VERSION ""

NS_ :

BS_:

BU_: L_3HKBD L_DIG L_FHPTC L_ATCU L_2HKBD L_PCM L_ATCU_vMON L_EVNT L_HKBD L_RHPTC

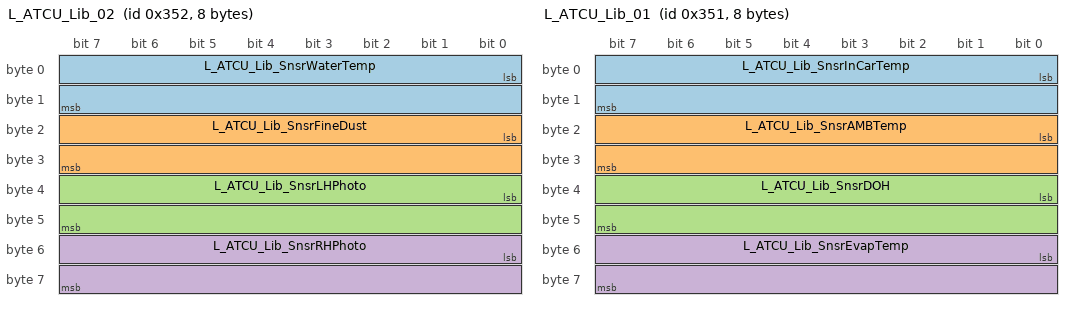
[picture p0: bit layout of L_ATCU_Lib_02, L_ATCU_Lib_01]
BO_ 850 L_ATCU_Lib_02: 8 L_ATCU
 SG_ L_ATCU_Lib_SnsrWaterTemp : 0|16@1+ (0.01,-48) [-48|200] "¡É"  L_ATCU_vMON
 SG_ L_ATCU_Lib_SnsrFineDust : 16|16@1+ (1,0) [0|255] ""  L_ATCU_vMON
 SG_ L_ATCU_Lib_SnsrLHPhoto : 32|16@1+ (0.001,0) [0|5] "V"  L_ATCU_vMON
 SG_ L_ATCU_Lib_SnsrRHPhoto : 48|16@1+ (0.001,0) [0|5] "V"  L_ATCU_vMON

BO_ 100 L_2HKBD_04: 8 L_2HKBD
 SG_ L_2HKBD_RrDrModeDnSw : 0|1@1+ (1,0) [0|0] ""  L_ATCU
 SG_ L_2HKBD_RrDrModeUpSw : 1|1@1+ (1,0) [0|0] ""  L_ATCU
 SG_ L_2HKBD_RrDrAutoSw : 10|1@1+ (1,0) [0|0] ""  L_ATCU
 SG_ L_2HKBD_Rr_OffSw : 11|1@1+ (1,0) [0|0] ""  L_ATCU
 SG_ L_2HKBD_RrSyncSw : 12|1@1+ (1,0) [0|0] ""  L_ATCU
 SG_ L_2HKBD_RrAcSw : 13|1@1+ (1,0) [0|0] ""  L_ATCU
 SG_ L_2HKBD_RLStHtrSwReq : 14|1@1+ (1,0) [0|0] ""  L_ATCU
 SG_ L_2HKBD_RLStVentSwReq : 15|1@1+ (1,0) [0|0] ""  L_ATCU
 SG_ L_2HKBD_RRStHtrSwReq : 16|1@1+ (1,0) [0|0] ""  L_ATCU
 SG_ L_2HKBD_RRStVentSwReq : 17|1@1+ (1,0) [0|0] ""  L_ATCU
 SG_ L_2HKBD_RrDrMultiAutoSw : 18|3@1+ (1,0) [0|0] ""  L_ATCU
 SG_ L_2HKBD_RrDrModeSw : 2|1@1+ (1,0) [0|0] ""  L_ATCU
 SG_ L_2HKBD_RrPsModeSw : 21|1@1+ (1,0) [0|0] ""  L_ATCU
 SG_ L_2HKBD_RrPsModeDnSw : 22|1@1+ (1,0) [0|0] ""  L_ATCU
 SG_ L_2HKBD_RrPsModeUpSw : 23|1@1+ (1,0) [0|0] ""  L_ATCU
 SG_ L_2HKBD_RrPsModeVentSw : 24|1@1+ (1,0) [0|0] ""  L_ATCU
 SG_ L_2HKBD_RrPsModeFloorSw : 25|1@1+ (1,0) [0|0] ""  L_ATCU
 SG_ L_2HKBD_RrPsModeBiLvlSw : 26|1@1+ (1,0) [0|0] ""  L_ATCU
 SG_ L_2HKBD_RrPsTempDnSw : 27|1@1+ (1,0) [0|0] ""  L_ATCU
 SG_ L_2HKBD_RrPsTempUpSw : 28|1@1+ (1,0) [0|0] ""  L_ATCU
 SG_ L_2HKBD_RrPsBlwUpSw : 29|1@1+ (1,0) [0|0] ""  L_ATCU
 SG_ L_2HKBD_RrDRModeVentSw : 3|1@1+ (1,0) [0|0] ""  L_ATCU
 SG_ L_2HKBD_RrPsBlwDnSw : 30|1@1+ (1,0) [0|0] ""  L_ATCU
 SG_ L_2HKBD_RrPsAutoSw : 31|1@1+ (1,0) [0|0] ""  L_ATCU
 SG_ L_2HKBD_RrPsMultiAutoSw : 32|3@1+ (1,0) [0|0] ""  L_ATCU
 SG_ L_2HKBD_RrDrBlwDnOffSw : 35|1@1+ (1,0) [0|0] ""  L_ATCU
 SG_ L_2HKBD_RrPsBlwDnOffSw : 36|1@1+ (1,0) [0|0] ""  L_ATCU
 SG_ L_2HKBD_RrOnOffSet : 37|2@1+ (1,0) [0|0] ""  L_ATCU
 SG_ L_2HKBD_RrDrblwUpMaxSw : 39|1@1+ (1,0) [0|0] ""  L_ATCU
 SG_ L_2HKBD_RrDrModeFloorSw : 4|1@1+ (1,0) [0|0] ""  L_ATCU
 SG_ L_2HKBD_RrPsblwUpMaxSw : 40|1@1+ (1,0) [0|0] ""  L_ATCU
 SG_ L_2HKBD_RrDrModeBiLvlSw : 5|1@1+ (1,0) [0|0] ""  L_ATCU
 SG_ L_2HKBD_RrDrTempDnSw : 6|1@1+ (1,0) [0|0] ""  L_ATCU
 SG_ L_2HKBD_RrDrTempUpSw : 7|1@1+ (1,0) [0|0] ""  L_ATCU
 SG_ L_2HKBD_RrDrBlwDnSw : 8|1@1+ (1,0) [0|0] ""  L_ATCU
 SG_ L_2HKBD_RrDrBlwUpSw : 9|1@1+ (1,0) [0|0] ""  L_ATCU

BO_ 849 L_ATCU_Lib_01: 8 L_ATCU
 SG_ L_ATCU_Lib_SnsrInCarTemp : 0|16@1+ (0.1,-40) [-40|60] "¡É"  L_ATCU_vMON
 SG_ L_ATCU_Lib_SnsrAMBTemp : 16|16@1+ (0.1,-40) [-40|60] "¡É"  L_ATCU_vMON
 SG_ L_ATCU_Lib_SnsrDOH : 32|16@1+ (1,0) [0|100] "%"  L_ATCU_vMON
 SG_ L_ATCU_Lib_SnsrEvapTemp : 48|16@1+ (0.1,-20) [-20|40] "¡É"  L_ATCU_vMON

BO_ 101 L_2HKBD_05: 8 L_2HKBD
 SG_ L_2HKBD_RrFlrDuctSnsr : 0|8@1+ (0.02,0) [0|0] "V"  L_ATCU
 SG_ L_2HKBD_RrVntDuctSnsr : 9|8@1+ (0.02,0) [0|0] "V"  L_ATCU

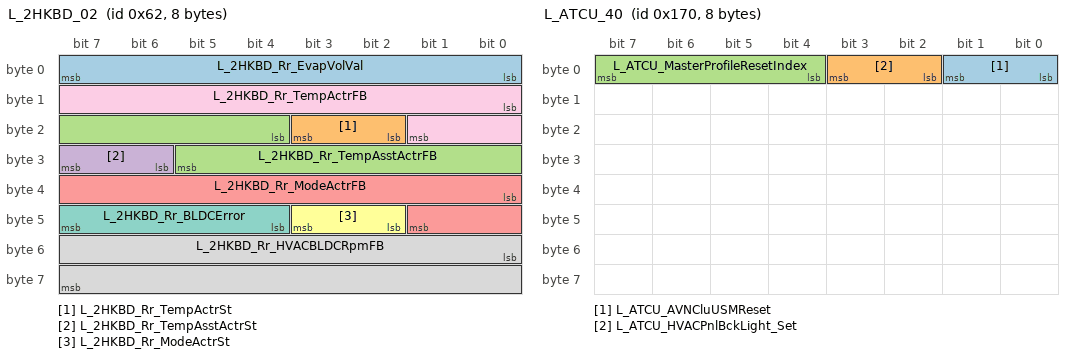
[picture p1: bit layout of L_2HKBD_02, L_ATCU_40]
BO_ 98 L_2HKBD_02: 8 L_2HKBD
 SG_ L_2HKBD_Rr_EvapVolVal : 0|8@1+ (0.02,0) [0|0] ""  L_ATCU
 SG_ L_2HKBD_Rr_TempActrSt : 18|2@1+ (1,0) [0|0] ""  L_ATCU
 SG_ L_2HKBD_Rr_TempAsstActrFB : 20|10@1+ (1,0) [0|0] ""  L_ATCU
 SG_ L_2HKBD_Rr_TempAsstActrSt : 30|2@1+ (1,0) [0|0] ""  L_ATCU
 SG_ L_2HKBD_Rr_ModeActrFB : 32|10@1+ (1,0) [0|0] ""  L_ATCU
 SG_ L_2HKBD_Rr_ModeActrSt : 42|2@1+ (1,0) [0|0] ""  L_ATCU
 SG_ L_2HKBD_Rr_BLDCError : 44|4@1+ (1,0) [0|0] ""  L_ATCU
 SG_ L_2HKBD_Rr_HVACBLDCRpmFB : 48|16@1+ (5,0) [0|0] "RPM"  L_ATCU
 SG_ L_2HKBD_Rr_TempActrFB : 8|10@1+ (1,0) [0|0] ""  L_ATCU

BO_ 855 L_ATCU_Lib_07: 8 L_ATCU
 SG_ L_ATCU_Lib_2ndAutoSw : 0|1@1+ (1,0) [0|1] ""  L_ATCU_vMON
 SG_ L_ATCU_Lib_2ndAutoUpSw : 1|1@1+ (1,0) [0|1] ""  L_ATCU_vMON
 SG_ L_ATCU_Lib_2LHTempUpSw : 10|1@1+ (1,0) [0|1] ""  L_ATCU_vMON
 SG_ L_ATCU_Lib_2LHTempDnSw : 11|1@1+ (1,0) [0|1] ""  L_ATCU_vMON
 SG_ L_ATCU_Lib_2RHTempUpSw : 12|1@1+ (1,0) [0|1] ""  L_ATCU_vMON
 SG_ L_ATCU_Lib_2RHTempDnSw : 13|1@1+ (1,0) [0|1] ""  L_ATCU_vMON
 SG_ L_ATCU_Lib_2ndSyncSw : 14|1@1+ (1,0) [0|1] ""  L_ATCU_vMON
 SG_ L_ATCU_Lib_2ndLockSw : 15|1@1+ (1,0) [0|1] ""  L_ATCU_vMON
 SG_ L_ATCU_Lib_2LHSeatHeatSw : 16|1@1+ (1,0) [0|1] ""  L_ATCU_vMON
 SG_ L_ATCU_Lib_2LHSeatVentSw : 17|1@1+ (1,0) [0|1] ""  L_ATCU_vMON
 SG_ L_ATCU_Lib_2RHSeatHeatSw : 18|1@1+ (1,0) [0|1] ""  L_ATCU_vMON
 SG_ L_ATCU_Lib_2RHSeatVentSw : 19|1@1+ (1,0) [0|1] ""  L_ATCU_vMON
 SG_ L_ATCU_Lib_2ndAutoDnSw : 2|1@1+ (1,0) [0|1] ""  L_ATCU_vMON
 SG_ L_ATCU_Lib_2LHSeatTumblerSw : 20|2@1+ (1,0) [0|3] ""  L_ATCU_vMON
 SG_ L_ATCU_Lib_2RHSeatTumblerSw : 22|2@1+ (1,0) [0|3] ""  L_ATCU_vMON
 SG_ L_ATCU_Lib_2ndOffSetSw : 24|2@1+ (1,0) [0|3] ""  L_ATCU_vMON
 SG_ L_ATCU_Lib_2ndAutoSetSw : 26|2@1+ (1,0) [0|3] ""  L_ATCU_vMON
 SG_ L_ATCU_Lib_2ndMultiAutoSetSw : 28|2@1+ (1,0) [0|3] ""  L_ATCU_vMON
 SG_ L_ATCU_Lib_2LHModSw : 3|1@1+ (1,0) [0|1] ""  L_ATCU_vMON
 SG_ L_ATCU_Lib_2ndACSetSw : 30|2@1+ (1,0) [0|3] ""  L_ATCU_vMON
 SG_ L_ATCU_Lib_2LHModSetSw : 32|4@1+ (1,0) [0|15] ""  L_ATCU_vMON
 SG_ L_ATCU_Lib_2LHBlrSetSw : 36|4@1+ (1,0) [0|15] ""  L_ATCU_vMON
 SG_ L_ATCU_Lib_2LHModUpSw : 4|1@1+ (1,0) [0|1] ""  L_ATCU_vMON
 SG_ L_ATCU_Lib_2LHTempSetSw : 40|8@1+ (1,0) [0|0] ""  L_ATCU_vMON
 SG_ L_ATCU_Lib_2RHTempSetSw : 48|8@1+ (1,0) [0|0] ""  L_ATCU_vMON
 SG_ L_ATCU_Lib_2LHModDnSw : 5|1@1+ (1,0) [0|1] ""  L_ATCU_vMON
 SG_ L_ATCU_Lib_DrvBlrClickCnt : 56|8@1+ (1,0) [0|255] ""  L_ATCU_vMON
 SG_ L_ATCU_Lib_2LHBlrUpSw : 6|1@1+ (1,0) [0|1] ""  L_ATCU_vMON
 SG_ L_ATCU_Lib_2LHBlrDnSw : 7|1@1+ (1,0) [0|1] ""  L_ATCU_vMON
 SG_ L_ATCU_Lib_2LHBlrDnOffReq : 8|1@1+ (1,0) [0|1] ""  L_ATCU_vMON
 SG_ L_ATCU_Lib_2ndACSw : 9|1@1+ (1,0) [0|1] ""  L_ATCU_vMON

BO_ 99 L_2HKBD_03: 8 L_2HKBD
 SG_ L_2HKBD_SwBtnTyp : 0|40@1+ (1,0) [0|0] ""  L_ATCU
 SG_ L_2HKBD_ResetOpSta : 62|2@1+ (1,0) [0|0] ""  L_ATCU

BO_ 368 L_ATCU_40: 8 L_ATCU
 SG_ L_ATCU_AVNCluUSMReset : 0|2@1+ (1,0) [0|0] ""  L_2HKBD,L_3HKBD,L_EVNT,L_HKBD
 SG_ L_ATCU_HVACPnlBckLight_Set : 2|2@1+ (1,0) [0|0] ""  L_2HKBD,L_3HKBD,L_EVNT,L_HKBD
 SG_ L_ATCU_MasterProfileResetIndex : 4|4@1+ (1,0) [0|0] ""  L_2HKBD,L_3HKBD,L_EVNT,L_HKBD

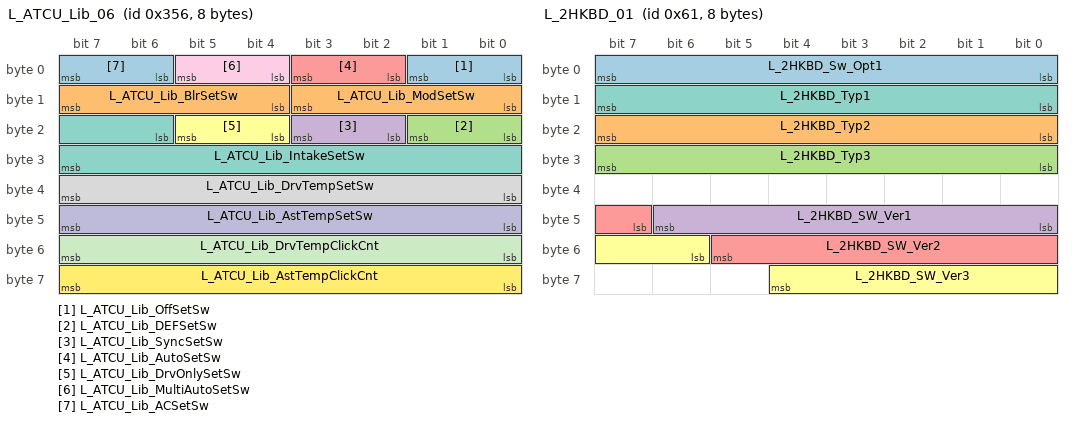
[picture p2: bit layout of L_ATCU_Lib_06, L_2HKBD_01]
BO_ 854 L_ATCU_Lib_06: 8 L_ATCU
 SG_ L_ATCU_Lib_OffSetSw : 0|2@1+ (1,0) [0|3] ""  L_ATCU_vMON
 SG_ L_ATCU_Lib_BlrSetSw : 12|4@1+ (1,0) [0|15] ""  L_ATCU_vMON
 SG_ L_ATCU_Lib_DEFSetSw : 16|2@1+ (1,0) [0|0] ""  L_ATCU_vMON
 SG_ L_ATCU_Lib_SyncSetSw : 18|2@1+ (1,0) [0|0] ""  L_ATCU_vMON
 SG_ L_ATCU_Lib_AutoSetSw : 2|2@1+ (1,0) [0|3] ""  L_ATCU_vMON
 SG_ L_ATCU_Lib_DrvOnlySetSw : 20|2@1+ (1,0) [0|0] ""  L_ATCU_vMON
 SG_ L_ATCU_Lib_IntakeSetSw : 22|10@1+ (1,0) [0|0] ""  L_ATCU_vMON
 SG_ L_ATCU_Lib_DrvTempSetSw : 32|8@1+ (1,0) [0|0] ""  L_ATCU_vMON
 SG_ L_ATCU_Lib_MultiAutoSetSw : 4|2@1+ (1,0) [0|3] ""  L_ATCU_vMON
 SG_ L_ATCU_Lib_AstTempSetSw : 40|8@1+ (1,0) [0|0] ""  L_ATCU_vMON
 SG_ L_ATCU_Lib_DrvTempClickCnt : 48|8@1+ (1,0) [0|255] ""  L_ATCU_vMON
 SG_ L_ATCU_Lib_AstTempClickCnt : 56|8@1+ (1,0) [0|255] ""  L_ATCU_vMON
 SG_ L_ATCU_Lib_ACSetSw : 6|2@1+ (1,0) [0|3] ""  L_ATCU_vMON
 SG_ L_ATCU_Lib_ModSetSw : 8|4@1+ (1,0) [0|15] ""  L_ATCU_vMON

BO_ 853 L_ATCU_Lib_05: 8 L_ATCU
 SG_ L_ATCU_Lib_OffSw : 0|1@1+ (1,0) [0|1] ""  L_ATCU_vMON
 SG_ L_ATCU_Lib_AutoSw : 1|1@1+ (1,0) [0|1] ""  L_ATCU_vMON
 SG_ L_ATCU_Lib_BlrDnOffReq : 10|1@1+ (1,0) [0|1] ""  L_ATCU_vMON
 SG_ L_ATCU_Lib_IntakeRECSw : 11|1@1+ (1,0) [0|1] ""  L_ATCU_vMON
 SG_ L_ATCU_Lib_IntakeFRESw : 12|1@1+ (1,0) [0|1] ""  L_ATCU_vMON
 SG_ L_ATCU_Lib_ACSw : 13|1@1+ (1,0) [0|1] ""  L_ATCU_vMON
 SG_ L_ATCU_Lib_DEFSw : 14|1@1+ (1,0) [0|1] ""  L_ATCU_vMON
 SG_ L_ATCU_Lib_DrvTempUpSw : 15|1@1+ (1,0) [0|1] ""  L_ATCU_vMON
 SG_ L_ATCU_Lib_DrvTempDnSw : 16|1@1+ (1,0) [0|1] ""  L_ATCU_vMON
 SG_ L_ATCU_Lib_AstTempUpSw : 17|1@1+ (1,0) [0|1] ""  L_ATCU_vMON
 SG_ L_ATCU_Lib_AstTempDnSw : 18|1@1+ (1,0) [0|1] ""  L_ATCU_vMON
 SG_ L_ATCU_Lib_SyncSw : 19|1@1+ (1,0) [0|1] ""  L_ATCU_vMON
 SG_ L_ATCU_Lib_ModSw : 2|1@1+ (1,0) [0|1] ""  L_ATCU_vMON
 SG_ L_ATCU_Lib_DrvOnlySw : 20|1@1+ (1,0) [0|1] ""  L_ATCU_vMON
 SG_ L_ATCU_Lib_ClimateSw : 21|1@1+ (1,0) [0|1] ""  L_ATCU_vMON
 SG_ L_ATCU_Lib_RearDEFSw : 22|1@1+ (1,0) [0|1] ""  L_ATCU_vMON
 SG_ L_ATCU_Lib_StrWhlSw : 23|1@1+ (1,0) [0|1] ""  L_ATCU_vMON
 SG_ L_ATCU_Lib_DrvSeatHeatSw : 24|1@1+ (1,0) [0|1] ""  L_ATCU_vMON
 SG_ L_ATCU_Lib_DrvSeatVentSw : 25|1@1+ (1,0) [0|1] ""  L_ATCU_vMON
 SG_ L_ATCU_Lib_AstSeatHeatSw : 26|1@1+ (1,0) [0|1] ""  L_ATCU_vMON
 SG_ L_ATCU_Lib_AstSeatVentSw : 27|1@1+ (1,0) [0|1] ""  L_ATCU_vMON
 SG_ L_ATCU_Lib_DrvSeatTumblerSw : 28|2@1+ (1,0) [0|3] ""  L_ATCU_vMON
 SG_ L_ATCU_Lib_ModUpSw : 3|1@1+ (1,0) [0|1] ""  L_ATCU_vMON
 SG_ L_ATCU_Lib_AstSeatTumblerSw : 30|2@1+ (1,0) [0|3] ""  L_ATCU_vMON
 SG_ L_ATCU_Lib_2ndSyncSetSw : 32|2@1+ (1,0) [0|0] ""  L_ATCU_vMON
 SG_ L_ATCU_Lib_2ndOffSw : 34|1@1+ (1,0) [0|0] ""  L_ATCU_vMON
 SG_ L_ATCU_Lib_2ndLockSetSw : 36|2@1+ (1,0) [0|0] ""  L_ATCU_vMON
 SG_ L_ATCU_Lib_ModDnSw : 4|1@1+ (1,0) [0|1] ""  L_ATCU_vMON
 SG_ L_ATCU_Lib_BlrUpSw : 8|1@1+ (1,0) [0|1] ""  L_ATCU_vMON
 SG_ L_ATCU_Lib_BlrDnSw : 9|1@1+ (1,0) [0|1] ""  L_ATCU_vMON

BO_ 97 L_2HKBD_01: 8 L_2HKBD
 SG_ L_2HKBD_Sw_Opt1 : 0|8@1+ (1,0) [0|0] ""  L_ATCU
 SG_ L_2HKBD_Typ2 : 16|8@1+ (1,0) [0|0] ""  L_ATCU
 SG_ L_2HKBD_Typ3 : 24|8@1+ (1,0) [0|0] ""  L_ATCU
 SG_ L_2HKBD_SW_Ver1 : 40|7@1+ (1,0) [0|0] ""  L_ATCU_vMON
 SG_ L_2HKBD_SW_Ver2 : 47|7@1+ (1,0) [0|0] ""  L_ATCU_vMON
 SG_ L_2HKBD_SW_Ver3 : 54|7@1+ (1,0) [0|0] ""  L_ATCU_vMON
 SG_ L_2HKBD_Typ1 : 8|8@1+ (1,0) [0|0] ""  L_ATCU

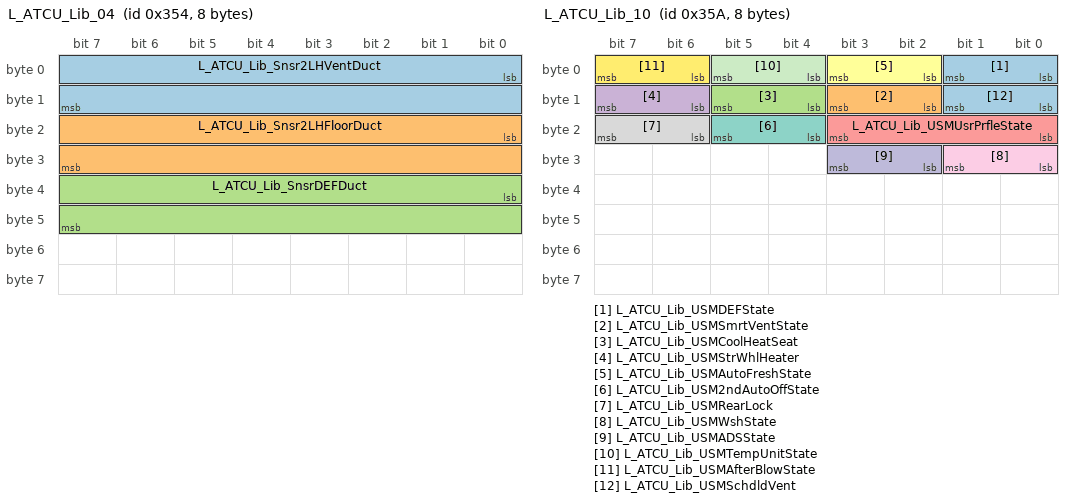
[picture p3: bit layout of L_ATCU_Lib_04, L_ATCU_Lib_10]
BO_ 852 L_ATCU_Lib_04: 8 L_ATCU
 SG_ L_ATCU_Lib_Snsr2LHVentDuct : 0|16@1+ (0.1,-40) [-40|120] "¡É"  L_ATCU_vMON
 SG_ L_ATCU_Lib_Snsr2LHFloorDuct : 16|16@1+ (0.1,-40) [-40|120] "¡É"  L_ATCU_vMON
 SG_ L_ATCU_Lib_SnsrDEFDuct : 32|16@1+ (0.1,-40) [-40|120] "¡É"  L_ATCU_vMON

BO_ 859 L_ATCU_Lib_11: 8 L_ATCU
 SG_ L_ATCU_Lib_Opt2LHModSwTyp : 0|2@1+ (1,0) [0|3] ""  L_ATCU_vMON
 SG_ L_ATCU_Lib_Opt2ndModBtn : 10|2@1+ (1,0) [0|3] ""  L_ATCU_vMON
 SG_ L_ATCU_Lib_Opt2ndOffSwTyp : 12|2@1+ (1,0) [0|3] ""  L_ATCU_vMON
 SG_ L_ATCU_Lib_Opt2ndTmpBtn : 14|2@1+ (1,0) [0|3] ""  L_ATCU_vMON
 SG_ L_ATCU_Lib_OptADS : 16|1@1+ (1,0) [0|1] ""  L_ATCU_vMON
 SG_ L_ATCU_Lib_OptAfterBlow : 17|1@1+ (1,0) [0|1] ""  L_ATCU_vMON
 SG_ L_ATCU_Lib_OptAutoStep : 18|2@1+ (1,0) [0|3] ""  L_ATCU_vMON
 SG_ L_ATCU_Lib_Opt2ndAutoBtn : 2|2@1+ (1,0) [0|3] ""  L_ATCU_vMON
 SG_ L_ATCU_Lib_OptAutoSwTyp : 20|1@1+ (1,0) [0|1] ""  L_ATCU_vMON
 SG_ L_ATCU_Lib_OptBATCoolingTyp : 21|2@1+ (1,0) [0|3] ""  L_ATCU_vMON
 SG_ L_ATCU_Lib_OptBlrSwKnob : 23|1@1+ (1,0) [0|1] ""  L_ATCU_vMON
 SG_ L_ATCU_Lib_OptComp : 24|3@1+ (1,0) [0|7] ""  L_ATCU_vMON
 SG_ L_ATCU_Lib_OptDrvHndSide : 27|1@1+ (1,0) [0|1] ""  L_ATCU_vMON
 SG_ L_ATCU_Lib_OptDrvOnly : 28|1@1+ (1,0) [0|1] ""  L_ATCU_vMON
 SG_ L_ATCU_Lib_OptFineDust : 29|1@1+ (1,0) [0|1] ""  L_ATCU_vMON
 SG_ L_ATCU_Lib_OptCoolHeatSeat : 30|2@1+ (1,0) [0|3] ""  L_ATCU_vMON
 SG_ L_ATCU_Lib_OptPTCTyp : 32|2@1+ (1,0) [0|3] ""  L_ATCU_vMON
 SG_ L_ATCU_Lib_OptLCDDisp : 34|2@1+ (1,0) [0|3] ""  L_ATCU_vMON
 SG_ L_ATCU_Lib_OptModSwTyp : 36|2@1+ (1,0) [0|3] ""  L_ATCU_vMON
 SG_ L_ATCU_Lib_OptOffSwTyp : 38|2@1+ (1,0) [0|3] ""  L_ATCU_vMON
 SG_ L_ATCU_Lib_Opt2ndAutoStep : 4|2@1+ (1,0) [0|3] ""  L_ATCU_vMON
 SG_ L_ATCU_Lib_OptNetworkTyp : 40|3@1+ (1,0) [0|7] ""  L_ATCU_vMON
 SG_ L_ATCU_Lib_OptPTCStep : 43|2@1+ (1,0) [0|3] ""  L_ATCU_vMON
 SG_ L_ATCU_Lib_OptPTG : 45|1@1+ (1,0) [0|1] ""  L_ATCU_vMON
 SG_ L_ATCU_Lib_OptROATyp : 46|1@1+ (1,0) [0|1] ""  L_ATCU_vMON
 SG_ L_ATCU_Lib_OptVRLED : 47|1@1+ (1,0) [0|1] ""  L_ATCU_vMON
 SG_ L_ATCU_Lib_OptRgn : 48|4@1+ (1,0) [0|15] ""  L_ATCU_vMON
 SG_ L_ATCU_Lib_OptSchdldVent : 52|1@1+ (1,0) [0|1] ""  L_ATCU_vMON
 SG_ L_ATCU_Lib_OptIntakeSwTyp : 53|1@1+ (1,0) [0|1] ""  L_ATCU_vMON
 SG_ L_ATCU_Lib_OptStrHeat : 54|2@1+ (1,0) [0|3] ""  L_ATCU_vMON
 SG_ L_ATCU_Lib_OptSync : 56|1@1+ (1,0) [0|1] ""  L_ATCU_vMON
 SG_ L_ATCU_Lib_OptTempSwKnob : 57|1@1+ (1,0) [0|1] ""  L_ATCU_vMON
 SG_ L_ATCU_Lib_OptThermostat : 58|1@1+ (1,0) [0|1] ""  L_ATCU_vMON
 SG_ L_ATCU_Lib_OptVehTyp : 59|3@1+ (1,0) [0|7] ""  L_ATCU_vMON
 SG_ L_ATCU_Lib_Opt2ndAutoSwTyp : 6|1@1+ (1,0) [0|1] ""  L_ATCU_vMON
 SG_ L_ATCU_Lib_OptWheelDrivePos : 62|2@1+ (1,0) [0|3] ""  L_ATCU_vMON
 SG_ L_ATCU_Lib_Opt2ndTempSwKnob : 7|1@1+ (1,0) [0|1] ""  L_ATCU_vMON
 SG_ L_ATCU_Lib_Opt2ndBlrBtn : 8|2@1+ (1,0) [0|3] ""  L_ATCU_vMON

BO_ 858 L_ATCU_Lib_10: 8 L_ATCU
 SG_ L_ATCU_Lib_USMDEFState : 0|2@1+ (1,0) [0|1] ""  L_ATCU_vMON
 SG_ L_ATCU_Lib_USMSmrtVentState : 10|2@1+ (1,0) [0|3] ""  L_ATCU_vMON
 SG_ L_ATCU_Lib_USMCoolHeatSeat : 12|2@1+ (1,0) [0|3] ""  L_ATCU_vMON
 SG_ L_ATCU_Lib_USMStrWhlHeater : 14|2@1+ (1,0) [0|3] ""  L_ATCU_vMON
 SG_ L_ATCU_Lib_USMUsrPrfleState : 16|4@1+ (1,0) [0|15] ""  L_ATCU_vMON
 SG_ L_ATCU_Lib_USMAutoFreshState : 2|2@1+ (1,0) [0|1] ""  L_ATCU_vMON
 SG_ L_ATCU_Lib_USM2ndAutoOffState : 20|2@1+ (1,0) [0|3] ""  L_ATCU_vMON
 SG_ L_ATCU_Lib_USMRearLock : 22|2@1+ (1,0) [0|3] ""  L_ATCU_vMON
 SG_ L_ATCU_Lib_USMWshState : 24|2@1+ (1,0) [0|1] ""  L_ATCU_vMON
 SG_ L_ATCU_Lib_USMADSState : 26|2@1+ (1,0) [0|1] ""  L_ATCU_vMON
 SG_ L_ATCU_Lib_USMTempUnitState : 4|2@1+ (1,0) [0|3] ""  L_ATCU_vMON
 SG_ L_ATCU_Lib_USMAfterBlowState : 6|2@1+ (1,0) [0|3] ""  L_ATCU_vMON
 SG_ L_ATCU_Lib_USMSchdldVent : 8|2@1+ (1,0) [0|3] ""  L_ATCU_vMON

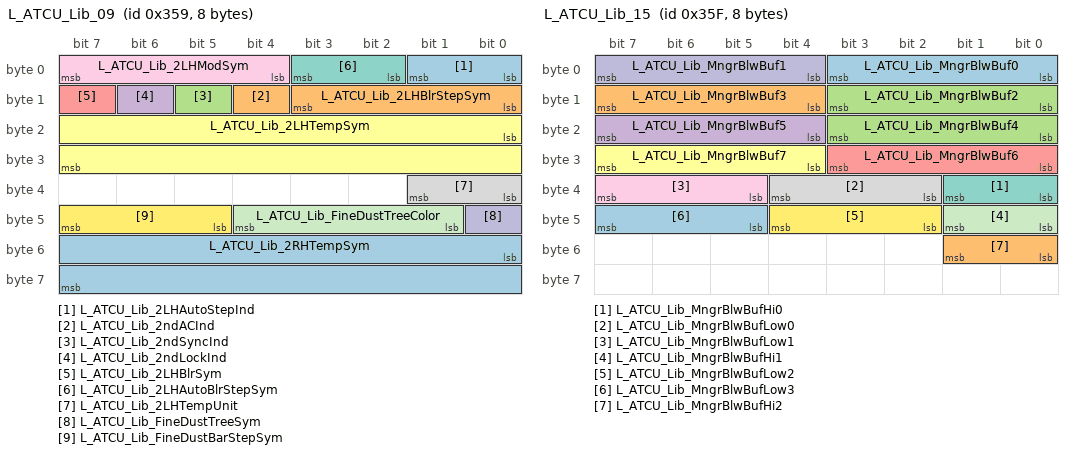
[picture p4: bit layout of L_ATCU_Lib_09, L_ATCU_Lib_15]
BO_ 857 L_ATCU_Lib_09: 8 L_ATCU
 SG_ L_ATCU_Lib_2LHAutoStepInd : 0|2@1+ (1,0) [0|3] ""  L_ATCU_vMON
 SG_ L_ATCU_Lib_2ndACInd : 12|1@1+ (1,0) [0|1] ""  L_ATCU_vMON
 SG_ L_ATCU_Lib_2ndSyncInd : 13|1@1+ (1,0) [0|1] ""  L_ATCU_vMON
 SG_ L_ATCU_Lib_2ndLockInd : 14|1@1+ (1,0) [0|1] ""  L_ATCU_vMON
 SG_ L_ATCU_Lib_2LHBlrSym : 15|1@1+ (1,0) [0|1] ""  L_ATCU_vMON
 SG_ L_ATCU_Lib_2LHTempSym : 16|16@1+ (1,0) [0|65535] ""  L_ATCU_vMON
 SG_ L_ATCU_Lib_2LHAutoBlrStepSym : 2|2@1+ (1,0) [0|3] ""  L_ATCU_vMON
 SG_ L_ATCU_Lib_2LHTempUnit : 32|2@1+ (1,0) [0|3] ""  L_ATCU_vMON
 SG_ L_ATCU_Lib_2LHModSym : 4|4@1+ (1,0) [0|15] ""  L_ATCU_vMON
 SG_ L_ATCU_Lib_FineDustTreeSym : 40|1@1+ (1,0) [0|1] ""  L_ATCU_vMON
 SG_ L_ATCU_Lib_FineDustTreeColor : 41|4@1+ (1,0) [0|15] ""  L_ATCU_vMON
 SG_ L_ATCU_Lib_FineDustBarStepSym : 45|3@1+ (1,0) [0|7] ""  L_ATCU_vMON
 SG_ L_ATCU_Lib_2RHTempSym : 48|16@1+ (1,0) [0|0] ""  L_ATCU_vMON
 SG_ L_ATCU_Lib_2LHBlrStepSym : 8|4@1+ (1,0) [0|15] ""  L_ATCU_vMON

BO_ 856 L_ATCU_Lib_08: 8 L_ATCU
 SG_ L_ATCU_Lib_AutoStepInd : 0|2@1+ (1,0) [0|3] ""  L_ATCU_vMON
 SG_ L_ATCU_Lib_BlrSym : 10|1@1+ (1,0) [0|1] ""  L_ATCU_vMON
 SG_ L_ATCU_Lib_BlrStepSym : 11|4@1+ (1,0) [0|15] ""  L_ATCU_vMON
 SG_ L_ATCU_Lib_IntakeRECInd : 15|1@1+ (1,0) [0|1] ""  L_ATCU_vMON
 SG_ L_ATCU_Lib_IntakeFREInd : 16|1@1+ (1,0) [0|1] ""  L_ATCU_vMON
 SG_ L_ATCU_Lib_ACInd : 17|1@1+ (1,0) [0|1] ""  L_ATCU_vMON
 SG_ L_ATCU_Lib_DEFInd : 18|1@1+ (1,0) [0|1] ""  L_ATCU_vMON
 SG_ L_ATCU_Lib_SyncInd : 19|1@1+ (1,0) [0|1] ""  L_ATCU_vMON
 SG_ L_ATCU_Lib_AutoBlrStepSym : 2|2@1+ (1,0) [0|3] ""  L_ATCU_vMON
 SG_ L_ATCU_Lib_DrvOnly : 20|1@1+ (1,0) [0|1] ""  L_ATCU_vMON
 SG_ L_ATCU_Lib_ADSSym : 21|1@1+ (1,0) [0|1] ""  L_ATCU_vMON
 SG_ L_ATCU_Lib_ModVentInd : 22|1@1+ (1,0) [0|1] ""  L_ATCU_vMON
 SG_ L_ATCU_Lib_DrvTempSym : 24|16@1+ (1,0) [0|65535] ""  L_ATCU_vMON
 SG_ L_ATCU_Lib_ModSym : 4|4@1+ (1,0) [0|15] ""  L_ATCU_vMON
 SG_ L_ATCU_Lib_AstTempSym : 40|16@1+ (1,0) [0|65535] ""  L_ATCU_vMON
 SG_ L_ATCU_Lib_DrvTempUnitSym : 56|2@1+ (1,0) [0|3] ""  L_ATCU_vMON
 SG_ L_ATCU_Lib_ModFloorInd : 8|1@1+ (1,0) [0|1] ""  L_ATCU_vMON
 SG_ L_ATCU_Lib_ModDEFInd : 9|1@1+ (1,0) [0|1] ""  L_ATCU_vMON

BO_ 863 L_ATCU_Lib_15: 8 L_ATCU
 SG_ L_ATCU_Lib_MngrBlwBuf0 : 0|4@1+ (1,0) [0|15] ""  L_ATCU_vMON
 SG_ L_ATCU_Lib_MngrBlwBuf3 : 12|4@1+ (1,0) [0|15] ""  L_ATCU_vMON
 SG_ L_ATCU_Lib_MngrBlwBuf4 : 16|4@1+ (1,0) [0|15] ""  L_ATCU_vMON
 SG_ L_ATCU_Lib_MngrBlwBuf5 : 20|4@1+ (1,0) [0|15] ""  L_ATCU_vMON
 SG_ L_ATCU_Lib_MngrBlwBuf6 : 24|4@1+ (1,0) [0|15] ""  L_ATCU_vMON
 SG_ L_ATCU_Lib_MngrBlwBuf7 : 28|4@1+ (1,0) [0|15] ""  L_ATCU_vMON
 SG_ L_ATCU_Lib_MngrBlwBufHi0 : 32|2@1+ (1,0) [0|3] ""  L_ATCU_vMON
 SG_ L_ATCU_Lib_MngrBlwBufLow0 : 34|3@1+ (1,0) [0|7] ""  L_ATCU_vMON
 SG_ L_ATCU_Lib_MngrBlwBufLow1 : 37|3@1+ (1,0) [0|7] ""  L_ATCU_vMON
 SG_ L_ATCU_Lib_MngrBlwBuf1 : 4|4@1+ (1,0) [0|15] ""  L_ATCU_vMON
 SG_ L_ATCU_Lib_MngrBlwBufHi1 : 40|2@1+ (1,0) [0|3] ""  L_ATCU_vMON
 SG_ L_ATCU_Lib_MngrBlwBufLow2 : 42|3@1+ (1,0) [0|7] ""  L_ATCU_vMON
 SG_ L_ATCU_Lib_MngrBlwBufLow3 : 45|3@1+ (1,0) [0|7] ""  L_ATCU_vMON
 SG_ L_ATCU_Lib_MngrBlwBufHi2 : 48|2@1+ (1,0) [0|3] ""  L_ATCU_vMON
 SG_ L_ATCU_Lib_MngrBlwBuf2 : 8|4@1+ (1,0) [0|15] ""  L_ATCU_vMON

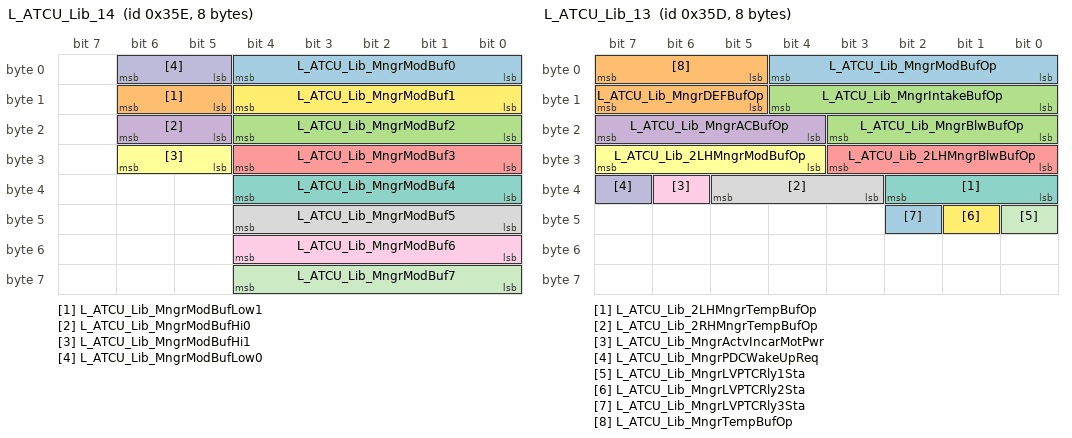
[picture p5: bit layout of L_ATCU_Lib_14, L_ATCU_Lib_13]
BO_ 862 L_ATCU_Lib_14: 8 L_ATCU
 SG_ L_ATCU_Lib_MngrModBuf0 : 0|5@1+ (1,0) [0|31] ""  L_ATCU_vMON
 SG_ L_ATCU_Lib_MngrModBufLow1 : 13|2@1+ (1,0) [0|3] ""  L_ATCU_vMON
 SG_ L_ATCU_Lib_MngrModBuf2 : 16|5@1+ (1,0) [0|31] ""  L_ATCU_vMON
 SG_ L_ATCU_Lib_MngrModBufHi0 : 21|2@1+ (1,0) [0|3] ""  L_ATCU_vMON
 SG_ L_ATCU_Lib_MngrModBuf3 : 24|5@1+ (1,0) [0|31] ""  L_ATCU_vMON
 SG_ L_ATCU_Lib_MngrModBufHi1 : 29|2@1+ (1,0) [0|3] ""  L_ATCU_vMON
 SG_ L_ATCU_Lib_MngrModBuf4 : 32|5@1+ (1,0) [0|31] ""  L_ATCU_vMON
 SG_ L_ATCU_Lib_MngrModBuf5 : 40|5@1+ (1,0) [0|31] ""  L_ATCU_vMON
 SG_ L_ATCU_Lib_MngrModBuf6 : 48|5@1+ (1,0) [0|31] ""  L_ATCU_vMON
 SG_ L_ATCU_Lib_MngrModBufLow0 : 5|2@1+ (1,0) [0|3] ""  L_ATCU_vMON
 SG_ L_ATCU_Lib_MngrModBuf7 : 56|5@1+ (1,0) [0|31] ""  L_ATCU_vMON
 SG_ L_ATCU_Lib_MngrModBuf1 : 8|5@1+ (1,0) [0|31] ""  L_ATCU_vMON

BO_ 861 L_ATCU_Lib_13: 8 L_ATCU
 SG_ L_ATCU_Lib_MngrModBufOp : 0|5@1+ (1,0) [0|31] ""  L_ATCU_vMON
 SG_ L_ATCU_Lib_MngrDEFBufOp : 13|3@1+ (1,0) [0|7] ""  L_ATCU_vMON
 SG_ L_ATCU_Lib_MngrBlwBufOp : 16|4@1+ (1,0) [0|15] ""  L_ATCU_vMON
 SG_ L_ATCU_Lib_MngrACBufOp : 20|4@1+ (1,0) [0|15] ""  L_ATCU_vMON
 SG_ L_ATCU_Lib_2LHMngrBlwBufOp : 24|4@1+ (1,0) [0|15] ""  L_ATCU_vMON
 SG_ L_ATCU_Lib_2LHMngrModBufOp : 28|4@1+ (1,0) [0|15] ""  L_ATCU_vMON
 SG_ L_ATCU_Lib_2LHMngrTempBufOp : 32|3@1+ (1,0) [0|7] ""  L_ATCU_vMON
 SG_ L_ATCU_Lib_2RHMngrTempBufOp : 35|3@1+ (1,0) [0|7] ""  L_ATCU_vMON
 SG_ L_ATCU_Lib_MngrActvIncarMotPwr : 38|1@1+ (1,0) [0|1] ""  L_ATCU_vMON
 SG_ L_ATCU_Lib_MngrPDCWakeUpReq : 39|1@1+ (1,0) [0|1] ""  L_ATCU_vMON
 SG_ L_ATCU_Lib_MngrLVPTCRly1Sta : 40|1@1+ (1,0) [0|1] ""  L_ATCU_vMON
 SG_ L_ATCU_Lib_MngrLVPTCRly2Sta : 41|1@1+ (1,0) [0|1] ""  L_ATCU_vMON
 SG_ L_ATCU_Lib_MngrLVPTCRly3Sta : 42|1@1+ (1,0) [0|1] ""  L_ATCU_vMON
 SG_ L_ATCU_Lib_MngrTempBufOp : 5|3@1+ (1,0) [0|7] ""  L_ATCU_vMON
 SG_ L_ATCU_Lib_MngrIntakeBufOp : 8|5@1+ (1,0) [0|31] ""  L_ATCU_vMON

CM_ BO_ 97 "[PE] Periodic and On Event";
CM_ SG_ 97 L_2HKBD_Sw_Opt1 "2HKBD_Switch_Option1";
CM_ SG_ 97 L_2HKBD_Typ2 "2HKBD_Type2";
CM_ SG_ 97 L_2HKBD_Typ3 "2HKBD_Type3";
CM_ SG_ 97 L_2HKBD_SW_Ver1 "2HKBD_SoftWare_Version1";
CM_ SG_ 97 L_2HKBD_SW_Ver2 "2HKBD_SoftWare_Version2";
CM_ SG_ 97 L_2HKBD_SW_Ver3 "2HKBD_SoftWare_Version3";
CM_ SG_ 97 L_2HKBD_Typ1 "2HKBD_Type1";
CM_ BO_ 98 "[P] Periodic";
CM_ SG_ 98 L_2HKBD_Rr_EvapVolVal "2HKBD_Rear_EvaporatorVoltageValue";
CM_ SG_ 98 L_2HKBD_Rr_TempActrSt "2HKBD_Rear_TemperatureActuatorStatus";
CM_ SG_ 98 L_2HKBD_Rr_TempAsstActrFB "2HKBD_Rear_TemperatureAssistActuatorFeedback";
CM_ SG_ 98 L_2HKBD_Rr_TempAsstActrSt "2HKBD_Rear_TemperatureAssistActuatorStatus";
CM_ SG_ 98 L_2HKBD_Rr_ModeActrFB "2HKBD_Rear_ModeActuatorFeedback";
CM_ SG_ 98 L_2HKBD_Rr_ModeActrSt "2HKBD_Rear_ModeActuatorStatus";
CM_ SG_ 98 L_2HKBD_Rr_BLDCError "2HKBD_Rear_BLDCError";
CM_ SG_ 98 L_2HKBD_Rr_HVACBLDCRpmFB "2HKBD_Rear_HVACBLDCRpmFeedBack";
CM_ SG_ 98 L_2HKBD_Rr_TempActrFB "2HKBD_Rear_TemperatureActuatorFeedback";
CM_ BO_ 99 "[PE] Periodic and On Event";
CM_ SG_ 99 L_2HKBD_SwBtnTyp "2HKBD-SwitchButtonType";
CM_ SG_ 99 L_2HKBD_ResetOpSta "This signal indicates whether the reset operation has been completed or not";
CM_ BO_ 100 "[PE] Periodic and On Event";
CM_ SG_ 100 L_2HKBD_RrDrModeDnSw "2HKBD_RearDriverModeDownSwitch";
CM_ SG_ 100 L_2HKBD_RrDrModeUpSw "2HKBD_RearDriverModeUpSwitch";
CM_ SG_ 100 L_2HKBD_RrDrAutoSw "2HKBD_RearDriverAutoSwitch";
CM_ SG_ 100 L_2HKBD_Rr_OffSw "2HKBD_Rear_OffSwitch";
CM_ SG_ 100 L_2HKBD_RrSyncSw "2HKBD_Rear_SyncSwitch";
CM_ SG_ 100 L_2HKBD_RrAcSw "2HKBD_Rear_ACSwitch";
CM_ SG_ 100 L_2HKBD_RLStHtrSwReq "2HKBD_RearLeftSeatHeaterSwitchRequest";
CM_ SG_ 100 L_2HKBD_RLStVentSwReq "2HKBD_RearLeftSeatVentSwitchRequest";
CM_ SG_ 100 L_2HKBD_RRStHtrSwReq "2HKBD_RearRightSeatHeaterSwitchRequest";
CM_ SG_ 100 L_2HKBD_RRStVentSwReq "2HKBD_RearRightSeatVentSwitchRequest";
CM_ SG_ 100 L_2HKBD_RrDrMultiAutoSw "2HKBD_RearDriverMultiAutoSwitch";
CM_ SG_ 100 L_2HKBD_RrDrModeSw "2HKBD_RearDriverModeSwitch";
CM_ SG_ 100 L_2HKBD_RrPsModeSw "2HKBD_RearPassengerModeSwitch";
CM_ SG_ 100 L_2HKBD_RrPsModeDnSw "2HKBD_RearPassengerModeDownSwitch";
CM_ SG_ 100 L_2HKBD_RrPsModeUpSw "2HKBD_RearPassengerModeUpSwitch";
CM_ SG_ 100 L_2HKBD_RrPsModeVentSw "2HKBD_RearPassengerModeVentSwitch";
CM_ SG_ 100 L_2HKBD_RrPsModeFloorSw "2HKBD_RearPassengerModeFloorSwitch";
CM_ SG_ 100 L_2HKBD_RrPsModeBiLvlSw "2HKBD_RearPassengerModeBiLevelSwitch";
CM_ SG_ 100 L_2HKBD_RrPsTempDnSw "2HKBD_RearPassengerTemperatureDownSwitch";
CM_ SG_ 100 L_2HKBD_RrPsTempUpSw "2HKBD_RearPassengerTemperatureUpSwitch";
CM_ SG_ 100 L_2HKBD_RrPsBlwUpSw "2HKBD_RearPassengerBlowerUpSwitch";
CM_ SG_ 100 L_2HKBD_RrDRModeVentSw "2HKBD_RearDriverModeVentSwitch";
CM_ SG_ 100 L_2HKBD_RrPsBlwDnSw "2HKBD_RearPassengerBlowerDownSwitch";
CM_ SG_ 100 L_2HKBD_RrPsAutoSw "2HKBD_RearPassengerAutoSwitch";
CM_ SG_ 100 L_2HKBD_RrPsMultiAutoSw "2HKBD_RearPassengerMultiAutoSwitch";
CM_ SG_ 100 L_2HKBD_RrDrBlwDnOffSw "2HKBD_RearDriverBlowerDownOffSwitch";
CM_ SG_ 100 L_2HKBD_RrPsBlwDnOffSw "2HKBD_ReaerPassengerBlowerDownOffSwitch";
CM_ SG_ 100 L_2HKBD_RrOnOffSet "2HKBD_RearOnOffSet";
CM_ SG_ 100 L_2HKBD_RrDrblwUpMaxSw "L_2HKBD_RrDrblwUpMaxSw";
CM_ SG_ 100 L_2HKBD_RrDrModeFloorSw "2HKBD_RearDriverModeFloorSwitch";
CM_ SG_ 100 L_2HKBD_RrPsblwUpMaxSw "L_2HKBD_RrPsblwUpMaxSw";
CM_ SG_ 100 L_2HKBD_RrDrModeBiLvlSw "2HKBD_RearDriverModeBiLevelSwitch";
CM_ SG_ 100 L_2HKBD_RrDrTempDnSw "2HKBD_RearDriverTempDownSwitch";
CM_ SG_ 100 L_2HKBD_RrDrTempUpSw "2HKBD_RearDriverTempUpSwitch";
CM_ SG_ 100 L_2HKBD_RrDrBlwDnSw "2HKBD_RearDriverBlowerDownSwitch";
CM_ SG_ 100 L_2HKBD_RrDrBlwUpSw "2HKBD_RearDriverBlowerUpSwitch";
CM_ BO_ 101 "[P] Periodic";
CM_ SG_ 101 L_2HKBD_RrFlrDuctSnsr "2HKBD_RearFloorDuctSensor";
CM_ SG_ 101 L_2HKBD_RrVntDuctSnsr "2HKBD_RearVentDuctSensor";
CM_ BO_ 368 "[EC] On Event and On Change";
CM_ SG_ 368 L_ATCU_AVNCluUSMReset "Request to reset all USM service";
CM_ SG_ 368 L_ATCU_HVACPnlBckLight_Set "Vehicle API HVAC Control Panel BackLight Set";
CM_ SG_ 368 L_ATCU_MasterProfileResetIndex "L_ATCU_HUMasterProfile_ResetIndex";
CM_ BO_ 849 "[PE] Periodic and On Event";
CM_ SG_ 849 L_ATCU_Lib_SnsrInCarTemp "ATCU Library InCarTemp Filtering Value";
CM_ SG_ 849 L_ATCU_Lib_SnsrAMBTemp "ATCU Library AmbTemp Filtering Value";
CM_ SG_ 849 L_ATCU_Lib_SnsrDOH "ATCU Library DOH Filtering Value";
CM_ SG_ 849 L_ATCU_Lib_SnsrEvapTemp "ATCU Library EvapTemp Filtering Value";
CM_ BO_ 850 "[PE] Periodic and On Event";
CM_ SG_ 850 L_ATCU_Lib_SnsrWaterTemp "ATCU Library WaterTemp Filtering Value";
CM_ SG_ 850 L_ATCU_Lib_SnsrFineDust "ATCU Library FineDust Filtering Value";
CM_ SG_ 850 L_ATCU_Lib_SnsrLHPhoto "ATCU Library Photo Sensor(Drv) Filtering Value";
CM_ SG_ 850 L_ATCU_Lib_SnsrRHPhoto "ATCU Library Photo Sensor(Ast) Filtering Value";
CM_ BO_ 852 "[PE] Periodic and On Event";
CM_ SG_ 852 L_ATCU_Lib_Snsr2LHVentDuct "ATCU Library 2nd LH Vent Duct Temp Filtering Value";
CM_ SG_ 852 L_ATCU_Lib_Snsr2LHFloorDuct "ATCU Library 2nd LH Floor Duct Temp Filtering Value";
CM_ SG_ 852 L_ATCU_Lib_SnsrDEFDuct "ATCU Library DEF Duct Temp Filtering Value";
CM_ BO_ 853 "[PE] Periodic and On Event";
CM_ SG_ 853 L_ATCU_Lib_OffSw "ATCU Library Off Switch";
CM_ SG_ 853 L_ATCU_Lib_AutoSw "ATCU Library Auto Switch";
CM_ SG_ 853 L_ATCU_Lib_BlrDnOffReq "ATCU Library Blower DownOff Switch (DownOff Type)";
CM_ SG_ 853 L_ATCU_Lib_IntakeRECSw "ATCU Library Intake REC Switch (1button/2button type)";
CM_ SG_ 853 L_ATCU_Lib_IntakeFRESw "ATCU Library Intake FRE Switch (2button type)";
CM_ SG_ 853 L_ATCU_Lib_ACSw "ATCU Library AC Switch";
CM_ SG_ 853 L_ATCU_Lib_DEFSw "ATCU Library DEF Switch";
CM_ SG_ 853 L_ATCU_Lib_DrvTempUpSw "ATCU Library Driverside Temp Up Switch";
CM_ SG_ 853 L_ATCU_Lib_DrvTempDnSw "ATCU Library Driverside Temp Down Switch";
CM_ SG_ 853 L_ATCU_Lib_AstTempUpSw "ATCU Library Assistside Temp Up Switch";
CM_ SG_ 853 L_ATCU_Lib_AstTempDnSw "ATCU Library Assistside Temp Down Switch";
CM_ SG_ 853 L_ATCU_Lib_SyncSw "ATCU Library Sync Switch";
CM_ SG_ 853 L_ATCU_Lib_ModSw "ATCU Library Mode Switch (1button type)";
CM_ SG_ 853 L_ATCU_Lib_DrvOnlySw "ATCU Library DriverOnly Switch";
CM_ SG_ 853 L_ATCU_Lib_ClimateSw "ATCU Library Climate Switch";
CM_ SG_ 853 L_ATCU_Lib_RearDEFSw "ATCU Library RearDEF Switch";
CM_ SG_ 853 L_ATCU_Lib_StrWhlSw "ATCU Library SteeringWheel Heater Switch";
CM_ SG_ 853 L_ATCU_Lib_DrvSeatHeatSw "ATCU Library Driverside Seat Heater Switch";
CM_ SG_ 853 L_ATCU_Lib_DrvSeatVentSw "ATCU Library Driverside Seat Vent Switch";
CM_ SG_ 853 L_ATCU_Lib_AstSeatHeatSw "ATCU Library Assistside Seat Heater Switch";
CM_ SG_ 853 L_ATCU_Lib_AstSeatVentSw "ATCU Library Assistside Seat Vent Switch";
CM_ SG_ 853 L_ATCU_Lib_DrvSeatTumblerSw "ATCU Library Driverside Seat Tumbler Switch";
CM_ SG_ 853 L_ATCU_Lib_ModUpSw "ATCU Library Mode Up Switch (2button type)";
CM_ SG_ 853 L_ATCU_Lib_AstSeatTumblerSw "ATCU Library Assistside Seat Tumbler Switch";
CM_ SG_ 853 L_ATCU_Lib_2ndSyncSetSw "ATCU Library 2nd Sync Set Switch";
CM_ SG_ 853 L_ATCU_Lib_2ndOffSw "ATCU Library 2nd Off Switch";
CM_ SG_ 853 L_ATCU_Lib_2ndLockSetSw "ATCU Library 2nd Lock Set Switch";
CM_ SG_ 853 L_ATCU_Lib_ModDnSw "ATCU Library Mode Down Switch (2button type)";
CM_ SG_ 853 L_ATCU_Lib_BlrUpSw "ATCU Library Blower Up Switch";
CM_ SG_ 853 L_ATCU_Lib_BlrDnSw "ATCU Library Blower Down Switch";
CM_ BO_ 854 "[PE] Periodic and On Event";
CM_ SG_ 854 L_ATCU_Lib_OffSetSw "ATCU Library Off Set Switch";
CM_ SG_ 854 L_ATCU_Lib_BlrSetSw "ATCU Library Blower Set Switch";
CM_ SG_ 854 L_ATCU_Lib_DEFSetSw "ATCU Library DEF Set Switch";
CM_ SG_ 854 L_ATCU_Lib_SyncSetSw "ATCU Library Sync Set Switch";
CM_ SG_ 854 L_ATCU_Lib_AutoSetSw "ATCU Library Auto Set Switch";
CM_ SG_ 854 L_ATCU_Lib_DrvOnlySetSw "ATCU Library DriverOnly Set Switch";
CM_ SG_ 854 L_ATCU_Lib_IntakeSetSw "ATCU Library Intake Set Switch";
CM_ SG_ 854 L_ATCU_Lib_DrvTempSetSw "ATCU Library Driverside Temp Set Switch";
CM_ SG_ 854 L_ATCU_Lib_MultiAutoSetSw "ATCU Library MultiAuto Set Switch";
CM_ SG_ 854 L_ATCU_Lib_AstTempSetSw "ATCU Library Assistside Temp Set Switch";
CM_ SG_ 854 L_ATCU_Lib_DrvTempClickCnt "ATCU Library Driverside Temp Switch";
CM_ SG_ 854 L_ATCU_Lib_AstTempClickCnt "ATCU Library Driverside Temp Switch";
CM_ SG_ 854 L_ATCU_Lib_ACSetSw "ATCU Library AC Set Switch";
CM_ SG_ 854 L_ATCU_Lib_ModSetSw "ATCU Library Mode Set Switch";
CM_ BO_ 855 "[PE] Periodic and On Event";
CM_ SG_ 855 L_ATCU_Lib_2ndAutoSw "ATCU Library 2nd Auto Switch";
CM_ SG_ 855 L_ATCU_Lib_2ndAutoUpSw "ATCU Library 2nd Auto Up Switch";
CM_ SG_ 855 L_ATCU_Lib_2LHTempUpSw "ATCU Library 2nd Leftside Temp Up Switch";
CM_ SG_ 855 L_ATCU_Lib_2LHTempDnSw "ATCU Library 2nd Leftside Temp Down Switch";
CM_ SG_ 855 L_ATCU_Lib_2RHTempUpSw "ATCU Library 2nd Rightside Temp Up Switch";
CM_ SG_ 855 L_ATCU_Lib_2RHTempDnSw "ATCU Library 2nd Rightside Temp Down Switch";
CM_ SG_ 855 L_ATCU_Lib_2ndSyncSw "ATCU Library 2nd Sync Switch";
CM_ SG_ 855 L_ATCU_Lib_2ndLockSw "ATCU Library 2nd Lock Switch";
CM_ SG_ 855 L_ATCU_Lib_2LHSeatHeatSw "ATCU Library 2nd Leftside Seat Heater Switch";
CM_ SG_ 855 L_ATCU_Lib_2LHSeatVentSw "ATCU Library 2nd Leftside Seat Vent Switch";
CM_ SG_ 855 L_ATCU_Lib_2RHSeatHeatSw "ATCU Library 2nd Rightside Seat Heater Switch";
CM_ SG_ 855 L_ATCU_Lib_2RHSeatVentSw "ATCU Library 2nd Rightside Seat Vent Switch";
CM_ SG_ 855 L_ATCU_Lib_2ndAutoDnSw "ATCU Library 2nd Auto Down Switch";
CM_ SG_ 855 L_ATCU_Lib_2LHSeatTumblerSw "ATCU Library 2nd Leftside Seat Tumbler Switch";
CM_ SG_ 855 L_ATCU_Lib_2RHSeatTumblerSw "ATCU Library 2nd Rightside Seat Tumbler Switch";
CM_ SG_ 855 L_ATCU_Lib_2ndOffSetSw "ATCU Library 2nd Off Set Switch";
CM_ SG_ 855 L_ATCU_Lib_2ndAutoSetSw "ATCU Library 2nd Auto Set Switch";
CM_ SG_ 855 L_ATCU_Lib_2ndMultiAutoSetSw "ATCU Library 2nd MultiAuto Set Switch";
CM_ SG_ 855 L_ATCU_Lib_2LHModSw "ATCU Library 2nd Mode Switch";
CM_ SG_ 855 L_ATCU_Lib_2ndACSetSw "ATCU Library 2nd AC Set Switch";
CM_ SG_ 855 L_ATCU_Lib_2LHModSetSw "ATCU Library 2nd Mode Set Switch";
CM_ SG_ 855 L_ATCU_Lib_2LHBlrSetSw "ATCU Library 2nd Blower Set Switch";
CM_ SG_ 855 L_ATCU_Lib_2LHModUpSw "ATCU Library 2nd Mode Up Switch";
CM_ SG_ 855 L_ATCU_Lib_2LHTempSetSw "ATCU Library 2nd Leftside Temp Set Switch";
CM_ SG_ 855 L_ATCU_Lib_2RHTempSetSw "ATCU Library 2nd Rightside Temp Set Switch";
CM_ SG_ 855 L_ATCU_Lib_2LHModDnSw "ATCU Library 2nd Mode Down Switch";
CM_ SG_ 855 L_ATCU_Lib_DrvBlrClickCnt "ATCU Library Driverside Blower Knob Click Count";
CM_ SG_ 855 L_ATCU_Lib_2LHBlrUpSw "ATCU Library 2nd Blower Up Switch";
CM_ SG_ 855 L_ATCU_Lib_2LHBlrDnSw "ATCU Library 2nd Blower Down Switch";
CM_ SG_ 855 L_ATCU_Lib_2LHBlrDnOffReq "ATCU Library 2nd Blower DownOff Switch";
CM_ SG_ 855 L_ATCU_Lib_2ndACSw "ATCU Library 2nd AC Switch";
CM_ BO_ 856 "[PE] Periodic and On Event";
CM_ SG_ 856 L_ATCU_Lib_AutoStepInd "ATCU Library Auto Step Indicator";
CM_ SG_ 856 L_ATCU_Lib_BlrSym "ATCU Library Blower Symbol";
CM_ SG_ 856 L_ATCU_Lib_BlrStepSym "ATCU Library Blower Step Symbol";
CM_ SG_ 856 L_ATCU_Lib_IntakeRECInd "ATCU Library Intake REC Indicator";
CM_ SG_ 856 L_ATCU_Lib_IntakeFREInd "ATCU Library Intake FRE Indicator";
CM_ SG_ 856 L_ATCU_Lib_ACInd "ATCU Library AC Indicator";
CM_ SG_ 856 L_ATCU_Lib_DEFInd "ATCU Library DEF Indicator";
CM_ SG_ 856 L_ATCU_Lib_SyncInd "ATCU Library Sync Indicator";
CM_ SG_ 856 L_ATCU_Lib_AutoBlrStepSym "ATCU Library Auto Blower Step Text Symbol";
CM_ SG_ 856 L_ATCU_Lib_DrvOnly "ATCU Library DriverOnly Indicator";
CM_ SG_ 856 L_ATCU_Lib_ADSSym "ATCU Library ADS Symbol";
CM_ SG_ 856 L_ATCU_Lib_ModVentInd "ATCU Library Mode Vent Indicator";
CM_ SG_ 856 L_ATCU_Lib_DrvTempSym "ATCU Library Driverside Temp Symbol";
CM_ SG_ 856 L_ATCU_Lib_ModSym "ATCU Library Mode Symbol";
CM_ SG_ 856 L_ATCU_Lib_AstTempSym "ATCU Library Assistside Temp Symbol";
CM_ SG_ 856 L_ATCU_Lib_DrvTempUnitSym "ATCU Library TempUnit Symbol";
CM_ SG_ 856 L_ATCU_Lib_ModFloorInd "ATCU Library Mode Floor Indicator";
CM_ SG_ 856 L_ATCU_Lib_ModDEFInd "ATCU Library Mode DEF Indicator";
CM_ BO_ 857 "[PE] Periodic and On Event";
CM_ SG_ 857 L_ATCU_Lib_2LHAutoStepInd "ATCU Library 2nd Auto Step Indicator";
CM_ SG_ 857 L_ATCU_Lib_2ndACInd "ATCU Library 2nd AC Indicator";
CM_ SG_ 857 L_ATCU_Lib_2ndSyncInd "ATCU Library 2nd Sync Indicator";
CM_ SG_ 857 L_ATCU_Lib_2ndLockInd "ATCU Library 2nd Lock Indicator";
CM_ SG_ 857 L_ATCU_Lib_2LHBlrSym "ATCU Library 2nd Blower Symbol";
CM_ SG_ 857 L_ATCU_Lib_2LHTempSym "ATCU Library 2nd Leftside Temp Symbol";
CM_ SG_ 857 L_ATCU_Lib_2LHAutoBlrStepSym "ATCU Library 2nd Auto Blower Step Text Symbol";
CM_ SG_ 857 L_ATCU_Lib_2LHTempUnit "ATCU Library 2nd TempUnit Symbol";
CM_ SG_ 857 L_ATCU_Lib_2LHModSym "ATCU Library 2nd Mode Symbol";
CM_ SG_ 857 L_ATCU_Lib_FineDustTreeSym "ATCU Library FineDust Tree Symbol";
CM_ SG_ 857 L_ATCU_Lib_FineDustTreeColor "ATCU Library FineDust Tree Color";
CM_ SG_ 857 L_ATCU_Lib_FineDustBarStepSym "ATCU Library FineDust Bar Step";
CM_ SG_ 857 L_ATCU_Lib_2RHTempSym "ATCU 2nd Rightside Temp Symbol";
CM_ SG_ 857 L_ATCU_Lib_2LHBlrStepSym "ATCU Library 2nd Blower Step Symbol";
CM_ BO_ 858 "[PE] Periodic and On Event";
CM_ SG_ 858 L_ATCU_Lib_USMDEFState "ATCU Library DEF USM";
CM_ SG_ 858 L_ATCU_Lib_USMSmrtVentState "ATCU Library SmartVent USM";
CM_ SG_ 858 L_ATCU_Lib_USMCoolHeatSeat "ATCU Library CoolHeatSeat USM";
CM_ SG_ 858 L_ATCU_Lib_USMStrWhlHeater "ATCU Library SteeringWheel Heater USM";
CM_ SG_ 858 L_ATCU_Lib_USMUsrPrfleState "ATCU Library UserProfile USM";
CM_ SG_ 858 L_ATCU_Lib_USMAutoFreshState "ATCU Library AutoFresh USM";
CM_ SG_ 858 L_ATCU_Lib_USM2ndAutoOffState "ATCU Library 2nd AutoOff USM";
CM_ SG_ 858 L_ATCU_Lib_USMRearLock "ATCU Library RearLock USM";
CM_ SG_ 858 L_ATCU_Lib_USMWshState "ATCU Library Washer USM";
CM_ SG_ 858 L_ATCU_Lib_USMADSState "ATCU Library ADS USM";
CM_ SG_ 858 L_ATCU_Lib_USMTempUnitState "ATCU Library TempUnit USM";
CM_ SG_ 858 L_ATCU_Lib_USMAfterBlowState "ATCU Library AfterBlow USM";
CM_ SG_ 858 L_ATCU_Lib_USMSchdldVent "ATCU Library SchdldVent USM";
CM_ BO_ 859 "[PE] Periodic and On Event";
CM_ SG_ 859 L_ATCU_Lib_Opt2LHModSwTyp "ATCU Library 2nd Leftside Mode Switch Type(1/2/3 button)";
CM_ SG_ 859 L_ATCU_Lib_Opt2ndModBtn "ATCU Library 2nd Mode Type (Single/Dual)";
CM_ SG_ 859 L_ATCU_Lib_Opt2ndOffSwTyp "ATCU Library 2nd Off Switch Type(Off/DownOff)";
CM_ SG_ 859 L_ATCU_Lib_Opt2ndTmpBtn "ATCU Library 2nd Temp Type (Single/Dual)";
CM_ SG_ 859 L_ATCU_Lib_OptADS "ATCU Library ADS Option";
CM_ SG_ 859 L_ATCU_Lib_OptAfterBlow "ATCU Library AfterBlow Option";
CM_ SG_ 859 L_ATCU_Lib_OptAutoStep "ATCU Library Auto Step Option";
CM_ SG_ 859 L_ATCU_Lib_Opt2ndAutoBtn "ATCU Library 2nd Auto Type (Single/Dual)";
CM_ SG_ 859 L_ATCU_Lib_OptAutoSwTyp "ATCU Library Auto Switch Type(1/2 button)";
CM_ SG_ 859 L_ATCU_Lib_OptBATCoolingTyp "ATCU Library Battery Cooling Type";
CM_ SG_ 859 L_ATCU_Lib_OptBlrSwKnob "ATCU Library Blower Knob Option";
CM_ SG_ 859 L_ATCU_Lib_OptComp "ATCU Library Compressor Type";
CM_ SG_ 859 L_ATCU_Lib_OptDrvHndSide "ATCU Library Driver Handel Side Type";
CM_ SG_ 859 L_ATCU_Lib_OptDrvOnly "ATCU Library DriverOnly Option";
CM_ SG_ 859 L_ATCU_Lib_OptFineDust "ATCU Library FineDust Option";
CM_ SG_ 859 L_ATCU_Lib_OptCoolHeatSeat "ATCU Library CoolHeatSeat Option";
CM_ SG_ 859 L_ATCU_Lib_OptPTCTyp "ATCU Library PTC Type";
CM_ SG_ 859 L_ATCU_Lib_OptLCDDisp "ATCU Library LCD Display Type";
CM_ SG_ 859 L_ATCU_Lib_OptModSwTyp "ATCU Library Mode Switch Type(1/2/3 button) Option";
CM_ SG_ 859 L_ATCU_Lib_OptOffSwTyp "ATCU Library Off Switch Type(Off/DownOff) Option";
CM_ SG_ 859 L_ATCU_Lib_Opt2ndAutoStep "ATCU Library 2nd Auto Step Option";
CM_ SG_ 859 L_ATCU_Lib_OptNetworkTyp "ATCU Library Network Type";
CM_ SG_ 859 L_ATCU_Lib_OptPTCStep "ATCU Library PTC Step Option";
CM_ SG_ 859 L_ATCU_Lib_OptPTG "ATCU Library PTG Option";
CM_ SG_ 859 L_ATCU_Lib_OptROATyp "ATCU Library ROA Option";
CM_ SG_ 859 L_ATCU_Lib_OptVRLED "ATCU Library VRLED Option";
CM_ SG_ 859 L_ATCU_Lib_OptRgn "ATCU Library Region Type";
CM_ SG_ 859 L_ATCU_Lib_OptSchdldVent "ATCU Library Schduled Ventilation Option";
CM_ SG_ 859 L_ATCU_Lib_OptIntakeSwTyp "ATCU Library Intake Switch Type(1/2 button) Option";
CM_ SG_ 859 L_ATCU_Lib_OptStrHeat "ATCU Library SteeringWheel Heater Option";
CM_ SG_ 859 L_ATCU_Lib_OptSync "ATCU Library Sync Option";
CM_ SG_ 859 L_ATCU_Lib_OptTempSwKnob "ATCU Library Temp Knob Option";
CM_ SG_ 859 L_ATCU_Lib_OptThermostat "ATCU Library Thermostat Option";
CM_ SG_ 859 L_ATCU_Lib_OptVehTyp "ATCU Library Vehicle Type (ICE/HEV/EV)";
CM_ SG_ 859 L_ATCU_Lib_Opt2ndAutoSwTyp "ATCU Library 2nd Auto Switch Type(1/2 button)";
CM_ SG_ 859 L_ATCU_Lib_OptWheelDrivePos "ATCU Library Drive Wheel Position Type";
CM_ SG_ 859 L_ATCU_Lib_Opt2ndTempSwKnob "ATCU Library 2nd Temp Knob Option";
CM_ SG_ 859 L_ATCU_Lib_Opt2ndBlrBtn "ATCU Library 2nd Blower Type (Single/Dual)";
CM_ BO_ 861 "[PE] Periodic and On Event";
CM_ SG_ 861 L_ATCU_Lib_MngrModBufOp "ATCU Library Mode Manager Buffer Operating Function";
CM_ SG_ 861 L_ATCU_Lib_MngrDEFBufOp "ATCU Library DEF Manager Buffer Operating Function";
CM_ SG_ 861 L_ATCU_Lib_MngrBlwBufOp "ATCU Library Blower Manager Buffer Operating Function";
CM_ SG_ 861 L_ATCU_Lib_MngrACBufOp "ATCU Library AC Manager Buffer Operating Function";
CM_ SG_ 861 L_ATCU_Lib_2LHMngrBlwBufOp "ATCU Library 2nd Leftside Blower Manager Buffer Operating Function";
CM_ SG_ 861 L_ATCU_Lib_2LHMngrModBufOp "ATCU Library 2nd Leftside Mode Manager Buffer Operating Function";
CM_ SG_ 861 L_ATCU_Lib_2LHMngrTempBufOp "ATCU Library 2nd Leftside Temp Manager Buffer Operating Function";
CM_ SG_ 861 L_ATCU_Lib_2RHMngrTempBufOp "ATCU Library 2nd Rightside Temp Manager Buffer Operating Function";
CM_ SG_ 861 L_ATCU_Lib_MngrActvIncarMotPwr "ATCU Library Other Manager Active Type Incar Sensor Motor On Req";
CM_ SG_ 861 L_ATCU_Lib_MngrPDCWakeUpReq "ATCU Library Other Manager PDC Wake Up (Active Low) Req";
CM_ SG_ 861 L_ATCU_Lib_MngrLVPTCRly1Sta "ATCU Library Other Manager Low Voltage PTC Rly1 On Req";
CM_ SG_ 861 L_ATCU_Lib_MngrLVPTCRly2Sta "ATCU Library Other Manager Low Voltage PTC Rly2 On Req";
CM_ SG_ 861 L_ATCU_Lib_MngrLVPTCRly3Sta "ATCU Library Other Manager Low Voltage PTC Rly3 On Req";
CM_ SG_ 861 L_ATCU_Lib_MngrTempBufOp "ATCU Library Temp Manager Buffer Operating Function";
CM_ SG_ 861 L_ATCU_Lib_MngrIntakeBufOp "ATCU Library Intake Manager Buffer Operating Function";
CM_ BO_ 862 "[PE] Periodic and On Event";
CM_ SG_ 862 L_ATCU_Lib_MngrModBuf0 "ATCU Library Mode Manager Buffer 0";
CM_ SG_ 862 L_ATCU_Lib_MngrModBufLow1 "ATCU Library Mode Manager Lower Limit Buffer 1";
CM_ SG_ 862 L_ATCU_Lib_MngrModBuf2 "ATCU Library Mode Manager Buffer 2";
CM_ SG_ 862 L_ATCU_Lib_MngrModBufHi0 "ATCU Library Mode Manager Upper Limit Buffer 0";
CM_ SG_ 862 L_ATCU_Lib_MngrModBuf3 "ATCU Library Mode Manager Buffer 3";
CM_ SG_ 862 L_ATCU_Lib_MngrModBufHi1 "ATCU Library Mode Manager Upper Limit Buffer 1";
CM_ SG_ 862 L_ATCU_Lib_MngrModBuf4 "ATCU Library Mode Manager Buffer 4";
CM_ SG_ 862 L_ATCU_Lib_MngrModBuf5 "ATCU Library Mode Manager Buffer 5";
CM_ SG_ 862 L_ATCU_Lib_MngrModBuf6 "ATCU Library Mode Manager Buffer 6";
CM_ SG_ 862 L_ATCU_Lib_MngrModBufLow0 "ATCU Library Mode Manager Lower Limit Buffer 0";
CM_ SG_ 862 L_ATCU_Lib_MngrModBuf7 "ATCU Library Mode Manager Buffer 7";
CM_ SG_ 862 L_ATCU_Lib_MngrModBuf1 "ATCU Library Mode Manager Buffer 1";
CM_ BO_ 863 "[PE] Periodic and On Event";
CM_ SG_ 863 L_ATCU_Lib_MngrBlwBuf0 "ATCU Library Blower Manager Buffer 0";
CM_ SG_ 863 L_ATCU_Lib_MngrBlwBuf3 "ATCU Library Blower Manager Buffer 3";
CM_ SG_ 863 L_ATCU_Lib_MngrBlwBuf4 "ATCU Library Blower Manager Buffer 4";
CM_ SG_ 863 L_ATCU_Lib_MngrBlwBuf5 "ATCU Library Blower Manager Buffer 5";
CM_ SG_ 863 L_ATCU_Lib_MngrBlwBuf6 "ATCU Library Blower Manager Buffer 6";
CM_ SG_ 863 L_ATCU_Lib_MngrBlwBuf7 "ATCU Library Blower Manager Buffer 7";
CM_ SG_ 863 L_ATCU_Lib_MngrBlwBufHi0 "ATCU Library Blower Manager Upper Limit Buffer 0";
CM_ SG_ 863 L_ATCU_Lib_MngrBlwBufLow0 "ATCU Library Blower Manager Lower Limit Buffer 0";
CM_ SG_ 863 L_ATCU_Lib_MngrBlwBufLow1 "ATCU Library Blower Manager Lower Limit Buffer 1";
CM_ SG_ 863 L_ATCU_Lib_MngrBlwBuf1 "ATCU Library Blower Manager Buffer 1";
CM_ SG_ 863 L_ATCU_Lib_MngrBlwBufHi1 "ATCU Library Blower Manager Upper Limit Buffer 1";
CM_ SG_ 863 L_ATCU_Lib_MngrBlwBufLow2 "ATCU Library Blower Manager Lower Limit Buffer 2";
CM_ SG_ 863 L_ATCU_Lib_MngrBlwBufLow3 "ATCU Library Blower Manager Lower Limit Buffer 3";
CM_ SG_ 863 L_ATCU_Lib_MngrBlwBufHi2 "ATCU Library Blower Manager Upper Limit Buffer 2";
CM_ SG_ 863 L_ATCU_Lib_MngrBlwBuf2 "ATCU Library Blower Manager Buffer 2";
BA_DEF_ BO_ "UsrMsgIDSforwardDeviation" INT 0 100 ;
BA_DEF_ BO_ "UsrMsgIDSbackwardDeviation" INT 50 1000 ;
BA_DEF_ BO_ "GenMsgCycleTime" INT 0 2000 ;
BA_DEF_ BO_ "GenMsgStartDelayTime" INT 0 2000 ;
BA_DEF_ BO_ "GenMsgSendType" ENUM "Cyclic","NoMsgSendType" ;
BA_DEF_ BO_ "GenMsgCycleTimeFast" INT 0 500 ;
BA_DEF_ BO_ "GenMsgDelayTime" INT 0 20 ;
BA_DEF_ BO_ "GenMsgILSupport" ENUM "No","Yes" ;
BA_DEF_ BO_ "GenMsgNrOfRepetition" INT 0 3 ;
BA_DEF_ BO_ "VFrameFormat" ENUM "StandardCAN","ExtendedCAN","reserved","reserved","reserved","reserved","reserved","reserved","reserved","reserved","reserved","reserved","reserved","reserved","StandardCAN_FD","ExtendedCAN_FD" ;
BA_DEF_ SG_ "UserSigValidity" ENUM "B+","ACC","IG","IG1","IG2","IG3","IG1 or IG2","IG1 or IG3","Undef" ;
BA_DEF_ SG_ "UsrSigPurpose" ENUM "Undef","FN","DIAG","DIAG(Req)","DIAG(Res)","DIAG(Phy)","DEV","CCP(Req)","CCP(Res)","NM","TP" ;
BA_DEF_ SG_ "GenSigStartValue" INT 0 1215752192 ;
BA_DEF_ SG_ "NetworkRequestHoldingTime" INT 0 65535 ;
BA_DEF_ SG_ "Description" STRING ;
BA_DEF_ SG_ "Version" STRING ;
BA_DEF_ SG_ "GenSigEnvVarType" ENUM "Int","Float","Undef" ;
BA_DEF_ SG_ "GenSigSendType" ENUM "Cyclic","OnWrite","OnWriteWithRepetition","OnChange","OnChangeWithRepetition","IfActive","IfActiveWithRepetition","NoSigSendType","OnChangeAndIfActive","OnChangeAndIfActiveWithRepetition" ;
BA_DEF_ SG_ "GwSigLatencyTime" INT 0 65536 ;
BA_DEF_ SG_ "GwSigMissingSourceType" ENUM "Undef","OldValue","DefaultValue","InitialValue" ;
BA_DEF_ SG_ "NWM-WakeupAllowed" ENUM "<n.a.>" ;
BA_DEF_ SG_ "RoutingFactor" INT 1 1215752192 ;
BA_DEF_REL_ BU_SG_REL_ "GenSigTimeoutTime" INT 0 7000 ;
BA_DEF_DEF_ "UsrMsgIDSforwardDeviation" 10 ;
BA_DEF_DEF_ "UsrMsgIDSbackwardDeviation" 100 ;
BA_DEF_DEF_ "GenMsgCycleTime" 200 ;
BA_DEF_DEF_ "GenMsgStartDelayTime" 0 ;
BA_DEF_DEF_ "GenMsgSendType" "NoMsgSendType" ;
BA_DEF_DEF_ "GenMsgCycleTimeFast" 40 ;
BA_DEF_DEF_ "GenMsgDelayTime" 20 ;
BA_DEF_DEF_ "GenMsgILSupport" "Yes" ;
BA_DEF_DEF_ "GenMsgNrOfRepetition" 3 ;
BA_DEF_DEF_ "VFrameFormat" "StandardCAN" ;
BA_DEF_DEF_ "UserSigValidity" "IG" ;
BA_DEF_DEF_ "UsrSigPurpose" "FN" ;
BA_DEF_DEF_ "GenSigStartValue" 0 ;
BA_DEF_DEF_ "NetworkRequestHoldingTime" 0 ;
BA_DEF_DEF_ "Description" "" ;
BA_DEF_DEF_ "Version" "" ;
BA_DEF_DEF_ "GenSigEnvVarType" "Undef" ;
BA_DEF_DEF_ "GenSigSendType" "NoSigSendType" ;
BA_DEF_DEF_ "GwSigLatencyTime" 40 ;
BA_DEF_DEF_ "GwSigMissingSourceType" "Undef" ;
BA_DEF_DEF_ "NWM-WakeupAllowed" "<n.a.>" ;
BA_DEF_DEF_ "RoutingFactor" 1 ;
BA_DEF_DEF_REL_ "GenSigTimeoutTime" 500 ;
BA_ "GenMsgSendType" BO_ 97 0;
BA_ "GenMsgCycleTime" BO_ 97 500;
BA_ "Description" SG_ 97 L_2HKBD_Sw_Opt1 "Bit0~2:RESERVED

Bit3~4:(Type):0 - None/1 - ATC/2 - MTC 

Bit5~7:RESERVED";
BA_ "GenSigSendType" SG_ 97 L_2HKBD_Sw_Opt1 4;
BA_ "UserSigValidity" SG_ 97 L_2HKBD_Sw_Opt1 7;
BA_REL_ "GenSigTimeoutTime" BU_SG_REL_ L_ATCU SG_ 97 L_2HKBD_Sw_Opt1 5000;
BA_ "Version" SG_ 97 L_2HKBD_Sw_Opt1 "23.11.09";
BA_ "Description" SG_ 97 L_2HKBD_Typ2 "Bit 0 : 2nd ROOF DR DUCT Snsr : 0 ? Not Apply / 1 ? Apply

Bit 1 : 2nd ROOF Ast DUCT Snsr : 0 ? Not Apply / 1 ? Apply

Bit 2 : 2nd FLOOR DR DUCT Snsr : 0 ? Not Apply / 1 ? Apply

Bit 3 : 2nd FLOOR Ast DUCT Snsr : 0 ? Not Apply / 1 - Apply

Bit 4 : RESERVED

Bit 5~6 (2nd Multi Auto Text):0 - Multi Auto State Text Not Applied/1 - Multi Auto State Text Display Only Applied/2 - Multi Auto State Text Display & Control Applied/3 ? RESERVED

Bit7:(2nd REAR LOCK):0 ? NON REAR LOCK/1 ? REAR LOCK";
BA_ "GenSigSendType" SG_ 97 L_2HKBD_Typ2 4;
BA_ "UserSigValidity" SG_ 97 L_2HKBD_Typ2 7;
BA_REL_ "GenSigTimeoutTime" BU_SG_REL_ L_ATCU SG_ 97 L_2HKBD_Typ2 5000;
BA_ "Version" SG_ 97 L_2HKBD_Typ2 "24.11.00";
BA_ "Description" SG_ 97 L_2HKBD_Typ3 "Bit 0~1 (2nd Rear Ps Auto Step):0 ? None/1 ? Single(On/Off)/2 ? 2 Step Type (High/Low/Off)/3 ? 3 Step Type(High/Medium/Low/Off)

Bit 2~3 RESERVED

Bit 4~5 (2nd Rear Ps Multi Auto Text):0 - Multi Auto State Text Not Applied/1 - Multi Auto State Text Display Only Applied/2 - Multi Auto State Text Display & Control Applied/3 ? RESERVED";
BA_ "GenSigSendType" SG_ 97 L_2HKBD_Typ3 4;
BA_ "UserSigValidity" SG_ 97 L_2HKBD_Typ3 7;
BA_REL_ "GenSigTimeoutTime" BU_SG_REL_ L_ATCU SG_ 97 L_2HKBD_Typ3 5000;
BA_ "Version" SG_ 97 L_2HKBD_Typ3 "24.02.01";
BA_ "GenSigSendType" SG_ 97 L_2HKBD_SW_Ver1 4;
BA_ "UserSigValidity" SG_ 97 L_2HKBD_SW_Ver1 7;
BA_REL_ "GenSigTimeoutTime" BU_SG_REL_ L_ATCU_vMON SG_ 97 L_2HKBD_SW_Ver1 5000;
BA_ "Version" SG_ 97 L_2HKBD_SW_Ver1 "25.05.04";
BA_ "GenSigSendType" SG_ 97 L_2HKBD_SW_Ver2 4;
BA_ "UserSigValidity" SG_ 97 L_2HKBD_SW_Ver2 7;
BA_REL_ "GenSigTimeoutTime" BU_SG_REL_ L_ATCU_vMON SG_ 97 L_2HKBD_SW_Ver2 5000;
BA_ "Version" SG_ 97 L_2HKBD_SW_Ver2 "25.05.04";
BA_ "GenSigSendType" SG_ 97 L_2HKBD_SW_Ver3 4;
BA_ "UserSigValidity" SG_ 97 L_2HKBD_SW_Ver3 7;
BA_REL_ "GenSigTimeoutTime" BU_SG_REL_ L_ATCU_vMON SG_ 97 L_2HKBD_SW_Ver3 5000;
BA_ "Version" SG_ 97 L_2HKBD_SW_Ver3 "25.05.04";
BA_ "Description" SG_ 97 L_2HKBD_Typ1 "Bit 0~7 : RESERVED";
BA_ "GenSigSendType" SG_ 97 L_2HKBD_Typ1 4;
BA_ "UserSigValidity" SG_ 97 L_2HKBD_Typ1 7;
BA_REL_ "GenSigTimeoutTime" BU_SG_REL_ L_ATCU SG_ 97 L_2HKBD_Typ1 5000;
BA_ "Version" SG_ 97 L_2HKBD_Typ1 "24.02.01";
BA_ "GenMsgSendType" BO_ 98 0;
BA_ "GenMsgCycleTime" BO_ 98 20;
BA_ "GenMsgCycleTimeFast" BO_ 98 0;
BA_ "GenMsgNrOfRepetition" BO_ 98 0;
BA_ "GenMsgDelayTime" BO_ 98 0;
BA_ "UserSigValidity" SG_ 98 L_2HKBD_Rr_EvapVolVal 7;
BA_ "Version" SG_ 98 L_2HKBD_Rr_EvapVolVal "23.09.05";
BA_ "UserSigValidity" SG_ 98 L_2HKBD_Rr_TempActrSt 7;
BA_ "Version" SG_ 98 L_2HKBD_Rr_TempActrSt "23.09.01";
BA_ "UserSigValidity" SG_ 98 L_2HKBD_Rr_TempAsstActrFB 7;
BA_ "Version" SG_ 98 L_2HKBD_Rr_TempAsstActrFB "23.09.01";
BA_ "UserSigValidity" SG_ 98 L_2HKBD_Rr_TempAsstActrSt 7;
BA_ "Version" SG_ 98 L_2HKBD_Rr_TempAsstActrSt "23.09.01";
BA_ "UserSigValidity" SG_ 98 L_2HKBD_Rr_ModeActrFB 7;
BA_ "Version" SG_ 98 L_2HKBD_Rr_ModeActrFB "23.09.01";
BA_ "UserSigValidity" SG_ 98 L_2HKBD_Rr_ModeActrSt 7;
BA_ "Version" SG_ 98 L_2HKBD_Rr_ModeActrSt "23.09.01";
BA_ "UserSigValidity" SG_ 98 L_2HKBD_Rr_BLDCError 7;
BA_ "Version" SG_ 98 L_2HKBD_Rr_BLDCError "23.09.01";
BA_ "Description" SG_ 98 L_2HKBD_Rr_HVACBLDCRpmFB "00H~3E8H:RPM = Factor * Hex + Offset/3E9H ~ FFFFH:RESERVED";
BA_ "UserSigValidity" SG_ 98 L_2HKBD_Rr_HVACBLDCRpmFB 7;
BA_ "Version" SG_ 98 L_2HKBD_Rr_HVACBLDCRpmFB "23.09.05";
BA_ "UserSigValidity" SG_ 98 L_2HKBD_Rr_TempActrFB 7;
BA_ "Version" SG_ 98 L_2HKBD_Rr_TempActrFB "23.09.01";
BA_ "GenMsgSendType" BO_ 99 0;
BA_ "GenMsgCycleTime" BO_ 99 500;
BA_ "Description" SG_ 99 L_2HKBD_SwBtnTyp "Each bit for button type is defined as

0-None/1-Hardkey/2-Touch(Used Beep)/3-Touch(Not Used Beep)

Bit 0~1 : 2nd Temp Button / Bit 2~3 : 2nd Blower Button / Bit 4~5 : 2nd Mode Button / Bit 6~7 : 2nd Auto Button / Bit 8~9 : 2nd A/C Button / Bit 10~11 : 2nd Sync Button / Bit 12~13 : 2nd StHeatVnt Button / Bit 14~15 : OFF / 16~19 : Reserved";
BA_ "GenSigSendType" SG_ 99 L_2HKBD_SwBtnTyp 4;
BA_ "UserSigValidity" SG_ 99 L_2HKBD_SwBtnTyp 7;
BA_REL_ "GenSigTimeoutTime" BU_SG_REL_ L_ATCU SG_ 99 L_2HKBD_SwBtnTyp 5000;
BA_ "Version" SG_ 99 L_2HKBD_SwBtnTyp "23.11.09";
BA_ "Description" SG_ 99 L_2HKBD_ResetOpSta "This signal indicates whether the reset operation has been completed or not";
BA_ "GenSigSendType" SG_ 99 L_2HKBD_ResetOpSta 4;
BA_ "UserSigValidity" SG_ 99 L_2HKBD_ResetOpSta 0;
BA_REL_ "GenSigTimeoutTime" BU_SG_REL_ L_ATCU SG_ 99 L_2HKBD_ResetOpSta 1000;
BA_ "Version" SG_ 99 L_2HKBD_ResetOpSta "24.10.05";
BA_ "GenMsgSendType" BO_ 100 0;
BA_ "GenSigSendType" SG_ 100 L_2HKBD_RrDrModeDnSw 4;
BA_ "UserSigValidity" SG_ 100 L_2HKBD_RrDrModeDnSw 7;
BA_REL_ "GenSigTimeoutTime" BU_SG_REL_ L_ATCU SG_ 100 L_2HKBD_RrDrModeDnSw 1500;
BA_ "Version" SG_ 100 L_2HKBD_RrDrModeDnSw "23.09.01";
BA_ "GenSigSendType" SG_ 100 L_2HKBD_RrDrModeUpSw 4;
BA_ "UserSigValidity" SG_ 100 L_2HKBD_RrDrModeUpSw 7;
BA_REL_ "GenSigTimeoutTime" BU_SG_REL_ L_ATCU SG_ 100 L_2HKBD_RrDrModeUpSw 1500;
BA_ "Version" SG_ 100 L_2HKBD_RrDrModeUpSw "23.09.01";
BA_ "GenSigSendType" SG_ 100 L_2HKBD_RrDrAutoSw 4;
BA_ "UserSigValidity" SG_ 100 L_2HKBD_RrDrAutoSw 7;
BA_REL_ "GenSigTimeoutTime" BU_SG_REL_ L_ATCU SG_ 100 L_2HKBD_RrDrAutoSw 1500;
BA_ "Version" SG_ 100 L_2HKBD_RrDrAutoSw "23.09.01";
BA_ "GenSigSendType" SG_ 100 L_2HKBD_Rr_OffSw 4;
BA_ "UserSigValidity" SG_ 100 L_2HKBD_Rr_OffSw 7;
BA_REL_ "GenSigTimeoutTime" BU_SG_REL_ L_ATCU SG_ 100 L_2HKBD_Rr_OffSw 1500;
BA_ "Version" SG_ 100 L_2HKBD_Rr_OffSw "23.09.01";
BA_ "GenSigSendType" SG_ 100 L_2HKBD_RrSyncSw 4;
BA_ "UserSigValidity" SG_ 100 L_2HKBD_RrSyncSw 7;
BA_REL_ "GenSigTimeoutTime" BU_SG_REL_ L_ATCU SG_ 100 L_2HKBD_RrSyncSw 1500;
BA_ "Version" SG_ 100 L_2HKBD_RrSyncSw "23.09.01";
BA_ "GenSigSendType" SG_ 100 L_2HKBD_RrAcSw 4;
BA_ "UserSigValidity" SG_ 100 L_2HKBD_RrAcSw 7;
BA_REL_ "GenSigTimeoutTime" BU_SG_REL_ L_ATCU SG_ 100 L_2HKBD_RrAcSw 1500;
BA_ "Version" SG_ 100 L_2HKBD_RrAcSw "23.09.01";
BA_ "GenSigSendType" SG_ 100 L_2HKBD_RLStHtrSwReq 4;
BA_ "UserSigValidity" SG_ 100 L_2HKBD_RLStHtrSwReq 7;
BA_REL_ "GenSigTimeoutTime" BU_SG_REL_ L_ATCU SG_ 100 L_2HKBD_RLStHtrSwReq 1500;
BA_ "Version" SG_ 100 L_2HKBD_RLStHtrSwReq "23.09.01";
BA_ "GenSigSendType" SG_ 100 L_2HKBD_RLStVentSwReq 4;
BA_ "UserSigValidity" SG_ 100 L_2HKBD_RLStVentSwReq 7;
BA_REL_ "GenSigTimeoutTime" BU_SG_REL_ L_ATCU SG_ 100 L_2HKBD_RLStVentSwReq 1500;
BA_ "Version" SG_ 100 L_2HKBD_RLStVentSwReq "23.09.01";
BA_ "GenSigSendType" SG_ 100 L_2HKBD_RRStHtrSwReq 4;
BA_ "UserSigValidity" SG_ 100 L_2HKBD_RRStHtrSwReq 7;
BA_REL_ "GenSigTimeoutTime" BU_SG_REL_ L_ATCU SG_ 100 L_2HKBD_RRStHtrSwReq 1500;
BA_ "Version" SG_ 100 L_2HKBD_RRStHtrSwReq "23.09.01";
BA_ "GenSigSendType" SG_ 100 L_2HKBD_RRStVentSwReq 4;
BA_ "UserSigValidity" SG_ 100 L_2HKBD_RRStVentSwReq 7;
BA_REL_ "GenSigTimeoutTime" BU_SG_REL_ L_ATCU SG_ 100 L_2HKBD_RRStVentSwReq 1500;
BA_ "Version" SG_ 100 L_2HKBD_RRStVentSwReq "23.09.01";
BA_ "GenSigSendType" SG_ 100 L_2HKBD_RrDrMultiAutoSw 4;
BA_ "GenSigStartValue" SG_ 100 L_2HKBD_RrDrMultiAutoSw 7;
BA_ "UserSigValidity" SG_ 100 L_2HKBD_RrDrMultiAutoSw 7;
BA_REL_ "GenSigTimeoutTime" BU_SG_REL_ L_ATCU SG_ 100 L_2HKBD_RrDrMultiAutoSw 1500;
BA_ "Version" SG_ 100 L_2HKBD_RrDrMultiAutoSw "24.01.00";
BA_ "GenSigSendType" SG_ 100 L_2HKBD_RrDrModeSw 4;
BA_ "UserSigValidity" SG_ 100 L_2HKBD_RrDrModeSw 7;
BA_REL_ "GenSigTimeoutTime" BU_SG_REL_ L_ATCU SG_ 100 L_2HKBD_RrDrModeSw 1500;
BA_ "Version" SG_ 100 L_2HKBD_RrDrModeSw "23.09.01";
BA_ "GenSigSendType" SG_ 100 L_2HKBD_RrPsModeSw 4;
BA_ "UserSigValidity" SG_ 100 L_2HKBD_RrPsModeSw 7;
BA_REL_ "GenSigTimeoutTime" BU_SG_REL_ L_ATCU SG_ 100 L_2HKBD_RrPsModeSw 1500;
BA_ "Version" SG_ 100 L_2HKBD_RrPsModeSw "23.09.01";
BA_ "GenSigSendType" SG_ 100 L_2HKBD_RrPsModeDnSw 4;
BA_ "UserSigValidity" SG_ 100 L_2HKBD_RrPsModeDnSw 7;
BA_REL_ "GenSigTimeoutTime" BU_SG_REL_ L_ATCU SG_ 100 L_2HKBD_RrPsModeDnSw 1500;
BA_ "Version" SG_ 100 L_2HKBD_RrPsModeDnSw "23.09.01";
BA_ "GenSigSendType" SG_ 100 L_2HKBD_RrPsModeUpSw 4;
BA_ "UserSigValidity" SG_ 100 L_2HKBD_RrPsModeUpSw 7;
BA_REL_ "GenSigTimeoutTime" BU_SG_REL_ L_ATCU SG_ 100 L_2HKBD_RrPsModeUpSw 1500;
BA_ "Version" SG_ 100 L_2HKBD_RrPsModeUpSw "23.09.01";
BA_ "GenSigSendType" SG_ 100 L_2HKBD_RrPsModeVentSw 4;
BA_ "UserSigValidity" SG_ 100 L_2HKBD_RrPsModeVentSw 7;
BA_REL_ "GenSigTimeoutTime" BU_SG_REL_ L_ATCU SG_ 100 L_2HKBD_RrPsModeVentSw 1500;
BA_ "Version" SG_ 100 L_2HKBD_RrPsModeVentSw "23.09.01";
BA_ "GenSigSendType" SG_ 100 L_2HKBD_RrPsModeFloorSw 4;
BA_ "UserSigValidity" SG_ 100 L_2HKBD_RrPsModeFloorSw 7;
BA_REL_ "GenSigTimeoutTime" BU_SG_REL_ L_ATCU SG_ 100 L_2HKBD_RrPsModeFloorSw 1500;
BA_ "Version" SG_ 100 L_2HKBD_RrPsModeFloorSw "23.09.01";
BA_ "GenSigSendType" SG_ 100 L_2HKBD_RrPsModeBiLvlSw 4;
BA_ "UserSigValidity" SG_ 100 L_2HKBD_RrPsModeBiLvlSw 7;
BA_REL_ "GenSigTimeoutTime" BU_SG_REL_ L_ATCU SG_ 100 L_2HKBD_RrPsModeBiLvlSw 1500;
BA_ "Version" SG_ 100 L_2HKBD_RrPsModeBiLvlSw "23.09.01";
BA_ "GenSigSendType" SG_ 100 L_2HKBD_RrPsTempDnSw 4;
BA_ "UserSigValidity" SG_ 100 L_2HKBD_RrPsTempDnSw 7;
BA_REL_ "GenSigTimeoutTime" BU_SG_REL_ L_ATCU SG_ 100 L_2HKBD_RrPsTempDnSw 1500;
BA_ "Version" SG_ 100 L_2HKBD_RrPsTempDnSw "23.09.01";
BA_ "GenSigSendType" SG_ 100 L_2HKBD_RrPsTempUpSw 4;
BA_ "UserSigValidity" SG_ 100 L_2HKBD_RrPsTempUpSw 7;
BA_REL_ "GenSigTimeoutTime" BU_SG_REL_ L_ATCU SG_ 100 L_2HKBD_RrPsTempUpSw 1500;
BA_ "Version" SG_ 100 L_2HKBD_RrPsTempUpSw "23.09.01";
BA_ "GenSigSendType" SG_ 100 L_2HKBD_RrPsBlwUpSw 4;
BA_ "UserSigValidity" SG_ 100 L_2HKBD_RrPsBlwUpSw 7;
BA_REL_ "GenSigTimeoutTime" BU_SG_REL_ L_ATCU SG_ 100 L_2HKBD_RrPsBlwUpSw 1500;
BA_ "Version" SG_ 100 L_2HKBD_RrPsBlwUpSw "23.09.01";
BA_ "GenSigSendType" SG_ 100 L_2HKBD_RrDRModeVentSw 4;
BA_ "UserSigValidity" SG_ 100 L_2HKBD_RrDRModeVentSw 7;
BA_REL_ "GenSigTimeoutTime" BU_SG_REL_ L_ATCU SG_ 100 L_2HKBD_RrDRModeVentSw 1500;
BA_ "Version" SG_ 100 L_2HKBD_RrDRModeVentSw "23.09.01";
BA_ "GenSigSendType" SG_ 100 L_2HKBD_RrPsBlwDnSw 4;
BA_ "UserSigValidity" SG_ 100 L_2HKBD_RrPsBlwDnSw 7;
BA_REL_ "GenSigTimeoutTime" BU_SG_REL_ L_ATCU SG_ 100 L_2HKBD_RrPsBlwDnSw 1500;
BA_ "Version" SG_ 100 L_2HKBD_RrPsBlwDnSw "23.09.01";
BA_ "GenSigSendType" SG_ 100 L_2HKBD_RrPsAutoSw 4;
BA_ "UserSigValidity" SG_ 100 L_2HKBD_RrPsAutoSw 7;
BA_REL_ "GenSigTimeoutTime" BU_SG_REL_ L_ATCU SG_ 100 L_2HKBD_RrPsAutoSw 1500;
BA_ "Version" SG_ 100 L_2HKBD_RrPsAutoSw "23.09.01";
BA_ "GenSigSendType" SG_ 100 L_2HKBD_RrPsMultiAutoSw 4;
BA_ "GenSigStartValue" SG_ 100 L_2HKBD_RrPsMultiAutoSw 7;
BA_ "UserSigValidity" SG_ 100 L_2HKBD_RrPsMultiAutoSw 7;
BA_REL_ "GenSigTimeoutTime" BU_SG_REL_ L_ATCU SG_ 100 L_2HKBD_RrPsMultiAutoSw 1500;
BA_ "Version" SG_ 100 L_2HKBD_RrPsMultiAutoSw "24.01.00";
BA_ "GenSigSendType" SG_ 100 L_2HKBD_RrDrBlwDnOffSw 4;
BA_ "UserSigValidity" SG_ 100 L_2HKBD_RrDrBlwDnOffSw 7;
BA_REL_ "GenSigTimeoutTime" BU_SG_REL_ L_ATCU SG_ 100 L_2HKBD_RrDrBlwDnOffSw 1500;
BA_ "Version" SG_ 100 L_2HKBD_RrDrBlwDnOffSw "23.09.01";
BA_ "GenSigSendType" SG_ 100 L_2HKBD_RrPsBlwDnOffSw 4;
BA_ "UserSigValidity" SG_ 100 L_2HKBD_RrPsBlwDnOffSw 7;
BA_REL_ "GenSigTimeoutTime" BU_SG_REL_ L_ATCU SG_ 100 L_2HKBD_RrPsBlwDnOffSw 1500;
BA_ "Version" SG_ 100 L_2HKBD_RrPsBlwDnOffSw "23.09.01";
BA_ "GenSigSendType" SG_ 100 L_2HKBD_RrOnOffSet 4;
BA_ "UserSigValidity" SG_ 100 L_2HKBD_RrOnOffSet 7;
BA_REL_ "GenSigTimeoutTime" BU_SG_REL_ L_ATCU SG_ 100 L_2HKBD_RrOnOffSet 1500;
BA_ "Version" SG_ 100 L_2HKBD_RrOnOffSet "23.09.01";
BA_ "GenSigSendType" SG_ 100 L_2HKBD_RrDrblwUpMaxSw 4;
BA_ "UserSigValidity" SG_ 100 L_2HKBD_RrDrblwUpMaxSw 7;
BA_REL_ "GenSigTimeoutTime" BU_SG_REL_ L_ATCU SG_ 100 L_2HKBD_RrDrblwUpMaxSw 1500;
BA_ "Version" SG_ 100 L_2HKBD_RrDrblwUpMaxSw "25.05.04";
BA_ "GenSigSendType" SG_ 100 L_2HKBD_RrDrModeFloorSw 4;
BA_ "UserSigValidity" SG_ 100 L_2HKBD_RrDrModeFloorSw 7;
BA_REL_ "GenSigTimeoutTime" BU_SG_REL_ L_ATCU SG_ 100 L_2HKBD_RrDrModeFloorSw 1500;
BA_ "Version" SG_ 100 L_2HKBD_RrDrModeFloorSw "23.09.01";
BA_ "GenSigSendType" SG_ 100 L_2HKBD_RrPsblwUpMaxSw 4;
BA_ "UserSigValidity" SG_ 100 L_2HKBD_RrPsblwUpMaxSw 7;
BA_REL_ "GenSigTimeoutTime" BU_SG_REL_ L_ATCU SG_ 100 L_2HKBD_RrPsblwUpMaxSw 1500;
BA_ "Version" SG_ 100 L_2HKBD_RrPsblwUpMaxSw "25.05.04";
BA_ "GenSigSendType" SG_ 100 L_2HKBD_RrDrModeBiLvlSw 4;
BA_ "UserSigValidity" SG_ 100 L_2HKBD_RrDrModeBiLvlSw 7;
BA_REL_ "GenSigTimeoutTime" BU_SG_REL_ L_ATCU SG_ 100 L_2HKBD_RrDrModeBiLvlSw 1500;
BA_ "Version" SG_ 100 L_2HKBD_RrDrModeBiLvlSw "23.09.01";
BA_ "GenSigSendType" SG_ 100 L_2HKBD_RrDrTempDnSw 4;
BA_ "UserSigValidity" SG_ 100 L_2HKBD_RrDrTempDnSw 7;
BA_REL_ "GenSigTimeoutTime" BU_SG_REL_ L_ATCU SG_ 100 L_2HKBD_RrDrTempDnSw 1500;
BA_ "Version" SG_ 100 L_2HKBD_RrDrTempDnSw "23.09.01";
BA_ "GenSigSendType" SG_ 100 L_2HKBD_RrDrTempUpSw 4;
BA_ "UserSigValidity" SG_ 100 L_2HKBD_RrDrTempUpSw 7;
BA_REL_ "GenSigTimeoutTime" BU_SG_REL_ L_ATCU SG_ 100 L_2HKBD_RrDrTempUpSw 1500;
BA_ "Version" SG_ 100 L_2HKBD_RrDrTempUpSw "23.09.01";
BA_ "GenSigSendType" SG_ 100 L_2HKBD_RrDrBlwDnSw 4;
BA_ "UserSigValidity" SG_ 100 L_2HKBD_RrDrBlwDnSw 7;
BA_REL_ "GenSigTimeoutTime" BU_SG_REL_ L_ATCU SG_ 100 L_2HKBD_RrDrBlwDnSw 1500;
BA_ "Version" SG_ 100 L_2HKBD_RrDrBlwDnSw "23.09.01";
BA_ "GenSigSendType" SG_ 100 L_2HKBD_RrDrBlwUpSw 4;
BA_ "UserSigValidity" SG_ 100 L_2HKBD_RrDrBlwUpSw 7;
BA_REL_ "GenSigTimeoutTime" BU_SG_REL_ L_ATCU SG_ 100 L_2HKBD_RrDrBlwUpSw 1500;
BA_ "Version" SG_ 100 L_2HKBD_RrDrBlwUpSw "23.09.01";
BA_ "GenMsgSendType" BO_ 101 0;
BA_ "GenMsgCycleTime" BO_ 101 20;
BA_ "GenMsgCycleTimeFast" BO_ 101 0;
BA_ "GenMsgNrOfRepetition" BO_ 101 0;
BA_ "GenMsgDelayTime" BO_ 101 0;
BA_ "UserSigValidity" SG_ 101 L_2HKBD_RrFlrDuctSnsr 7;
BA_ "Version" SG_ 101 L_2HKBD_RrFlrDuctSnsr "23.09.05";
BA_ "UserSigValidity" SG_ 101 L_2HKBD_RrVntDuctSnsr 7;
BA_ "Version" SG_ 101 L_2HKBD_RrVntDuctSnsr "23.09.05";
BA_ "GenMsgCycleTime" BO_ 368 0;
BA_ "GenSigSendType" SG_ 368 L_ATCU_AVNCluUSMReset 4;
BA_ "UserSigValidity" SG_ 368 L_ATCU_AVNCluUSMReset 7;
BA_REL_ "GenSigTimeoutTime" BU_SG_REL_ L_2HKBD SG_ 368 L_ATCU_AVNCluUSMReset 0;
BA_REL_ "GenSigTimeoutTime" BU_SG_REL_ L_3HKBD SG_ 368 L_ATCU_AVNCluUSMReset 0;
BA_REL_ "GenSigTimeoutTime" BU_SG_REL_ L_EVNT SG_ 368 L_ATCU_AVNCluUSMReset 0;
BA_REL_ "GenSigTimeoutTime" BU_SG_REL_ L_HKBD SG_ 368 L_ATCU_AVNCluUSMReset 0;
BA_ "Version" SG_ 368 L_ATCU_AVNCluUSMReset "25.08.06";
BA_ "GenSigSendType" SG_ 368 L_ATCU_HVACPnlBckLight_Set 4;
BA_ "UserSigValidity" SG_ 368 L_ATCU_HVACPnlBckLight_Set 7;
BA_REL_ "GenSigTimeoutTime" BU_SG_REL_ L_2HKBD SG_ 368 L_ATCU_HVACPnlBckLight_Set 0;
BA_REL_ "GenSigTimeoutTime" BU_SG_REL_ L_3HKBD SG_ 368 L_ATCU_HVACPnlBckLight_Set 0;
BA_REL_ "GenSigTimeoutTime" BU_SG_REL_ L_EVNT SG_ 368 L_ATCU_HVACPnlBckLight_Set 0;
BA_REL_ "GenSigTimeoutTime" BU_SG_REL_ L_HKBD SG_ 368 L_ATCU_HVACPnlBckLight_Set 0;
BA_ "Version" SG_ 368 L_ATCU_HVACPnlBckLight_Set "25.08.06";
BA_ "GenSigSendType" SG_ 368 L_ATCU_MasterProfileResetIndex 4;
BA_ "UserSigValidity" SG_ 368 L_ATCU_MasterProfileResetIndex 7;
BA_REL_ "GenSigTimeoutTime" BU_SG_REL_ L_2HKBD SG_ 368 L_ATCU_MasterProfileResetIndex 0;
BA_REL_ "GenSigTimeoutTime" BU_SG_REL_ L_3HKBD SG_ 368 L_ATCU_MasterProfileResetIndex 0;
BA_REL_ "GenSigTimeoutTime" BU_SG_REL_ L_EVNT SG_ 368 L_ATCU_MasterProfileResetIndex 0;
BA_REL_ "GenSigTimeoutTime" BU_SG_REL_ L_HKBD SG_ 368 L_ATCU_MasterProfileResetIndex 0;
BA_ "Version" SG_ 368 L_ATCU_MasterProfileResetIndex "25.11.01";
BA_ "GenMsgSendType" BO_ 849 0;
BA_ "GenMsgCycleTime" BO_ 849 500;
BA_ "Description" SG_ 849 L_ATCU_Lib_SnsrInCarTemp "This value only use for ATCU Library data monitoring (Only use before SOP)";
BA_ "GenSigSendType" SG_ 849 L_ATCU_Lib_SnsrInCarTemp 4;
BA_ "UserSigValidity" SG_ 849 L_ATCU_Lib_SnsrInCarTemp 0;
BA_REL_ "GenSigTimeoutTime" BU_SG_REL_ L_ATCU_vMON SG_ 849 L_ATCU_Lib_SnsrInCarTemp 5000;
BA_ "Version" SG_ 849 L_ATCU_Lib_SnsrInCarTemp "23.11.10";
BA_ "Description" SG_ 849 L_ATCU_Lib_SnsrAMBTemp "This value only use for ATCU Library data monitoring (Only use before SOP)";
BA_ "GenSigSendType" SG_ 849 L_ATCU_Lib_SnsrAMBTemp 4;
BA_ "UserSigValidity" SG_ 849 L_ATCU_Lib_SnsrAMBTemp 0;
BA_REL_ "GenSigTimeoutTime" BU_SG_REL_ L_ATCU_vMON SG_ 849 L_ATCU_Lib_SnsrAMBTemp 5000;
BA_ "Version" SG_ 849 L_ATCU_Lib_SnsrAMBTemp "23.11.10";
BA_ "Description" SG_ 849 L_ATCU_Lib_SnsrDOH "This value only use for ATCU Library data monitoring (Only use before SOP)";
BA_ "GenSigSendType" SG_ 849 L_ATCU_Lib_SnsrDOH 4;
BA_ "UserSigValidity" SG_ 849 L_ATCU_Lib_SnsrDOH 0;
BA_REL_ "GenSigTimeoutTime" BU_SG_REL_ L_ATCU_vMON SG_ 849 L_ATCU_Lib_SnsrDOH 5000;
BA_ "Version" SG_ 849 L_ATCU_Lib_SnsrDOH "23.11.10";
BA_ "Description" SG_ 849 L_ATCU_Lib_SnsrEvapTemp "This value only use for ATCU Library data monitoring (Only use before SOP)";
BA_ "GenSigSendType" SG_ 849 L_ATCU_Lib_SnsrEvapTemp 4;
BA_ "UserSigValidity" SG_ 849 L_ATCU_Lib_SnsrEvapTemp 0;
BA_REL_ "GenSigTimeoutTime" BU_SG_REL_ L_ATCU_vMON SG_ 849 L_ATCU_Lib_SnsrEvapTemp 5000;
BA_ "Version" SG_ 849 L_ATCU_Lib_SnsrEvapTemp "23.11.10";
BA_ "GenMsgSendType" BO_ 850 0;
BA_ "GenMsgCycleTime" BO_ 850 500;
BA_ "Description" SG_ 850 L_ATCU_Lib_SnsrWaterTemp "This value only use for ATCU Library data monitoring (Only use before SOP)";
BA_ "GenSigSendType" SG_ 850 L_ATCU_Lib_SnsrWaterTemp 4;
BA_ "UserSigValidity" SG_ 850 L_ATCU_Lib_SnsrWaterTemp 0;
BA_REL_ "GenSigTimeoutTime" BU_SG_REL_ L_ATCU_vMON SG_ 850 L_ATCU_Lib_SnsrWaterTemp 5000;
BA_ "Version" SG_ 850 L_ATCU_Lib_SnsrWaterTemp "23.11.10";
BA_ "Description" SG_ 850 L_ATCU_Lib_SnsrFineDust "This value only use for ATCU Library data monitoring (Only use before SOP)";
BA_ "GenSigSendType" SG_ 850 L_ATCU_Lib_SnsrFineDust 4;
BA_ "UserSigValidity" SG_ 850 L_ATCU_Lib_SnsrFineDust 0;
BA_REL_ "GenSigTimeoutTime" BU_SG_REL_ L_ATCU_vMON SG_ 850 L_ATCU_Lib_SnsrFineDust 5000;
BA_ "Version" SG_ 850 L_ATCU_Lib_SnsrFineDust "23.11.10";
BA_ "Description" SG_ 850 L_ATCU_Lib_SnsrLHPhoto "This value only use for ATCU Library data monitoring (Only use before SOP)";
BA_ "GenSigSendType" SG_ 850 L_ATCU_Lib_SnsrLHPhoto 4;
BA_ "UserSigValidity" SG_ 850 L_ATCU_Lib_SnsrLHPhoto 0;
BA_REL_ "GenSigTimeoutTime" BU_SG_REL_ L_ATCU_vMON SG_ 850 L_ATCU_Lib_SnsrLHPhoto 5000;
BA_ "Version" SG_ 850 L_ATCU_Lib_SnsrLHPhoto "23.11.10";
BA_ "Description" SG_ 850 L_ATCU_Lib_SnsrRHPhoto "This value only use for ATCU Library data monitoring (Only use before SOP)";
BA_ "GenSigSendType" SG_ 850 L_ATCU_Lib_SnsrRHPhoto 4;
BA_ "UserSigValidity" SG_ 850 L_ATCU_Lib_SnsrRHPhoto 0;
BA_REL_ "GenSigTimeoutTime" BU_SG_REL_ L_ATCU_vMON SG_ 850 L_ATCU_Lib_SnsrRHPhoto 5000;
BA_ "Version" SG_ 850 L_ATCU_Lib_SnsrRHPhoto "23.11.10";
BA_ "GenMsgSendType" BO_ 852 0;
BA_ "GenMsgCycleTime" BO_ 852 500;
BA_ "Description" SG_ 852 L_ATCU_Lib_Snsr2LHVentDuct "This value only use for ATCU Library data monitoring (Only use before SOP)";
BA_ "GenSigSendType" SG_ 852 L_ATCU_Lib_Snsr2LHVentDuct 4;
BA_ "UserSigValidity" SG_ 852 L_ATCU_Lib_Snsr2LHVentDuct 0;
BA_REL_ "GenSigTimeoutTime" BU_SG_REL_ L_ATCU_vMON SG_ 852 L_ATCU_Lib_Snsr2LHVentDuct 5000;
BA_ "Version" SG_ 852 L_ATCU_Lib_Snsr2LHVentDuct "23.11.10";
BA_ "Description" SG_ 852 L_ATCU_Lib_Snsr2LHFloorDuct "This value only use for ATCU Library data monitoring (Only use before SOP)";
BA_ "GenSigSendType" SG_ 852 L_ATCU_Lib_Snsr2LHFloorDuct 4;
BA_ "UserSigValidity" SG_ 852 L_ATCU_Lib_Snsr2LHFloorDuct 0;
BA_REL_ "GenSigTimeoutTime" BU_SG_REL_ L_ATCU_vMON SG_ 852 L_ATCU_Lib_Snsr2LHFloorDuct 5000;
BA_ "Version" SG_ 852 L_ATCU_Lib_Snsr2LHFloorDuct "23.11.10";
BA_ "Description" SG_ 852 L_ATCU_Lib_SnsrDEFDuct "This value only use for ATCU Library data monitoring (Only use before SOP)";
BA_ "GenSigSendType" SG_ 852 L_ATCU_Lib_SnsrDEFDuct 4;
BA_ "UserSigValidity" SG_ 852 L_ATCU_Lib_SnsrDEFDuct 0;
BA_REL_ "GenSigTimeoutTime" BU_SG_REL_ L_ATCU_vMON SG_ 852 L_ATCU_Lib_SnsrDEFDuct 5000;
BA_ "Version" SG_ 852 L_ATCU_Lib_SnsrDEFDuct "23.11.10";
BA_ "GenMsgSendType" BO_ 853 0;
BA_ "GenMsgCycleTime" BO_ 853 500;
BA_ "Description" SG_ 853 L_ATCU_Lib_OffSw "This value only use for ATCU Library data monitoring (Only use before SOP)";
BA_ "GenSigSendType" SG_ 853 L_ATCU_Lib_OffSw 4;
BA_ "UserSigValidity" SG_ 853 L_ATCU_Lib_OffSw 0;
BA_REL_ "GenSigTimeoutTime" BU_SG_REL_ L_ATCU_vMON SG_ 853 L_ATCU_Lib_OffSw 5000;
BA_ "Version" SG_ 853 L_ATCU_Lib_OffSw "23.11.10";
BA_ "Description" SG_ 853 L_ATCU_Lib_AutoSw "This value only use for ATCU Library data monitoring (Only use before SOP)";
BA_ "GenSigSendType" SG_ 853 L_ATCU_Lib_AutoSw 4;
BA_ "UserSigValidity" SG_ 853 L_ATCU_Lib_AutoSw 0;
BA_REL_ "GenSigTimeoutTime" BU_SG_REL_ L_ATCU_vMON SG_ 853 L_ATCU_Lib_AutoSw 5000;
BA_ "Version" SG_ 853 L_ATCU_Lib_AutoSw "23.11.10";
BA_ "Description" SG_ 853 L_ATCU_Lib_BlrDnOffReq "This value only use for ATCU Library data monitoring (Only use before SOP)";
BA_ "GenSigSendType" SG_ 853 L_ATCU_Lib_BlrDnOffReq 4;
BA_ "UserSigValidity" SG_ 853 L_ATCU_Lib_BlrDnOffReq 0;
BA_REL_ "GenSigTimeoutTime" BU_SG_REL_ L_ATCU_vMON SG_ 853 L_ATCU_Lib_BlrDnOffReq 5000;
BA_ "Version" SG_ 853 L_ATCU_Lib_BlrDnOffReq "23.11.10";
BA_ "Description" SG_ 853 L_ATCU_Lib_IntakeRECSw "This value only use for ATCU Library data monitoring (Only use before SOP)";
BA_ "GenSigSendType" SG_ 853 L_ATCU_Lib_IntakeRECSw 4;
BA_ "UserSigValidity" SG_ 853 L_ATCU_Lib_IntakeRECSw 0;
BA_REL_ "GenSigTimeoutTime" BU_SG_REL_ L_ATCU_vMON SG_ 853 L_ATCU_Lib_IntakeRECSw 5000;
BA_ "Version" SG_ 853 L_ATCU_Lib_IntakeRECSw "23.11.10";
BA_ "Description" SG_ 853 L_ATCU_Lib_IntakeFRESw "This value only use for ATCU Library data monitoring (Only use before SOP)";
BA_ "GenSigSendType" SG_ 853 L_ATCU_Lib_IntakeFRESw 4;
BA_ "UserSigValidity" SG_ 853 L_ATCU_Lib_IntakeFRESw 0;
BA_REL_ "GenSigTimeoutTime" BU_SG_REL_ L_ATCU_vMON SG_ 853 L_ATCU_Lib_IntakeFRESw 5000;
BA_ "Version" SG_ 853 L_ATCU_Lib_IntakeFRESw "23.11.10";
BA_ "Description" SG_ 853 L_ATCU_Lib_ACSw "This value only use for ATCU Library data monitoring (Only use before SOP)";
BA_ "GenSigSendType" SG_ 853 L_ATCU_Lib_ACSw 4;
BA_ "UserSigValidity" SG_ 853 L_ATCU_Lib_ACSw 0;
BA_REL_ "GenSigTimeoutTime" BU_SG_REL_ L_ATCU_vMON SG_ 853 L_ATCU_Lib_ACSw 5000;
BA_ "Version" SG_ 853 L_ATCU_Lib_ACSw "23.11.10";
BA_ "Description" SG_ 853 L_ATCU_Lib_DEFSw "This value only use for ATCU Library data monitoring (Only use before SOP)";
BA_ "GenSigSendType" SG_ 853 L_ATCU_Lib_DEFSw 4;
BA_ "UserSigValidity" SG_ 853 L_ATCU_Lib_DEFSw 0;
BA_REL_ "GenSigTimeoutTime" BU_SG_REL_ L_ATCU_vMON SG_ 853 L_ATCU_Lib_DEFSw 5000;
BA_ "Version" SG_ 853 L_ATCU_Lib_DEFSw "23.11.10";
BA_ "Description" SG_ 853 L_ATCU_Lib_DrvTempUpSw "This value only use for ATCU Library data monitoring (Only use before SOP)";
BA_ "GenSigSendType" SG_ 853 L_ATCU_Lib_DrvTempUpSw 4;
BA_ "UserSigValidity" SG_ 853 L_ATCU_Lib_DrvTempUpSw 0;
BA_REL_ "GenSigTimeoutTime" BU_SG_REL_ L_ATCU_vMON SG_ 853 L_ATCU_Lib_DrvTempUpSw 5000;
BA_ "Version" SG_ 853 L_ATCU_Lib_DrvTempUpSw "23.11.10";
BA_ "Description" SG_ 853 L_ATCU_Lib_DrvTempDnSw "This value only use for ATCU Library data monitoring (Only use before SOP)";
BA_ "GenSigSendType" SG_ 853 L_ATCU_Lib_DrvTempDnSw 4;
BA_ "UserSigValidity" SG_ 853 L_ATCU_Lib_DrvTempDnSw 0;
BA_REL_ "GenSigTimeoutTime" BU_SG_REL_ L_ATCU_vMON SG_ 853 L_ATCU_Lib_DrvTempDnSw 5000;
BA_ "Version" SG_ 853 L_ATCU_Lib_DrvTempDnSw "23.11.10";
BA_ "Description" SG_ 853 L_ATCU_Lib_AstTempUpSw "This value only use for ATCU Library data monitoring (Only use before SOP)";
BA_ "GenSigSendType" SG_ 853 L_ATCU_Lib_AstTempUpSw 4;
BA_ "UserSigValidity" SG_ 853 L_ATCU_Lib_AstTempUpSw 0;
BA_REL_ "GenSigTimeoutTime" BU_SG_REL_ L_ATCU_vMON SG_ 853 L_ATCU_Lib_AstTempUpSw 5000;
BA_ "Version" SG_ 853 L_ATCU_Lib_AstTempUpSw "23.11.10";
BA_ "Description" SG_ 853 L_ATCU_Lib_AstTempDnSw "This value only use for ATCU Library data monitoring (Only use before SOP)";
BA_ "GenSigSendType" SG_ 853 L_ATCU_Lib_AstTempDnSw 4;
BA_ "UserSigValidity" SG_ 853 L_ATCU_Lib_AstTempDnSw 0;
BA_REL_ "GenSigTimeoutTime" BU_SG_REL_ L_ATCU_vMON SG_ 853 L_ATCU_Lib_AstTempDnSw 5000;
BA_ "Version" SG_ 853 L_ATCU_Lib_AstTempDnSw "23.11.10";
BA_ "Description" SG_ 853 L_ATCU_Lib_SyncSw "This value only use for ATCU Library data monitoring (Only use before SOP)";
BA_ "GenSigSendType" SG_ 853 L_ATCU_Lib_SyncSw 4;
BA_ "UserSigValidity" SG_ 853 L_ATCU_Lib_SyncSw 0;
BA_REL_ "GenSigTimeoutTime" BU_SG_REL_ L_ATCU_vMON SG_ 853 L_ATCU_Lib_SyncSw 5000;
BA_ "Version" SG_ 853 L_ATCU_Lib_SyncSw "23.11.10";
BA_ "Description" SG_ 853 L_ATCU_Lib_ModSw "This value only use for ATCU Library data monitoring (Only use before SOP)";
BA_ "GenSigSendType" SG_ 853 L_ATCU_Lib_ModSw 4;
BA_ "UserSigValidity" SG_ 853 L_ATCU_Lib_ModSw 0;
BA_REL_ "GenSigTimeoutTime" BU_SG_REL_ L_ATCU_vMON SG_ 853 L_ATCU_Lib_ModSw 5000;
BA_ "Version" SG_ 853 L_ATCU_Lib_ModSw "23.11.10";
BA_ "Description" SG_ 853 L_ATCU_Lib_DrvOnlySw "This value only use for ATCU Library data monitoring (Only use before SOP)";
BA_ "GenSigSendType" SG_ 853 L_ATCU_Lib_DrvOnlySw 4;
BA_ "UserSigValidity" SG_ 853 L_ATCU_Lib_DrvOnlySw 0;
BA_REL_ "GenSigTimeoutTime" BU_SG_REL_ L_ATCU_vMON SG_ 853 L_ATCU_Lib_DrvOnlySw 5000;
BA_ "Version" SG_ 853 L_ATCU_Lib_DrvOnlySw "23.11.10";
BA_ "Description" SG_ 853 L_ATCU_Lib_ClimateSw "This value only use for ATCU Library data monitoring (Only use before SOP)";
BA_ "GenSigSendType" SG_ 853 L_ATCU_Lib_ClimateSw 4;
BA_ "UserSigValidity" SG_ 853 L_ATCU_Lib_ClimateSw 0;
BA_REL_ "GenSigTimeoutTime" BU_SG_REL_ L_ATCU_vMON SG_ 853 L_ATCU_Lib_ClimateSw 5000;
BA_ "Version" SG_ 853 L_ATCU_Lib_ClimateSw "23.11.10";
BA_ "Description" SG_ 853 L_ATCU_Lib_RearDEFSw "This value only use for ATCU Library data monitoring (Only use before SOP)";
BA_ "GenSigSendType" SG_ 853 L_ATCU_Lib_RearDEFSw 4;
BA_ "UserSigValidity" SG_ 853 L_ATCU_Lib_RearDEFSw 0;
BA_REL_ "GenSigTimeoutTime" BU_SG_REL_ L_ATCU_vMON SG_ 853 L_ATCU_Lib_RearDEFSw 5000;
BA_ "Version" SG_ 853 L_ATCU_Lib_RearDEFSw "23.11.10";
BA_ "Description" SG_ 853 L_ATCU_Lib_StrWhlSw "This value only use for ATCU Library data monitoring (Only use before SOP)";
BA_ "GenSigSendType" SG_ 853 L_ATCU_Lib_StrWhlSw 4;
BA_ "UserSigValidity" SG_ 853 L_ATCU_Lib_StrWhlSw 0;
BA_REL_ "GenSigTimeoutTime" BU_SG_REL_ L_ATCU_vMON SG_ 853 L_ATCU_Lib_StrWhlSw 5000;
BA_ "Version" SG_ 853 L_ATCU_Lib_StrWhlSw "23.11.10";
BA_ "Description" SG_ 853 L_ATCU_Lib_DrvSeatHeatSw "This value only use for ATCU Library data monitoring (Only use before SOP)";
BA_ "GenSigSendType" SG_ 853 L_ATCU_Lib_DrvSeatHeatSw 4;
BA_ "UserSigValidity" SG_ 853 L_ATCU_Lib_DrvSeatHeatSw 0;
BA_REL_ "GenSigTimeoutTime" BU_SG_REL_ L_ATCU_vMON SG_ 853 L_ATCU_Lib_DrvSeatHeatSw 5000;
BA_ "Version" SG_ 853 L_ATCU_Lib_DrvSeatHeatSw "23.11.10";
BA_ "Description" SG_ 853 L_ATCU_Lib_DrvSeatVentSw "This value only use for ATCU Library data monitoring (Only use before SOP)";
BA_ "GenSigSendType" SG_ 853 L_ATCU_Lib_DrvSeatVentSw 4;
BA_ "UserSigValidity" SG_ 853 L_ATCU_Lib_DrvSeatVentSw 0;
BA_REL_ "GenSigTimeoutTime" BU_SG_REL_ L_ATCU_vMON SG_ 853 L_ATCU_Lib_DrvSeatVentSw 5000;
BA_ "Version" SG_ 853 L_ATCU_Lib_DrvSeatVentSw "23.11.10";
BA_ "Description" SG_ 853 L_ATCU_Lib_AstSeatHeatSw "This value only use for ATCU Library data monitoring (Only use before SOP)";
BA_ "GenSigSendType" SG_ 853 L_ATCU_Lib_AstSeatHeatSw 4;
BA_ "UserSigValidity" SG_ 853 L_ATCU_Lib_AstSeatHeatSw 0;
BA_REL_ "GenSigTimeoutTime" BU_SG_REL_ L_ATCU_vMON SG_ 853 L_ATCU_Lib_AstSeatHeatSw 5000;
BA_ "Version" SG_ 853 L_ATCU_Lib_AstSeatHeatSw "23.11.10";
BA_ "Description" SG_ 853 L_ATCU_Lib_AstSeatVentSw "This value only use for ATCU Library data monitoring (Only use before SOP)";
BA_ "GenSigSendType" SG_ 853 L_ATCU_Lib_AstSeatVentSw 4;
BA_ "UserSigValidity" SG_ 853 L_ATCU_Lib_AstSeatVentSw 0;
BA_REL_ "GenSigTimeoutTime" BU_SG_REL_ L_ATCU_vMON SG_ 853 L_ATCU_Lib_AstSeatVentSw 5000;
BA_ "Version" SG_ 853 L_ATCU_Lib_AstSeatVentSw "23.11.10";
BA_ "Description" SG_ 853 L_ATCU_Lib_DrvSeatTumblerSw "This value only use for ATCU Library data monitoring (Only use before SOP)";
BA_ "GenSigSendType" SG_ 853 L_ATCU_Lib_DrvSeatTumblerSw 4;
BA_ "UserSigValidity" SG_ 853 L_ATCU_Lib_DrvSeatTumblerSw 0;
BA_REL_ "GenSigTimeoutTime" BU_SG_REL_ L_ATCU_vMON SG_ 853 L_ATCU_Lib_DrvSeatTumblerSw 5000;
BA_ "Version" SG_ 853 L_ATCU_Lib_DrvSeatTumblerSw "23.11.10";
BA_ "Description" SG_ 853 L_ATCU_Lib_ModUpSw "This value only use for ATCU Library data monitoring (Only use before SOP)";
BA_ "GenSigSendType" SG_ 853 L_ATCU_Lib_ModUpSw 4;
BA_ "UserSigValidity" SG_ 853 L_ATCU_Lib_ModUpSw 0;
BA_REL_ "GenSigTimeoutTime" BU_SG_REL_ L_ATCU_vMON SG_ 853 L_ATCU_Lib_ModUpSw 5000;
BA_ "Version" SG_ 853 L_ATCU_Lib_ModUpSw "23.11.10";
BA_ "Description" SG_ 853 L_ATCU_Lib_AstSeatTumblerSw "This value only use for ATCU Library data monitoring (Only use before SOP)";
BA_ "GenSigSendType" SG_ 853 L_ATCU_Lib_AstSeatTumblerSw 4;
BA_ "UserSigValidity" SG_ 853 L_ATCU_Lib_AstSeatTumblerSw 0;
BA_REL_ "GenSigTimeoutTime" BU_SG_REL_ L_ATCU_vMON SG_ 853 L_ATCU_Lib_AstSeatTumblerSw 5000;
BA_ "Version" SG_ 853 L_ATCU_Lib_AstSeatTumblerSw "23.11.10";
BA_ "Description" SG_ 853 L_ATCU_Lib_2ndSyncSetSw "This value only use for ATCU Library data monitoring (Only use before SOP)";
BA_ "GenSigSendType" SG_ 853 L_ATCU_Lib_2ndSyncSetSw 4;
BA_ "UserSigValidity" SG_ 853 L_ATCU_Lib_2ndSyncSetSw 0;
BA_REL_ "GenSigTimeoutTime" BU_SG_REL_ L_ATCU_vMON SG_ 853 L_ATCU_Lib_2ndSyncSetSw 5000;
BA_ "Version" SG_ 853 L_ATCU_Lib_2ndSyncSetSw "25.11.02";
BA_ "Description" SG_ 853 L_ATCU_Lib_2ndOffSw "This value only use for ATCU Library data monitoring (Only use before SOP)";
BA_ "GenSigSendType" SG_ 853 L_ATCU_Lib_2ndOffSw 4;
BA_ "UserSigValidity" SG_ 853 L_ATCU_Lib_2ndOffSw 0;
BA_REL_ "GenSigTimeoutTime" BU_SG_REL_ L_ATCU_vMON SG_ 853 L_ATCU_Lib_2ndOffSw 5000;
BA_ "Version" SG_ 853 L_ATCU_Lib_2ndOffSw "25.11.02";
BA_ "Description" SG_ 853 L_ATCU_Lib_2ndLockSetSw "This value only use for ATCU Library data monitoring (Only use before SOP)";
BA_ "GenSigSendType" SG_ 853 L_ATCU_Lib_2ndLockSetSw 4;
BA_ "UserSigValidity" SG_ 853 L_ATCU_Lib_2ndLockSetSw 0;
BA_REL_ "GenSigTimeoutTime" BU_SG_REL_ L_ATCU_vMON SG_ 853 L_ATCU_Lib_2ndLockSetSw 5000;
BA_ "Version" SG_ 853 L_ATCU_Lib_2ndLockSetSw "25.11.02";
BA_ "Description" SG_ 853 L_ATCU_Lib_ModDnSw "This value only use for ATCU Library data monitoring (Only use before SOP)";
BA_ "GenSigSendType" SG_ 853 L_ATCU_Lib_ModDnSw 4;
BA_ "UserSigValidity" SG_ 853 L_ATCU_Lib_ModDnSw 0;
BA_REL_ "GenSigTimeoutTime" BU_SG_REL_ L_ATCU_vMON SG_ 853 L_ATCU_Lib_ModDnSw 5000;
BA_ "Version" SG_ 853 L_ATCU_Lib_ModDnSw "23.11.10";
BA_ "Description" SG_ 853 L_ATCU_Lib_BlrUpSw "This value only use for ATCU Library data monitoring (Only use before SOP)";
BA_ "GenSigSendType" SG_ 853 L_ATCU_Lib_BlrUpSw 4;
BA_ "UserSigValidity" SG_ 853 L_ATCU_Lib_BlrUpSw 0;
BA_REL_ "GenSigTimeoutTime" BU_SG_REL_ L_ATCU_vMON SG_ 853 L_ATCU_Lib_BlrUpSw 5000;
BA_ "Version" SG_ 853 L_ATCU_Lib_BlrUpSw "23.11.10";
BA_ "Description" SG_ 853 L_ATCU_Lib_BlrDnSw "This value only use for ATCU Library data monitoring (Only use before SOP)";
BA_ "GenSigSendType" SG_ 853 L_ATCU_Lib_BlrDnSw 4;
BA_ "UserSigValidity" SG_ 853 L_ATCU_Lib_BlrDnSw 0;
BA_REL_ "GenSigTimeoutTime" BU_SG_REL_ L_ATCU_vMON SG_ 853 L_ATCU_Lib_BlrDnSw 5000;
BA_ "Version" SG_ 853 L_ATCU_Lib_BlrDnSw "23.11.10";
BA_ "GenMsgSendType" BO_ 854 0;
BA_ "GenMsgCycleTime" BO_ 854 500;
BA_ "Description" SG_ 854 L_ATCU_Lib_OffSetSw "This value only use for ATCU Library data monitoring (Only use before SOP)";
BA_ "GenSigSendType" SG_ 854 L_ATCU_Lib_OffSetSw 4;
BA_ "UserSigValidity" SG_ 854 L_ATCU_Lib_OffSetSw 0;
BA_REL_ "GenSigTimeoutTime" BU_SG_REL_ L_ATCU_vMON SG_ 854 L_ATCU_Lib_OffSetSw 5000;
BA_ "Version" SG_ 854 L_ATCU_Lib_OffSetSw "23.11.10";
BA_ "Description" SG_ 854 L_ATCU_Lib_BlrSetSw "This value only use for ATCU Library data monitoring (Only use before SOP)";
BA_ "GenSigSendType" SG_ 854 L_ATCU_Lib_BlrSetSw 4;
BA_ "UserSigValidity" SG_ 854 L_ATCU_Lib_BlrSetSw 0;
BA_REL_ "GenSigTimeoutTime" BU_SG_REL_ L_ATCU_vMON SG_ 854 L_ATCU_Lib_BlrSetSw 5000;
BA_ "Version" SG_ 854 L_ATCU_Lib_BlrSetSw "23.11.10";
BA_ "Description" SG_ 854 L_ATCU_Lib_DEFSetSw "This value only use for ATCU Library data monitoring (Only use before SOP)";
BA_ "GenSigSendType" SG_ 854 L_ATCU_Lib_DEFSetSw 4;
BA_ "UserSigValidity" SG_ 854 L_ATCU_Lib_DEFSetSw 0;
BA_REL_ "GenSigTimeoutTime" BU_SG_REL_ L_ATCU_vMON SG_ 854 L_ATCU_Lib_DEFSetSw 5000;
BA_ "Version" SG_ 854 L_ATCU_Lib_DEFSetSw "25.11.02";
BA_ "Description" SG_ 854 L_ATCU_Lib_SyncSetSw "This value only use for ATCU Library data monitoring (Only use before SOP)";
BA_ "GenSigSendType" SG_ 854 L_ATCU_Lib_SyncSetSw 4;
BA_ "UserSigValidity" SG_ 854 L_ATCU_Lib_SyncSetSw 0;
BA_REL_ "GenSigTimeoutTime" BU_SG_REL_ L_ATCU_vMON SG_ 854 L_ATCU_Lib_SyncSetSw 5000;
BA_ "Version" SG_ 854 L_ATCU_Lib_SyncSetSw "25.11.02";
BA_ "Description" SG_ 854 L_ATCU_Lib_AutoSetSw "This value only use for ATCU Library data monitoring (Only use before SOP)";
BA_ "GenSigSendType" SG_ 854 L_ATCU_Lib_AutoSetSw 4;
BA_ "UserSigValidity" SG_ 854 L_ATCU_Lib_AutoSetSw 0;
BA_REL_ "GenSigTimeoutTime" BU_SG_REL_ L_ATCU_vMON SG_ 854 L_ATCU_Lib_AutoSetSw 5000;
BA_ "Version" SG_ 854 L_ATCU_Lib_AutoSetSw "23.11.10";
BA_ "Description" SG_ 854 L_ATCU_Lib_DrvOnlySetSw "This value only use for ATCU Library data monitoring (Only use before SOP)";
BA_ "GenSigSendType" SG_ 854 L_ATCU_Lib_DrvOnlySetSw 4;
BA_ "UserSigValidity" SG_ 854 L_ATCU_Lib_DrvOnlySetSw 0;
BA_REL_ "GenSigTimeoutTime" BU_SG_REL_ L_ATCU_vMON SG_ 854 L_ATCU_Lib_DrvOnlySetSw 5000;
BA_ "Version" SG_ 854 L_ATCU_Lib_DrvOnlySetSw "25.11.02";
BA_ "Description" SG_ 854 L_ATCU_Lib_IntakeSetSw "This value only use for ATCU Library data monitoring (Only use before SOP)";
BA_ "GenSigSendType" SG_ 854 L_ATCU_Lib_IntakeSetSw 4;
BA_ "UserSigValidity" SG_ 854 L_ATCU_Lib_IntakeSetSw 0;
BA_REL_ "GenSigTimeoutTime" BU_SG_REL_ L_ATCU_vMON SG_ 854 L_ATCU_Lib_IntakeSetSw 5000;
BA_ "Version" SG_ 854 L_ATCU_Lib_IntakeSetSw "25.11.02";
BA_ "Description" SG_ 854 L_ATCU_Lib_DrvTempSetSw "This value only use for ATCU Library data monitoring (Only use before SOP)";
BA_ "GenSigSendType" SG_ 854 L_ATCU_Lib_DrvTempSetSw 4;
BA_ "UserSigValidity" SG_ 854 L_ATCU_Lib_DrvTempSetSw 0;
BA_REL_ "GenSigTimeoutTime" BU_SG_REL_ L_ATCU_vMON SG_ 854 L_ATCU_Lib_DrvTempSetSw 5000;
BA_ "Version" SG_ 854 L_ATCU_Lib_DrvTempSetSw "25.11.02";
BA_ "Description" SG_ 854 L_ATCU_Lib_MultiAutoSetSw "This value only use for ATCU Library data monitoring (Only use before SOP)";
BA_ "GenSigSendType" SG_ 854 L_ATCU_Lib_MultiAutoSetSw 4;
BA_ "UserSigValidity" SG_ 854 L_ATCU_Lib_MultiAutoSetSw 0;
BA_REL_ "GenSigTimeoutTime" BU_SG_REL_ L_ATCU_vMON SG_ 854 L_ATCU_Lib_MultiAutoSetSw 5000;
BA_ "Version" SG_ 854 L_ATCU_Lib_MultiAutoSetSw "23.11.10";
BA_ "Description" SG_ 854 L_ATCU_Lib_AstTempSetSw "This value only use for ATCU Library data monitoring (Only use before SOP)";
BA_ "GenSigSendType" SG_ 854 L_ATCU_Lib_AstTempSetSw 4;
BA_ "UserSigValidity" SG_ 854 L_ATCU_Lib_AstTempSetSw 0;
BA_REL_ "GenSigTimeoutTime" BU_SG_REL_ L_ATCU_vMON SG_ 854 L_ATCU_Lib_AstTempSetSw 5000;
BA_ "Version" SG_ 854 L_ATCU_Lib_AstTempSetSw "25.11.02";
BA_ "Description" SG_ 854 L_ATCU_Lib_DrvTempClickCnt "This value only use for ATCU Library data monitoring (Only use before SOP)";
BA_ "GenSigSendType" SG_ 854 L_ATCU_Lib_DrvTempClickCnt 4;
BA_ "GenSigStartValue" SG_ 854 L_ATCU_Lib_DrvTempClickCnt 255;
BA_ "UserSigValidity" SG_ 854 L_ATCU_Lib_DrvTempClickCnt 0;
BA_REL_ "GenSigTimeoutTime" BU_SG_REL_ L_ATCU_vMON SG_ 854 L_ATCU_Lib_DrvTempClickCnt 5000;
BA_ "Version" SG_ 854 L_ATCU_Lib_DrvTempClickCnt "24.05.08";
BA_ "Description" SG_ 854 L_ATCU_Lib_AstTempClickCnt "This value only use for ATCU Library data monitoring (Only use before SOP)";
BA_ "GenSigSendType" SG_ 854 L_ATCU_Lib_AstTempClickCnt 4;
BA_ "GenSigStartValue" SG_ 854 L_ATCU_Lib_AstTempClickCnt 255;
BA_ "UserSigValidity" SG_ 854 L_ATCU_Lib_AstTempClickCnt 0;
BA_REL_ "GenSigTimeoutTime" BU_SG_REL_ L_ATCU_vMON SG_ 854 L_ATCU_Lib_AstTempClickCnt 5000;
BA_ "Version" SG_ 854 L_ATCU_Lib_AstTempClickCnt "24.05.08";
BA_ "Description" SG_ 854 L_ATCU_Lib_ACSetSw "This value only use for ATCU Library data monitoring (Only use before SOP)";
BA_ "GenSigSendType" SG_ 854 L_ATCU_Lib_ACSetSw 4;
BA_ "UserSigValidity" SG_ 854 L_ATCU_Lib_ACSetSw 0;
BA_REL_ "GenSigTimeoutTime" BU_SG_REL_ L_ATCU_vMON SG_ 854 L_ATCU_Lib_ACSetSw 5000;
BA_ "Version" SG_ 854 L_ATCU_Lib_ACSetSw "23.11.10";
BA_ "Description" SG_ 854 L_ATCU_Lib_ModSetSw "This value only use for ATCU Library data monitoring (Only use before SOP)";
BA_ "GenSigSendType" SG_ 854 L_ATCU_Lib_ModSetSw 4;
BA_ "UserSigValidity" SG_ 854 L_ATCU_Lib_ModSetSw 0;
BA_REL_ "GenSigTimeoutTime" BU_SG_REL_ L_ATCU_vMON SG_ 854 L_ATCU_Lib_ModSetSw 5000;
BA_ "Version" SG_ 854 L_ATCU_Lib_ModSetSw "23.11.10";
BA_ "GenMsgSendType" BO_ 855 0;
BA_ "GenMsgCycleTime" BO_ 855 500;
BA_ "Description" SG_ 855 L_ATCU_Lib_2ndAutoSw "This value only use for ATCU Library data monitoring (Only use before SOP)";
BA_ "GenSigSendType" SG_ 855 L_ATCU_Lib_2ndAutoSw 4;
BA_ "UserSigValidity" SG_ 855 L_ATCU_Lib_2ndAutoSw 0;
BA_REL_ "GenSigTimeoutTime" BU_SG_REL_ L_ATCU_vMON SG_ 855 L_ATCU_Lib_2ndAutoSw 5000;
BA_ "Version" SG_ 855 L_ATCU_Lib_2ndAutoSw "23.11.10";
BA_ "Description" SG_ 855 L_ATCU_Lib_2ndAutoUpSw "This value only use for ATCU Library data monitoring (Only use before SOP)";
BA_ "GenSigSendType" SG_ 855 L_ATCU_Lib_2ndAutoUpSw 4;
BA_ "UserSigValidity" SG_ 855 L_ATCU_Lib_2ndAutoUpSw 0;
BA_REL_ "GenSigTimeoutTime" BU_SG_REL_ L_ATCU_vMON SG_ 855 L_ATCU_Lib_2ndAutoUpSw 5000;
BA_ "Version" SG_ 855 L_ATCU_Lib_2ndAutoUpSw "23.11.10";
BA_ "Description" SG_ 855 L_ATCU_Lib_2LHTempUpSw "This value only use for ATCU Library data monitoring (Only use before SOP)";
BA_ "GenSigSendType" SG_ 855 L_ATCU_Lib_2LHTempUpSw 4;
BA_ "UserSigValidity" SG_ 855 L_ATCU_Lib_2LHTempUpSw 0;
BA_REL_ "GenSigTimeoutTime" BU_SG_REL_ L_ATCU_vMON SG_ 855 L_ATCU_Lib_2LHTempUpSw 5000;
BA_ "Version" SG_ 855 L_ATCU_Lib_2LHTempUpSw "23.11.10";
BA_ "Description" SG_ 855 L_ATCU_Lib_2LHTempDnSw "This value only use for ATCU Library data monitoring (Only use before SOP)";
BA_ "GenSigSendType" SG_ 855 L_ATCU_Lib_2LHTempDnSw 4;
BA_ "UserSigValidity" SG_ 855 L_ATCU_Lib_2LHTempDnSw 0;
BA_REL_ "GenSigTimeoutTime" BU_SG_REL_ L_ATCU_vMON SG_ 855 L_ATCU_Lib_2LHTempDnSw 5000;
BA_ "Version" SG_ 855 L_ATCU_Lib_2LHTempDnSw "23.11.10";
BA_ "Description" SG_ 855 L_ATCU_Lib_2RHTempUpSw "This value only use for ATCU Library data monitoring (Only use before SOP)";
BA_ "GenSigSendType" SG_ 855 L_ATCU_Lib_2RHTempUpSw 4;
BA_ "UserSigValidity" SG_ 855 L_ATCU_Lib_2RHTempUpSw 0;
BA_REL_ "GenSigTimeoutTime" BU_SG_REL_ L_ATCU_vMON SG_ 855 L_ATCU_Lib_2RHTempUpSw 5000;
BA_ "Version" SG_ 855 L_ATCU_Lib_2RHTempUpSw "23.11.10";
BA_ "Description" SG_ 855 L_ATCU_Lib_2RHTempDnSw "This value only use for ATCU Library data monitoring (Only use before SOP)";
BA_ "GenSigSendType" SG_ 855 L_ATCU_Lib_2RHTempDnSw 4;
BA_ "UserSigValidity" SG_ 855 L_ATCU_Lib_2RHTempDnSw 0;
BA_REL_ "GenSigTimeoutTime" BU_SG_REL_ L_ATCU_vMON SG_ 855 L_ATCU_Lib_2RHTempDnSw 5000;
BA_ "Version" SG_ 855 L_ATCU_Lib_2RHTempDnSw "23.11.10";
BA_ "Description" SG_ 855 L_ATCU_Lib_2ndSyncSw "This value only use for ATCU Library data monitoring (Only use before SOP)";
BA_ "GenSigSendType" SG_ 855 L_ATCU_Lib_2ndSyncSw 4;
BA_ "UserSigValidity" SG_ 855 L_ATCU_Lib_2ndSyncSw 0;
BA_REL_ "GenSigTimeoutTime" BU_SG_REL_ L_ATCU_vMON SG_ 855 L_ATCU_Lib_2ndSyncSw 5000;
BA_ "Version" SG_ 855 L_ATCU_Lib_2ndSyncSw "23.11.10";
BA_ "Description" SG_ 855 L_ATCU_Lib_2ndLockSw "This value only use for ATCU Library data monitoring (Only use before SOP)";
BA_ "GenSigSendType" SG_ 855 L_ATCU_Lib_2ndLockSw 4;
BA_ "UserSigValidity" SG_ 855 L_ATCU_Lib_2ndLockSw 0;
BA_REL_ "GenSigTimeoutTime" BU_SG_REL_ L_ATCU_vMON SG_ 855 L_ATCU_Lib_2ndLockSw 5000;
BA_ "Version" SG_ 855 L_ATCU_Lib_2ndLockSw "23.11.10";
BA_ "Description" SG_ 855 L_ATCU_Lib_2LHSeatHeatSw "This value only use for ATCU Library data monitoring (Only use before SOP)";
BA_ "GenSigSendType" SG_ 855 L_ATCU_Lib_2LHSeatHeatSw 4;
BA_ "UserSigValidity" SG_ 855 L_ATCU_Lib_2LHSeatHeatSw 0;
BA_REL_ "GenSigTimeoutTime" BU_SG_REL_ L_ATCU_vMON SG_ 855 L_ATCU_Lib_2LHSeatHeatSw 5000;
BA_ "Version" SG_ 855 L_ATCU_Lib_2LHSeatHeatSw "23.11.10";
BA_ "Description" SG_ 855 L_ATCU_Lib_2LHSeatVentSw "This value only use for ATCU Library data monitoring (Only use before SOP)";
BA_ "GenSigSendType" SG_ 855 L_ATCU_Lib_2LHSeatVentSw 4;
BA_ "UserSigValidity" SG_ 855 L_ATCU_Lib_2LHSeatVentSw 0;
BA_REL_ "GenSigTimeoutTime" BU_SG_REL_ L_ATCU_vMON SG_ 855 L_ATCU_Lib_2LHSeatVentSw 5000;
BA_ "Version" SG_ 855 L_ATCU_Lib_2LHSeatVentSw "23.11.10";
BA_ "Description" SG_ 855 L_ATCU_Lib_2RHSeatHeatSw "This value only use for ATCU Library data monitoring (Only use before SOP)";
BA_ "GenSigSendType" SG_ 855 L_ATCU_Lib_2RHSeatHeatSw 4;
BA_ "UserSigValidity" SG_ 855 L_ATCU_Lib_2RHSeatHeatSw 0;
BA_REL_ "GenSigTimeoutTime" BU_SG_REL_ L_ATCU_vMON SG_ 855 L_ATCU_Lib_2RHSeatHeatSw 5000;
BA_ "Version" SG_ 855 L_ATCU_Lib_2RHSeatHeatSw "23.11.10";
BA_ "Description" SG_ 855 L_ATCU_Lib_2RHSeatVentSw "This value only use for ATCU Library data monitoring (Only use before SOP)";
BA_ "GenSigSendType" SG_ 855 L_ATCU_Lib_2RHSeatVentSw 4;
BA_ "UserSigValidity" SG_ 855 L_ATCU_Lib_2RHSeatVentSw 0;
BA_REL_ "GenSigTimeoutTime" BU_SG_REL_ L_ATCU_vMON SG_ 855 L_ATCU_Lib_2RHSeatVentSw 5000;
BA_ "Version" SG_ 855 L_ATCU_Lib_2RHSeatVentSw "23.11.10";
BA_ "Description" SG_ 855 L_ATCU_Lib_2ndAutoDnSw "This value only use for ATCU Library data monitoring (Only use before SOP)";
BA_ "GenSigSendType" SG_ 855 L_ATCU_Lib_2ndAutoDnSw 4;
BA_ "UserSigValidity" SG_ 855 L_ATCU_Lib_2ndAutoDnSw 0;
BA_REL_ "GenSigTimeoutTime" BU_SG_REL_ L_ATCU_vMON SG_ 855 L_ATCU_Lib_2ndAutoDnSw 5000;
BA_ "Version" SG_ 855 L_ATCU_Lib_2ndAutoDnSw "23.11.10";
BA_ "Description" SG_ 855 L_ATCU_Lib_2LHSeatTumblerSw "This value only use for ATCU Library data monitoring (Only use before SOP)";
BA_ "GenSigSendType" SG_ 855 L_ATCU_Lib_2LHSeatTumblerSw 4;
BA_ "UserSigValidity" SG_ 855 L_ATCU_Lib_2LHSeatTumblerSw 0;
BA_REL_ "GenSigTimeoutTime" BU_SG_REL_ L_ATCU_vMON SG_ 855 L_ATCU_Lib_2LHSeatTumblerSw 5000;
BA_ "Version" SG_ 855 L_ATCU_Lib_2LHSeatTumblerSw "23.11.10";
BA_ "Description" SG_ 855 L_ATCU_Lib_2RHSeatTumblerSw "This value only use for ATCU Library data monitoring (Only use before SOP)";
BA_ "GenSigSendType" SG_ 855 L_ATCU_Lib_2RHSeatTumblerSw 4;
BA_ "UserSigValidity" SG_ 855 L_ATCU_Lib_2RHSeatTumblerSw 0;
BA_REL_ "GenSigTimeoutTime" BU_SG_REL_ L_ATCU_vMON SG_ 855 L_ATCU_Lib_2RHSeatTumblerSw 5000;
BA_ "Version" SG_ 855 L_ATCU_Lib_2RHSeatTumblerSw "23.11.10";
BA_ "Description" SG_ 855 L_ATCU_Lib_2ndOffSetSw "This value only use for ATCU Library data monitoring (Only use before SOP)";
BA_ "GenSigSendType" SG_ 855 L_ATCU_Lib_2ndOffSetSw 4;
BA_ "UserSigValidity" SG_ 855 L_ATCU_Lib_2ndOffSetSw 0;
BA_REL_ "GenSigTimeoutTime" BU_SG_REL_ L_ATCU_vMON SG_ 855 L_ATCU_Lib_2ndOffSetSw 5000;
BA_ "Version" SG_ 855 L_ATCU_Lib_2ndOffSetSw "23.11.10";
BA_ "Description" SG_ 855 L_ATCU_Lib_2ndAutoSetSw "This value only use for ATCU Library data monitoring (Only use before SOP)";
BA_ "GenSigSendType" SG_ 855 L_ATCU_Lib_2ndAutoSetSw 4;
BA_ "UserSigValidity" SG_ 855 L_ATCU_Lib_2ndAutoSetSw 0;
BA_REL_ "GenSigTimeoutTime" BU_SG_REL_ L_ATCU_vMON SG_ 855 L_ATCU_Lib_2ndAutoSetSw 5000;
BA_ "Version" SG_ 855 L_ATCU_Lib_2ndAutoSetSw "23.11.10";
BA_ "Description" SG_ 855 L_ATCU_Lib_2ndMultiAutoSetSw "This value only use for ATCU Library data monitoring (Only use before SOP)";
BA_ "GenSigSendType" SG_ 855 L_ATCU_Lib_2ndMultiAutoSetSw 4;
BA_ "UserSigValidity" SG_ 855 L_ATCU_Lib_2ndMultiAutoSetSw 0;
BA_REL_ "GenSigTimeoutTime" BU_SG_REL_ L_ATCU_vMON SG_ 855 L_ATCU_Lib_2ndMultiAutoSetSw 5000;
BA_ "Version" SG_ 855 L_ATCU_Lib_2ndMultiAutoSetSw "23.11.10";
BA_ "Description" SG_ 855 L_ATCU_Lib_2LHModSw "This value only use for ATCU Library data monitoring (Only use before SOP)";
BA_ "GenSigSendType" SG_ 855 L_ATCU_Lib_2LHModSw 4;
BA_ "UserSigValidity" SG_ 855 L_ATCU_Lib_2LHModSw 0;
BA_REL_ "GenSigTimeoutTime" BU_SG_REL_ L_ATCU_vMON SG_ 855 L_ATCU_Lib_2LHModSw 5000;
BA_ "Version" SG_ 855 L_ATCU_Lib_2LHModSw "23.11.10";
BA_ "Description" SG_ 855 L_ATCU_Lib_2ndACSetSw "This value only use for ATCU Library data monitoring (Only use before SOP)";
BA_ "GenSigSendType" SG_ 855 L_ATCU_Lib_2ndACSetSw 4;
BA_ "UserSigValidity" SG_ 855 L_ATCU_Lib_2ndACSetSw 0;
BA_REL_ "GenSigTimeoutTime" BU_SG_REL_ L_ATCU_vMON SG_ 855 L_ATCU_Lib_2ndACSetSw 5000;
BA_ "Version" SG_ 855 L_ATCU_Lib_2ndACSetSw "23.11.10";
BA_ "Description" SG_ 855 L_ATCU_Lib_2LHModSetSw "This value only use for ATCU Library data monitoring (Only use before SOP)";
BA_ "GenSigSendType" SG_ 855 L_ATCU_Lib_2LHModSetSw 4;
BA_ "UserSigValidity" SG_ 855 L_ATCU_Lib_2LHModSetSw 0;
BA_REL_ "GenSigTimeoutTime" BU_SG_REL_ L_ATCU_vMON SG_ 855 L_ATCU_Lib_2LHModSetSw 5000;
BA_ "Version" SG_ 855 L_ATCU_Lib_2LHModSetSw "23.11.10";
BA_ "Description" SG_ 855 L_ATCU_Lib_2LHBlrSetSw "This value only use for ATCU Library data monitoring (Only use before SOP)";
BA_ "GenSigSendType" SG_ 855 L_ATCU_Lib_2LHBlrSetSw 4;
BA_ "UserSigValidity" SG_ 855 L_ATCU_Lib_2LHBlrSetSw 0;
BA_REL_ "GenSigTimeoutTime" BU_SG_REL_ L_ATCU_vMON SG_ 855 L_ATCU_Lib_2LHBlrSetSw 5000;
BA_ "Version" SG_ 855 L_ATCU_Lib_2LHBlrSetSw "23.11.10";
BA_ "Description" SG_ 855 L_ATCU_Lib_2LHModUpSw "This value only use for ATCU Library data monitoring (Only use before SOP)";
BA_ "GenSigSendType" SG_ 855 L_ATCU_Lib_2LHModUpSw 4;
BA_ "UserSigValidity" SG_ 855 L_ATCU_Lib_2LHModUpSw 0;
BA_REL_ "GenSigTimeoutTime" BU_SG_REL_ L_ATCU_vMON SG_ 855 L_ATCU_Lib_2LHModUpSw 5000;
BA_ "Version" SG_ 855 L_ATCU_Lib_2LHModUpSw "23.11.10";
BA_ "Description" SG_ 855 L_ATCU_Lib_2LHTempSetSw "This value only use for ATCU Library data monitoring (Only use before SOP)";
BA_ "GenSigSendType" SG_ 855 L_ATCU_Lib_2LHTempSetSw 4;
BA_ "UserSigValidity" SG_ 855 L_ATCU_Lib_2LHTempSetSw 0;
BA_REL_ "GenSigTimeoutTime" BU_SG_REL_ L_ATCU_vMON SG_ 855 L_ATCU_Lib_2LHTempSetSw 5000;
BA_ "Version" SG_ 855 L_ATCU_Lib_2LHTempSetSw "25.11.02";
BA_ "Description" SG_ 855 L_ATCU_Lib_2RHTempSetSw "This value only use for ATCU Library data monitoring (Only use before SOP)";
BA_ "GenSigSendType" SG_ 855 L_ATCU_Lib_2RHTempSetSw 4;
BA_ "UserSigValidity" SG_ 855 L_ATCU_Lib_2RHTempSetSw 0;
BA_REL_ "GenSigTimeoutTime" BU_SG_REL_ L_ATCU_vMON SG_ 855 L_ATCU_Lib_2RHTempSetSw 5000;
BA_ "Version" SG_ 855 L_ATCU_Lib_2RHTempSetSw "25.11.02";
BA_ "Description" SG_ 855 L_ATCU_Lib_2LHModDnSw "This value only use for ATCU Library data monitoring (Only use before SOP)";
BA_ "GenSigSendType" SG_ 855 L_ATCU_Lib_2LHModDnSw 4;
BA_ "UserSigValidity" SG_ 855 L_ATCU_Lib_2LHModDnSw 0;
BA_REL_ "GenSigTimeoutTime" BU_SG_REL_ L_ATCU_vMON SG_ 855 L_ATCU_Lib_2LHModDnSw 5000;
BA_ "Version" SG_ 855 L_ATCU_Lib_2LHModDnSw "23.11.10";
BA_ "Description" SG_ 855 L_ATCU_Lib_DrvBlrClickCnt "This value only use for ATCU Library data monitoring (Only use before SOP)";
BA_ "GenSigSendType" SG_ 855 L_ATCU_Lib_DrvBlrClickCnt 4;
BA_ "GenSigStartValue" SG_ 855 L_ATCU_Lib_DrvBlrClickCnt 255;
BA_ "UserSigValidity" SG_ 855 L_ATCU_Lib_DrvBlrClickCnt 0;
BA_REL_ "GenSigTimeoutTime" BU_SG_REL_ L_ATCU_vMON SG_ 855 L_ATCU_Lib_DrvBlrClickCnt 5000;
BA_ "Version" SG_ 855 L_ATCU_Lib_DrvBlrClickCnt "24.05.08";
BA_ "Description" SG_ 855 L_ATCU_Lib_2LHBlrUpSw "This value only use for ATCU Library data monitoring (Only use before SOP)";
BA_ "GenSigSendType" SG_ 855 L_ATCU_Lib_2LHBlrUpSw 4;
BA_ "UserSigValidity" SG_ 855 L_ATCU_Lib_2LHBlrUpSw 0;
BA_REL_ "GenSigTimeoutTime" BU_SG_REL_ L_ATCU_vMON SG_ 855 L_ATCU_Lib_2LHBlrUpSw 5000;
BA_ "Version" SG_ 855 L_ATCU_Lib_2LHBlrUpSw "23.11.10";
BA_ "Description" SG_ 855 L_ATCU_Lib_2LHBlrDnSw "This value only use for ATCU Library data monitoring (Only use before SOP)";
BA_ "GenSigSendType" SG_ 855 L_ATCU_Lib_2LHBlrDnSw 4;
BA_ "UserSigValidity" SG_ 855 L_ATCU_Lib_2LHBlrDnSw 0;
BA_REL_ "GenSigTimeoutTime" BU_SG_REL_ L_ATCU_vMON SG_ 855 L_ATCU_Lib_2LHBlrDnSw 5000;
BA_ "Version" SG_ 855 L_ATCU_Lib_2LHBlrDnSw "23.11.10";
BA_ "Description" SG_ 855 L_ATCU_Lib_2LHBlrDnOffReq "This value only use for ATCU Library data monitoring (Only use before SOP)";
BA_ "GenSigSendType" SG_ 855 L_ATCU_Lib_2LHBlrDnOffReq 4;
BA_ "UserSigValidity" SG_ 855 L_ATCU_Lib_2LHBlrDnOffReq 0;
BA_REL_ "GenSigTimeoutTime" BU_SG_REL_ L_ATCU_vMON SG_ 855 L_ATCU_Lib_2LHBlrDnOffReq 5000;
BA_ "Version" SG_ 855 L_ATCU_Lib_2LHBlrDnOffReq "23.11.10";
BA_ "Description" SG_ 855 L_ATCU_Lib_2ndACSw "This value only use for ATCU Library data monitoring (Only use before SOP)";
BA_ "GenSigSendType" SG_ 855 L_ATCU_Lib_2ndACSw 4;
BA_ "UserSigValidity" SG_ 855 L_ATCU_Lib_2ndACSw 0;
BA_REL_ "GenSigTimeoutTime" BU_SG_REL_ L_ATCU_vMON SG_ 855 L_ATCU_Lib_2ndACSw 5000;
BA_ "Version" SG_ 855 L_ATCU_Lib_2ndACSw "23.11.10";
BA_ "GenMsgSendType" BO_ 856 0;
BA_ "GenMsgCycleTime" BO_ 856 500;
BA_ "Description" SG_ 856 L_ATCU_Lib_AutoStepInd "This value only use for ATCU Library data monitoring (Only use before SOP)";
BA_ "GenSigSendType" SG_ 856 L_ATCU_Lib_AutoStepInd 4;
BA_ "UserSigValidity" SG_ 856 L_ATCU_Lib_AutoStepInd 0;
BA_REL_ "GenSigTimeoutTime" BU_SG_REL_ L_ATCU_vMON SG_ 856 L_ATCU_Lib_AutoStepInd 5000;
BA_ "Version" SG_ 856 L_ATCU_Lib_AutoStepInd "23.11.10";
BA_ "Description" SG_ 856 L_ATCU_Lib_BlrSym "This value only use for ATCU Library data monitoring (Only use before SOP)";
BA_ "GenSigSendType" SG_ 856 L_ATCU_Lib_BlrSym 4;
BA_ "UserSigValidity" SG_ 856 L_ATCU_Lib_BlrSym 0;
BA_REL_ "GenSigTimeoutTime" BU_SG_REL_ L_ATCU_vMON SG_ 856 L_ATCU_Lib_BlrSym 5000;
BA_ "Version" SG_ 856 L_ATCU_Lib_BlrSym "23.11.10";
BA_ "Description" SG_ 856 L_ATCU_Lib_BlrStepSym "This value only use for ATCU Library data monitoring (Only use before SOP)";
BA_ "GenSigSendType" SG_ 856 L_ATCU_Lib_BlrStepSym 4;
BA_ "UserSigValidity" SG_ 856 L_ATCU_Lib_BlrStepSym 0;
BA_REL_ "GenSigTimeoutTime" BU_SG_REL_ L_ATCU_vMON SG_ 856 L_ATCU_Lib_BlrStepSym 5000;
BA_ "Version" SG_ 856 L_ATCU_Lib_BlrStepSym "23.11.10";
BA_ "Description" SG_ 856 L_ATCU_Lib_IntakeRECInd "This value only use for ATCU Library data monitoring (Only use before SOP)";
BA_ "GenSigSendType" SG_ 856 L_ATCU_Lib_IntakeRECInd 4;
BA_ "UserSigValidity" SG_ 856 L_ATCU_Lib_IntakeRECInd 0;
BA_REL_ "GenSigTimeoutTime" BU_SG_REL_ L_ATCU_vMON SG_ 856 L_ATCU_Lib_IntakeRECInd 5000;
BA_ "Version" SG_ 856 L_ATCU_Lib_IntakeRECInd "23.11.10";
BA_ "Description" SG_ 856 L_ATCU_Lib_IntakeFREInd "This value only use for ATCU Library data monitoring (Only use before SOP)";
BA_ "GenSigSendType" SG_ 856 L_ATCU_Lib_IntakeFREInd 4;
BA_ "UserSigValidity" SG_ 856 L_ATCU_Lib_IntakeFREInd 0;
BA_REL_ "GenSigTimeoutTime" BU_SG_REL_ L_ATCU_vMON SG_ 856 L_ATCU_Lib_IntakeFREInd 5000;
BA_ "Version" SG_ 856 L_ATCU_Lib_IntakeFREInd "23.11.10";
BA_ "Description" SG_ 856 L_ATCU_Lib_ACInd "This value only use for ATCU Library data monitoring (Only use before SOP)";
BA_ "GenSigSendType" SG_ 856 L_ATCU_Lib_ACInd 4;
BA_ "UserSigValidity" SG_ 856 L_ATCU_Lib_ACInd 0;
BA_REL_ "GenSigTimeoutTime" BU_SG_REL_ L_ATCU_vMON SG_ 856 L_ATCU_Lib_ACInd 5000;
BA_ "Version" SG_ 856 L_ATCU_Lib_ACInd "23.11.10";
BA_ "Description" SG_ 856 L_ATCU_Lib_DEFInd "This value only use for ATCU Library data monitoring (Only use before SOP)";
BA_ "GenSigSendType" SG_ 856 L_ATCU_Lib_DEFInd 4;
BA_ "UserSigValidity" SG_ 856 L_ATCU_Lib_DEFInd 0;
BA_REL_ "GenSigTimeoutTime" BU_SG_REL_ L_ATCU_vMON SG_ 856 L_ATCU_Lib_DEFInd 5000;
BA_ "Version" SG_ 856 L_ATCU_Lib_DEFInd "23.11.10";
BA_ "Description" SG_ 856 L_ATCU_Lib_SyncInd "This value only use for ATCU Library data monitoring (Only use before SOP)";
BA_ "GenSigSendType" SG_ 856 L_ATCU_Lib_SyncInd 4;
BA_ "UserSigValidity" SG_ 856 L_ATCU_Lib_SyncInd 0;
BA_REL_ "GenSigTimeoutTime" BU_SG_REL_ L_ATCU_vMON SG_ 856 L_ATCU_Lib_SyncInd 5000;
BA_ "Version" SG_ 856 L_ATCU_Lib_SyncInd "23.11.10";
BA_ "Description" SG_ 856 L_ATCU_Lib_AutoBlrStepSym "This value only use for ATCU Library data monitoring (Only use before SOP)";
BA_ "GenSigSendType" SG_ 856 L_ATCU_Lib_AutoBlrStepSym 4;
BA_ "UserSigValidity" SG_ 856 L_ATCU_Lib_AutoBlrStepSym 0;
BA_REL_ "GenSigTimeoutTime" BU_SG_REL_ L_ATCU_vMON SG_ 856 L_ATCU_Lib_AutoBlrStepSym 5000;
BA_ "Version" SG_ 856 L_ATCU_Lib_AutoBlrStepSym "23.11.10";
BA_ "Description" SG_ 856 L_ATCU_Lib_DrvOnly "This value only use for ATCU Library data monitoring (Only use before SOP)";
BA_ "GenSigSendType" SG_ 856 L_ATCU_Lib_DrvOnly 4;
BA_ "UserSigValidity" SG_ 856 L_ATCU_Lib_DrvOnly 0;
BA_REL_ "GenSigTimeoutTime" BU_SG_REL_ L_ATCU_vMON SG_ 856 L_ATCU_Lib_DrvOnly 5000;
BA_ "Version" SG_ 856 L_ATCU_Lib_DrvOnly "23.11.10";
BA_ "Description" SG_ 856 L_ATCU_Lib_ADSSym "This value only use for ATCU Library data monitoring (Only use before SOP)";
BA_ "GenSigSendType" SG_ 856 L_ATCU_Lib_ADSSym 4;
BA_ "UserSigValidity" SG_ 856 L_ATCU_Lib_ADSSym 0;
BA_REL_ "GenSigTimeoutTime" BU_SG_REL_ L_ATCU_vMON SG_ 856 L_ATCU_Lib_ADSSym 5000;
BA_ "Version" SG_ 856 L_ATCU_Lib_ADSSym "23.11.10";
BA_ "Description" SG_ 856 L_ATCU_Lib_ModVentInd "This value only use for ATCU Library data monitoring (Only use before SOP)";
BA_ "GenSigSendType" SG_ 856 L_ATCU_Lib_ModVentInd 4;
BA_ "UserSigValidity" SG_ 856 L_ATCU_Lib_ModVentInd 0;
BA_REL_ "GenSigTimeoutTime" BU_SG_REL_ L_ATCU_vMON SG_ 856 L_ATCU_Lib_ModVentInd 5000;
BA_ "Version" SG_ 856 L_ATCU_Lib_ModVentInd "23.11.10";
BA_ "Description" SG_ 856 L_ATCU_Lib_DrvTempSym "This value only use for ATCU Library data monitoring (Only use before SOP)";
BA_ "GenSigSendType" SG_ 856 L_ATCU_Lib_DrvTempSym 4;
BA_ "UserSigValidity" SG_ 856 L_ATCU_Lib_DrvTempSym 0;
BA_REL_ "GenSigTimeoutTime" BU_SG_REL_ L_ATCU_vMON SG_ 856 L_ATCU_Lib_DrvTempSym 5000;
BA_ "Version" SG_ 856 L_ATCU_Lib_DrvTempSym "23.11.10";
BA_ "Description" SG_ 856 L_ATCU_Lib_ModSym "This value only use for ATCU Library data monitoring (Only use before SOP)";
BA_ "GenSigSendType" SG_ 856 L_ATCU_Lib_ModSym 4;
BA_ "UserSigValidity" SG_ 856 L_ATCU_Lib_ModSym 0;
BA_REL_ "GenSigTimeoutTime" BU_SG_REL_ L_ATCU_vMON SG_ 856 L_ATCU_Lib_ModSym 5000;
BA_ "Version" SG_ 856 L_ATCU_Lib_ModSym "23.11.10";
BA_ "Description" SG_ 856 L_ATCU_Lib_AstTempSym "This value only use for ATCU Library data monitoring (Only use before SOP)";
BA_ "GenSigSendType" SG_ 856 L_ATCU_Lib_AstTempSym 4;
BA_ "UserSigValidity" SG_ 856 L_ATCU_Lib_AstTempSym 0;
BA_REL_ "GenSigTimeoutTime" BU_SG_REL_ L_ATCU_vMON SG_ 856 L_ATCU_Lib_AstTempSym 5000;
BA_ "Version" SG_ 856 L_ATCU_Lib_AstTempSym "23.11.10";
BA_ "Description" SG_ 856 L_ATCU_Lib_DrvTempUnitSym "This value only use for ATCU Library data monitoring (Only use before SOP)";
BA_ "GenSigSendType" SG_ 856 L_ATCU_Lib_DrvTempUnitSym 4;
BA_ "UserSigValidity" SG_ 856 L_ATCU_Lib_DrvTempUnitSym 0;
BA_REL_ "GenSigTimeoutTime" BU_SG_REL_ L_ATCU_vMON SG_ 856 L_ATCU_Lib_DrvTempUnitSym 5000;
BA_ "Version" SG_ 856 L_ATCU_Lib_DrvTempUnitSym "23.11.10";
BA_ "Description" SG_ 856 L_ATCU_Lib_ModFloorInd "This value only use for ATCU Library data monitoring (Only use before SOP)";
BA_ "GenSigSendType" SG_ 856 L_ATCU_Lib_ModFloorInd 4;
BA_ "UserSigValidity" SG_ 856 L_ATCU_Lib_ModFloorInd 0;
BA_REL_ "GenSigTimeoutTime" BU_SG_REL_ L_ATCU_vMON SG_ 856 L_ATCU_Lib_ModFloorInd 5000;
BA_ "Version" SG_ 856 L_ATCU_Lib_ModFloorInd "23.11.10";
BA_ "Description" SG_ 856 L_ATCU_Lib_ModDEFInd "This value only use for ATCU Library data monitoring (Only use before SOP)";
BA_ "GenSigSendType" SG_ 856 L_ATCU_Lib_ModDEFInd 4;
BA_ "UserSigValidity" SG_ 856 L_ATCU_Lib_ModDEFInd 0;
BA_REL_ "GenSigTimeoutTime" BU_SG_REL_ L_ATCU_vMON SG_ 856 L_ATCU_Lib_ModDEFInd 5000;
BA_ "Version" SG_ 856 L_ATCU_Lib_ModDEFInd "23.11.10";
BA_ "GenMsgSendType" BO_ 857 0;
BA_ "GenMsgCycleTime" BO_ 857 500;
BA_ "Description" SG_ 857 L_ATCU_Lib_2LHAutoStepInd "This value only use for ATCU Library data monitoring (Only use before SOP)";
BA_ "GenSigSendType" SG_ 857 L_ATCU_Lib_2LHAutoStepInd 4;
BA_ "UserSigValidity" SG_ 857 L_ATCU_Lib_2LHAutoStepInd 0;
BA_REL_ "GenSigTimeoutTime" BU_SG_REL_ L_ATCU_vMON SG_ 857 L_ATCU_Lib_2LHAutoStepInd 5000;
BA_ "Version" SG_ 857 L_ATCU_Lib_2LHAutoStepInd "23.11.10";
BA_ "Description" SG_ 857 L_ATCU_Lib_2ndACInd "This value only use for ATCU Library data monitoring (Only use before SOP)";
BA_ "GenSigSendType" SG_ 857 L_ATCU_Lib_2ndACInd 4;
BA_ "UserSigValidity" SG_ 857 L_ATCU_Lib_2ndACInd 0;
BA_REL_ "GenSigTimeoutTime" BU_SG_REL_ L_ATCU_vMON SG_ 857 L_ATCU_Lib_2ndACInd 5000;
BA_ "Version" SG_ 857 L_ATCU_Lib_2ndACInd "23.11.10";
BA_ "Description" SG_ 857 L_ATCU_Lib_2ndSyncInd "This value only use for ATCU Library data monitoring (Only use before SOP)";
BA_ "GenSigSendType" SG_ 857 L_ATCU_Lib_2ndSyncInd 4;
BA_ "UserSigValidity" SG_ 857 L_ATCU_Lib_2ndSyncInd 0;
BA_REL_ "GenSigTimeoutTime" BU_SG_REL_ L_ATCU_vMON SG_ 857 L_ATCU_Lib_2ndSyncInd 5000;
BA_ "Version" SG_ 857 L_ATCU_Lib_2ndSyncInd "23.11.10";
BA_ "Description" SG_ 857 L_ATCU_Lib_2ndLockInd "This value only use for ATCU Library data monitoring (Only use before SOP)";
BA_ "GenSigSendType" SG_ 857 L_ATCU_Lib_2ndLockInd 4;
BA_ "UserSigValidity" SG_ 857 L_ATCU_Lib_2ndLockInd 0;
BA_REL_ "GenSigTimeoutTime" BU_SG_REL_ L_ATCU_vMON SG_ 857 L_ATCU_Lib_2ndLockInd 5000;
BA_ "Version" SG_ 857 L_ATCU_Lib_2ndLockInd "23.11.10";
BA_ "Description" SG_ 857 L_ATCU_Lib_2LHBlrSym "This value only use for ATCU Library data monitoring (Only use before SOP)";
BA_ "GenSigSendType" SG_ 857 L_ATCU_Lib_2LHBlrSym 4;
BA_ "UserSigValidity" SG_ 857 L_ATCU_Lib_2LHBlrSym 0;
BA_REL_ "GenSigTimeoutTime" BU_SG_REL_ L_ATCU_vMON SG_ 857 L_ATCU_Lib_2LHBlrSym 5000;
BA_ "Version" SG_ 857 L_ATCU_Lib_2LHBlrSym "23.11.10";
BA_ "Description" SG_ 857 L_ATCU_Lib_2LHTempSym "This value only use for ATCU Library data monitoring (Only use before SOP)";
BA_ "GenSigSendType" SG_ 857 L_ATCU_Lib_2LHTempSym 4;
BA_ "UserSigValidity" SG_ 857 L_ATCU_Lib_2LHTempSym 0;
BA_REL_ "GenSigTimeoutTime" BU_SG_REL_ L_ATCU_vMON SG_ 857 L_ATCU_Lib_2LHTempSym 5000;
BA_ "Version" SG_ 857 L_ATCU_Lib_2LHTempSym "23.11.10";
BA_ "Description" SG_ 857 L_ATCU_Lib_2LHAutoBlrStepSym "This value only use for ATCU Library data monitoring (Only use before SOP)";
BA_ "GenSigSendType" SG_ 857 L_ATCU_Lib_2LHAutoBlrStepSym 4;
BA_ "UserSigValidity" SG_ 857 L_ATCU_Lib_2LHAutoBlrStepSym 0;
BA_REL_ "GenSigTimeoutTime" BU_SG_REL_ L_ATCU_vMON SG_ 857 L_ATCU_Lib_2LHAutoBlrStepSym 5000;
BA_ "Version" SG_ 857 L_ATCU_Lib_2LHAutoBlrStepSym "23.11.10";
BA_ "Description" SG_ 857 L_ATCU_Lib_2LHTempUnit "This value only use for ATCU Library data monitoring (Only use before SOP)";
BA_ "GenSigSendType" SG_ 857 L_ATCU_Lib_2LHTempUnit 4;
BA_ "UserSigValidity" SG_ 857 L_ATCU_Lib_2LHTempUnit 0;
BA_REL_ "GenSigTimeoutTime" BU_SG_REL_ L_ATCU_vMON SG_ 857 L_ATCU_Lib_2LHTempUnit 5000;
BA_ "Version" SG_ 857 L_ATCU_Lib_2LHTempUnit "23.11.10";
BA_ "Description" SG_ 857 L_ATCU_Lib_2LHModSym "This value only use for ATCU Library data monitoring (Only use before SOP)";
BA_ "GenSigSendType" SG_ 857 L_ATCU_Lib_2LHModSym 4;
BA_ "UserSigValidity" SG_ 857 L_ATCU_Lib_2LHModSym 0;
BA_REL_ "GenSigTimeoutTime" BU_SG_REL_ L_ATCU_vMON SG_ 857 L_ATCU_Lib_2LHModSym 5000;
BA_ "Version" SG_ 857 L_ATCU_Lib_2LHModSym "23.11.10";
BA_ "Description" SG_ 857 L_ATCU_Lib_FineDustTreeSym "This value only use for ATCU Library data monitoring (Only use before SOP)";
BA_ "GenSigSendType" SG_ 857 L_ATCU_Lib_FineDustTreeSym 4;
BA_ "UserSigValidity" SG_ 857 L_ATCU_Lib_FineDustTreeSym 0;
BA_REL_ "GenSigTimeoutTime" BU_SG_REL_ L_ATCU_vMON SG_ 857 L_ATCU_Lib_FineDustTreeSym 5000;
BA_ "Version" SG_ 857 L_ATCU_Lib_FineDustTreeSym "24.01.09";
BA_ "Description" SG_ 857 L_ATCU_Lib_FineDustTreeColor "This value only use for ATCU Library data monitoring (Only use before SOP)";
BA_ "GenSigSendType" SG_ 857 L_ATCU_Lib_FineDustTreeColor 4;
BA_ "UserSigValidity" SG_ 857 L_ATCU_Lib_FineDustTreeColor 0;
BA_REL_ "GenSigTimeoutTime" BU_SG_REL_ L_ATCU_vMON SG_ 857 L_ATCU_Lib_FineDustTreeColor 5000;
BA_ "Version" SG_ 857 L_ATCU_Lib_FineDustTreeColor "24.01.09";
BA_ "Description" SG_ 857 L_ATCU_Lib_FineDustBarStepSym "This value only use for ATCU Library data monitoring (Only use before SOP)";
BA_ "GenSigSendType" SG_ 857 L_ATCU_Lib_FineDustBarStepSym 4;
BA_ "UserSigValidity" SG_ 857 L_ATCU_Lib_FineDustBarStepSym 0;
BA_REL_ "GenSigTimeoutTime" BU_SG_REL_ L_ATCU_vMON SG_ 857 L_ATCU_Lib_FineDustBarStepSym 5000;
BA_ "Version" SG_ 857 L_ATCU_Lib_FineDustBarStepSym "24.01.08";
BA_ "Description" SG_ 857 L_ATCU_Lib_2RHTempSym "This value only use for ATCU Library data monitoring (Only use before SOP)";
BA_ "GenSigSendType" SG_ 857 L_ATCU_Lib_2RHTempSym 4;
BA_ "UserSigValidity" SG_ 857 L_ATCU_Lib_2RHTempSym 0;
BA_REL_ "GenSigTimeoutTime" BU_SG_REL_ L_ATCU_vMON SG_ 857 L_ATCU_Lib_2RHTempSym 5000;
BA_ "Version" SG_ 857 L_ATCU_Lib_2RHTempSym "25.11.02";
BA_ "Description" SG_ 857 L_ATCU_Lib_2LHBlrStepSym "This value only use for ATCU Library data monitoring (Only use before SOP)";
BA_ "GenSigSendType" SG_ 857 L_ATCU_Lib_2LHBlrStepSym 4;
BA_ "UserSigValidity" SG_ 857 L_ATCU_Lib_2LHBlrStepSym 0;
BA_REL_ "GenSigTimeoutTime" BU_SG_REL_ L_ATCU_vMON SG_ 857 L_ATCU_Lib_2LHBlrStepSym 5000;
BA_ "Version" SG_ 857 L_ATCU_Lib_2LHBlrStepSym "23.11.10";
BA_ "GenMsgSendType" BO_ 858 0;
BA_ "GenMsgCycleTime" BO_ 858 500;
BA_ "Description" SG_ 858 L_ATCU_Lib_USMDEFState "This value only use for ATCU Library data monitoring (Only use before SOP)";
BA_ "GenSigSendType" SG_ 858 L_ATCU_Lib_USMDEFState 4;
BA_ "UserSigValidity" SG_ 858 L_ATCU_Lib_USMDEFState 0;
BA_REL_ "GenSigTimeoutTime" BU_SG_REL_ L_ATCU_vMON SG_ 858 L_ATCU_Lib_USMDEFState 5000;
BA_ "Version" SG_ 858 L_ATCU_Lib_USMDEFState "24.09.00";
BA_ "Description" SG_ 858 L_ATCU_Lib_USMSmrtVentState "This value only use for ATCU Library data monitoring (Only use before SOP)";
BA_ "GenSigSendType" SG_ 858 L_ATCU_Lib_USMSmrtVentState 4;
BA_ "UserSigValidity" SG_ 858 L_ATCU_Lib_USMSmrtVentState 0;
BA_REL_ "GenSigTimeoutTime" BU_SG_REL_ L_ATCU_vMON SG_ 858 L_ATCU_Lib_USMSmrtVentState 5000;
BA_ "Version" SG_ 858 L_ATCU_Lib_USMSmrtVentState "23.11.10";
BA_ "Description" SG_ 858 L_ATCU_Lib_USMCoolHeatSeat "This value only use for ATCU Library data monitoring (Only use before SOP)";
BA_ "GenSigSendType" SG_ 858 L_ATCU_Lib_USMCoolHeatSeat 4;
BA_ "UserSigValidity" SG_ 858 L_ATCU_Lib_USMCoolHeatSeat 0;
BA_REL_ "GenSigTimeoutTime" BU_SG_REL_ L_ATCU_vMON SG_ 858 L_ATCU_Lib_USMCoolHeatSeat 5000;
BA_ "Version" SG_ 858 L_ATCU_Lib_USMCoolHeatSeat "23.11.10";
BA_ "Description" SG_ 858 L_ATCU_Lib_USMStrWhlHeater "This value only use for ATCU Library data monitoring (Only use before SOP)";
BA_ "GenSigSendType" SG_ 858 L_ATCU_Lib_USMStrWhlHeater 4;
BA_ "UserSigValidity" SG_ 858 L_ATCU_Lib_USMStrWhlHeater 0;
BA_REL_ "GenSigTimeoutTime" BU_SG_REL_ L_ATCU_vMON SG_ 858 L_ATCU_Lib_USMStrWhlHeater 5000;
BA_ "Version" SG_ 858 L_ATCU_Lib_USMStrWhlHeater "23.11.10";
BA_ "Description" SG_ 858 L_ATCU_Lib_USMUsrPrfleState "This value only use for ATCU Library data monitoring (Only use before SOP)";
BA_ "GenSigSendType" SG_ 858 L_ATCU_Lib_USMUsrPrfleState 4;
BA_ "UserSigValidity" SG_ 858 L_ATCU_Lib_USMUsrPrfleState 0;
BA_REL_ "GenSigTimeoutTime" BU_SG_REL_ L_ATCU_vMON SG_ 858 L_ATCU_Lib_USMUsrPrfleState 5000;
BA_ "Version" SG_ 858 L_ATCU_Lib_USMUsrPrfleState "23.11.10";
BA_ "Description" SG_ 858 L_ATCU_Lib_USMAutoFreshState "This value only use for ATCU Library data monitoring (Only use before SOP)";
BA_ "GenSigSendType" SG_ 858 L_ATCU_Lib_USMAutoFreshState 4;
BA_ "UserSigValidity" SG_ 858 L_ATCU_Lib_USMAutoFreshState 0;
BA_REL_ "GenSigTimeoutTime" BU_SG_REL_ L_ATCU_vMON SG_ 858 L_ATCU_Lib_USMAutoFreshState 5000;
BA_ "Version" SG_ 858 L_ATCU_Lib_USMAutoFreshState "24.09.00";
BA_ "Description" SG_ 858 L_ATCU_Lib_USM2ndAutoOffState "This value only use for ATCU Library data monitoring (Only use before SOP)";
BA_ "GenSigSendType" SG_ 858 L_ATCU_Lib_USM2ndAutoOffState 4;
BA_ "UserSigValidity" SG_ 858 L_ATCU_Lib_USM2ndAutoOffState 0;
BA_REL_ "GenSigTimeoutTime" BU_SG_REL_ L_ATCU_vMON SG_ 858 L_ATCU_Lib_USM2ndAutoOffState 5000;
BA_ "Version" SG_ 858 L_ATCU_Lib_USM2ndAutoOffState "23.11.10";
BA_ "Description" SG_ 858 L_ATCU_Lib_USMRearLock "This value only use for ATCU Library data monitoring (Only use before SOP)";
BA_ "GenSigSendType" SG_ 858 L_ATCU_Lib_USMRearLock 4;
BA_ "UserSigValidity" SG_ 858 L_ATCU_Lib_USMRearLock 0;
BA_REL_ "GenSigTimeoutTime" BU_SG_REL_ L_ATCU_vMON SG_ 858 L_ATCU_Lib_USMRearLock 5000;
BA_ "Version" SG_ 858 L_ATCU_Lib_USMRearLock "23.11.10";
BA_ "Description" SG_ 858 L_ATCU_Lib_USMWshState "This value only use for ATCU Library data monitoring (Only use before SOP)";
BA_ "GenSigSendType" SG_ 858 L_ATCU_Lib_USMWshState 4;
BA_ "UserSigValidity" SG_ 858 L_ATCU_Lib_USMWshState 0;
BA_REL_ "GenSigTimeoutTime" BU_SG_REL_ L_ATCU_vMON SG_ 858 L_ATCU_Lib_USMWshState 5000;
BA_ "Version" SG_ 858 L_ATCU_Lib_USMWshState "24.09.00";
BA_ "Description" SG_ 858 L_ATCU_Lib_USMADSState "This value only use for ATCU Library data monitoring (Only use before SOP)";
BA_ "GenSigSendType" SG_ 858 L_ATCU_Lib_USMADSState 4;
BA_ "UserSigValidity" SG_ 858 L_ATCU_Lib_USMADSState 0;
BA_REL_ "GenSigTimeoutTime" BU_SG_REL_ L_ATCU_vMON SG_ 858 L_ATCU_Lib_USMADSState 5000;
BA_ "Version" SG_ 858 L_ATCU_Lib_USMADSState "24.09.00";
BA_ "Description" SG_ 858 L_ATCU_Lib_USMTempUnitState "This value only use for ATCU Library data monitoring (Only use before SOP)";
BA_ "GenSigSendType" SG_ 858 L_ATCU_Lib_USMTempUnitState 4;
BA_ "UserSigValidity" SG_ 858 L_ATCU_Lib_USMTempUnitState 0;
BA_REL_ "GenSigTimeoutTime" BU_SG_REL_ L_ATCU_vMON SG_ 858 L_ATCU_Lib_USMTempUnitState 5000;
BA_ "Version" SG_ 858 L_ATCU_Lib_USMTempUnitState "23.11.10";
BA_ "Description" SG_ 858 L_ATCU_Lib_USMAfterBlowState "This value only use for ATCU Library data monitoring (Only use before SOP)";
BA_ "GenSigSendType" SG_ 858 L_ATCU_Lib_USMAfterBlowState 4;
BA_ "UserSigValidity" SG_ 858 L_ATCU_Lib_USMAfterBlowState 0;
BA_REL_ "GenSigTimeoutTime" BU_SG_REL_ L_ATCU_vMON SG_ 858 L_ATCU_Lib_USMAfterBlowState 5000;
BA_ "Version" SG_ 858 L_ATCU_Lib_USMAfterBlowState "23.11.10";
BA_ "Description" SG_ 858 L_ATCU_Lib_USMSchdldVent "This value only use for ATCU Library data monitoring (Only use before SOP)";
BA_ "GenSigSendType" SG_ 858 L_ATCU_Lib_USMSchdldVent 4;
BA_ "UserSigValidity" SG_ 858 L_ATCU_Lib_USMSchdldVent 0;
BA_REL_ "GenSigTimeoutTime" BU_SG_REL_ L_ATCU_vMON SG_ 858 L_ATCU_Lib_USMSchdldVent 5000;
BA_ "Version" SG_ 858 L_ATCU_Lib_USMSchdldVent "23.11.10";
BA_ "GenMsgSendType" BO_ 859 0;
BA_ "GenMsgCycleTime" BO_ 859 500;
BA_ "Description" SG_ 859 L_ATCU_Lib_Opt2LHModSwTyp "This value only use for ATCU Library data monitoring (Only use before SOP)";
BA_ "GenSigSendType" SG_ 859 L_ATCU_Lib_Opt2LHModSwTyp 4;
BA_ "UserSigValidity" SG_ 859 L_ATCU_Lib_Opt2LHModSwTyp 0;
BA_REL_ "GenSigTimeoutTime" BU_SG_REL_ L_ATCU_vMON SG_ 859 L_ATCU_Lib_Opt2LHModSwTyp 5000;
BA_ "Version" SG_ 859 L_ATCU_Lib_Opt2LHModSwTyp "23.11.10";
BA_ "Description" SG_ 859 L_ATCU_Lib_Opt2ndModBtn "This value only use for ATCU Library data monitoring (Only use before SOP)";
BA_ "GenSigSendType" SG_ 859 L_ATCU_Lib_Opt2ndModBtn 4;
BA_ "UserSigValidity" SG_ 859 L_ATCU_Lib_Opt2ndModBtn 0;
BA_REL_ "GenSigTimeoutTime" BU_SG_REL_ L_ATCU_vMON SG_ 859 L_ATCU_Lib_Opt2ndModBtn 5000;
BA_ "Version" SG_ 859 L_ATCU_Lib_Opt2ndModBtn "23.11.10";
BA_ "Description" SG_ 859 L_ATCU_Lib_Opt2ndOffSwTyp "This value only use for ATCU Library data monitoring (Only use before SOP)";
BA_ "GenSigSendType" SG_ 859 L_ATCU_Lib_Opt2ndOffSwTyp 4;
BA_ "UserSigValidity" SG_ 859 L_ATCU_Lib_Opt2ndOffSwTyp 0;
BA_REL_ "GenSigTimeoutTime" BU_SG_REL_ L_ATCU_vMON SG_ 859 L_ATCU_Lib_Opt2ndOffSwTyp 5000;
BA_ "Version" SG_ 859 L_ATCU_Lib_Opt2ndOffSwTyp "23.11.10";
BA_ "Description" SG_ 859 L_ATCU_Lib_Opt2ndTmpBtn "This value only use for ATCU Library data monitoring (Only use before SOP)";
BA_ "GenSigSendType" SG_ 859 L_ATCU_Lib_Opt2ndTmpBtn 4;
BA_ "UserSigValidity" SG_ 859 L_ATCU_Lib_Opt2ndTmpBtn 0;
BA_REL_ "GenSigTimeoutTime" BU_SG_REL_ L_ATCU_vMON SG_ 859 L_ATCU_Lib_Opt2ndTmpBtn 5000;
BA_ "Version" SG_ 859 L_ATCU_Lib_Opt2ndTmpBtn "23.11.10";
BA_ "Description" SG_ 859 L_ATCU_Lib_OptADS "This value only use for ATCU Library data monitoring (Only use before SOP)";
BA_ "GenSigSendType" SG_ 859 L_ATCU_Lib_OptADS 4;
BA_ "UserSigValidity" SG_ 859 L_ATCU_Lib_OptADS 0;
BA_REL_ "GenSigTimeoutTime" BU_SG_REL_ L_ATCU_vMON SG_ 859 L_ATCU_Lib_OptADS 5000;
BA_ "Version" SG_ 859 L_ATCU_Lib_OptADS "23.11.10";
BA_ "Description" SG_ 859 L_ATCU_Lib_OptAfterBlow "This value only use for ATCU Library data monitoring (Only use before SOP)";
BA_ "GenSigSendType" SG_ 859 L_ATCU_Lib_OptAfterBlow 4;
BA_ "UserSigValidity" SG_ 859 L_ATCU_Lib_OptAfterBlow 0;
BA_REL_ "GenSigTimeoutTime" BU_SG_REL_ L_ATCU_vMON SG_ 859 L_ATCU_Lib_OptAfterBlow 5000;
BA_ "Version" SG_ 859 L_ATCU_Lib_OptAfterBlow "23.11.10";
BA_ "Description" SG_ 859 L_ATCU_Lib_OptAutoStep "This value only use for ATCU Library data monitoring (Only use before SOP)";
BA_ "GenSigSendType" SG_ 859 L_ATCU_Lib_OptAutoStep 4;
BA_ "UserSigValidity" SG_ 859 L_ATCU_Lib_OptAutoStep 0;
BA_REL_ "GenSigTimeoutTime" BU_SG_REL_ L_ATCU_vMON SG_ 859 L_ATCU_Lib_OptAutoStep 5000;
BA_ "Version" SG_ 859 L_ATCU_Lib_OptAutoStep "23.11.10";
BA_ "Description" SG_ 859 L_ATCU_Lib_Opt2ndAutoBtn "This value only use for ATCU Library data monitoring (Only use before SOP)";
BA_ "GenSigSendType" SG_ 859 L_ATCU_Lib_Opt2ndAutoBtn 4;
BA_ "UserSigValidity" SG_ 859 L_ATCU_Lib_Opt2ndAutoBtn 0;
BA_REL_ "GenSigTimeoutTime" BU_SG_REL_ L_ATCU_vMON SG_ 859 L_ATCU_Lib_Opt2ndAutoBtn 5000;
BA_ "Version" SG_ 859 L_ATCU_Lib_Opt2ndAutoBtn "23.11.10";
BA_ "Description" SG_ 859 L_ATCU_Lib_OptAutoSwTyp "This value only use for ATCU Library data monitoring (Only use before SOP)";
BA_ "GenSigSendType" SG_ 859 L_ATCU_Lib_OptAutoSwTyp 4;
BA_ "UserSigValidity" SG_ 859 L_ATCU_Lib_OptAutoSwTyp 0;
BA_REL_ "GenSigTimeoutTime" BU_SG_REL_ L_ATCU_vMON SG_ 859 L_ATCU_Lib_OptAutoSwTyp 5000;
BA_ "Version" SG_ 859 L_ATCU_Lib_OptAutoSwTyp "23.11.10";
BA_ "Description" SG_ 859 L_ATCU_Lib_OptBATCoolingTyp "This value only use for ATCU Library data monitoring (Only use before SOP)";
BA_ "GenSigSendType" SG_ 859 L_ATCU_Lib_OptBATCoolingTyp 4;
BA_ "UserSigValidity" SG_ 859 L_ATCU_Lib_OptBATCoolingTyp 0;
BA_REL_ "GenSigTimeoutTime" BU_SG_REL_ L_ATCU_vMON SG_ 859 L_ATCU_Lib_OptBATCoolingTyp 5000;
BA_ "Version" SG_ 859 L_ATCU_Lib_OptBATCoolingTyp "23.11.10";
BA_ "Description" SG_ 859 L_ATCU_Lib_OptBlrSwKnob "This value only use for ATCU Library data monitoring (Only use before SOP)";
BA_ "GenSigSendType" SG_ 859 L_ATCU_Lib_OptBlrSwKnob 4;
BA_ "UserSigValidity" SG_ 859 L_ATCU_Lib_OptBlrSwKnob 0;
BA_REL_ "GenSigTimeoutTime" BU_SG_REL_ L_ATCU_vMON SG_ 859 L_ATCU_Lib_OptBlrSwKnob 5000;
BA_ "Version" SG_ 859 L_ATCU_Lib_OptBlrSwKnob "23.11.10";
BA_ "Description" SG_ 859 L_ATCU_Lib_OptComp "This value only use for ATCU Library data monitoring (Only use before SOP)";
BA_ "GenSigSendType" SG_ 859 L_ATCU_Lib_OptComp 4;
BA_ "UserSigValidity" SG_ 859 L_ATCU_Lib_OptComp 0;
BA_REL_ "GenSigTimeoutTime" BU_SG_REL_ L_ATCU_vMON SG_ 859 L_ATCU_Lib_OptComp 5000;
BA_ "Version" SG_ 859 L_ATCU_Lib_OptComp "23.11.10";
BA_ "Description" SG_ 859 L_ATCU_Lib_OptDrvHndSide "This value only use for ATCU Library data monitoring (Only use before SOP)";
BA_ "GenSigSendType" SG_ 859 L_ATCU_Lib_OptDrvHndSide 4;
BA_ "UserSigValidity" SG_ 859 L_ATCU_Lib_OptDrvHndSide 0;
BA_REL_ "GenSigTimeoutTime" BU_SG_REL_ L_ATCU_vMON SG_ 859 L_ATCU_Lib_OptDrvHndSide 5000;
BA_ "Version" SG_ 859 L_ATCU_Lib_OptDrvHndSide "23.11.10";
BA_ "Description" SG_ 859 L_ATCU_Lib_OptDrvOnly "This value only use for ATCU Library data monitoring (Only use before SOP)";
BA_ "GenSigSendType" SG_ 859 L_ATCU_Lib_OptDrvOnly 4;
BA_ "UserSigValidity" SG_ 859 L_ATCU_Lib_OptDrvOnly 0;
BA_REL_ "GenSigTimeoutTime" BU_SG_REL_ L_ATCU_vMON SG_ 859 L_ATCU_Lib_OptDrvOnly 5000;
BA_ "Version" SG_ 859 L_ATCU_Lib_OptDrvOnly "23.11.10";
BA_ "Description" SG_ 859 L_ATCU_Lib_OptFineDust "This value only use for ATCU Library data monitoring (Only use before SOP)";
BA_ "GenSigSendType" SG_ 859 L_ATCU_Lib_OptFineDust 4;
BA_ "UserSigValidity" SG_ 859 L_ATCU_Lib_OptFineDust 0;
BA_REL_ "GenSigTimeoutTime" BU_SG_REL_ L_ATCU_vMON SG_ 859 L_ATCU_Lib_OptFineDust 5000;
BA_ "Version" SG_ 859 L_ATCU_Lib_OptFineDust "23.11.10";
BA_ "Description" SG_ 859 L_ATCU_Lib_OptCoolHeatSeat "This value only use for ATCU Library data monitoring (Only use before SOP)";
BA_ "GenSigSendType" SG_ 859 L_ATCU_Lib_OptCoolHeatSeat 4;
BA_ "UserSigValidity" SG_ 859 L_ATCU_Lib_OptCoolHeatSeat 0;
BA_REL_ "GenSigTimeoutTime" BU_SG_REL_ L_ATCU_vMON SG_ 859 L_ATCU_Lib_OptCoolHeatSeat 5000;
BA_ "Version" SG_ 859 L_ATCU_Lib_OptCoolHeatSeat "23.11.10";
BA_ "Description" SG_ 859 L_ATCU_Lib_OptPTCTyp "This value only use for ATCU Library data monitoring (Only use before SOP)";
BA_ "GenSigSendType" SG_ 859 L_ATCU_Lib_OptPTCTyp 4;
BA_ "UserSigValidity" SG_ 859 L_ATCU_Lib_OptPTCTyp 0;
BA_REL_ "GenSigTimeoutTime" BU_SG_REL_ L_ATCU_vMON SG_ 859 L_ATCU_Lib_OptPTCTyp 5000;
BA_ "Version" SG_ 859 L_ATCU_Lib_OptPTCTyp "23.11.10";
BA_ "Description" SG_ 859 L_ATCU_Lib_OptLCDDisp "This value only use for ATCU Library data monitoring (Only use before SOP)";
BA_ "GenSigSendType" SG_ 859 L_ATCU_Lib_OptLCDDisp 4;
BA_ "UserSigValidity" SG_ 859 L_ATCU_Lib_OptLCDDisp 0;
BA_REL_ "GenSigTimeoutTime" BU_SG_REL_ L_ATCU_vMON SG_ 859 L_ATCU_Lib_OptLCDDisp 5000;
BA_ "Version" SG_ 859 L_ATCU_Lib_OptLCDDisp "23.11.10";
BA_ "Description" SG_ 859 L_ATCU_Lib_OptModSwTyp "This value only use for ATCU Library data monitoring (Only use before SOP)";
BA_ "GenSigSendType" SG_ 859 L_ATCU_Lib_OptModSwTyp 4;
BA_ "UserSigValidity" SG_ 859 L_ATCU_Lib_OptModSwTyp 0;
BA_REL_ "GenSigTimeoutTime" BU_SG_REL_ L_ATCU_vMON SG_ 859 L_ATCU_Lib_OptModSwTyp 5000;
BA_ "Version" SG_ 859 L_ATCU_Lib_OptModSwTyp "23.11.10";
BA_ "Description" SG_ 859 L_ATCU_Lib_OptOffSwTyp "This value only use for ATCU Library data monitoring (Only use before SOP)";
BA_ "GenSigSendType" SG_ 859 L_ATCU_Lib_OptOffSwTyp 4;
BA_ "UserSigValidity" SG_ 859 L_ATCU_Lib_OptOffSwTyp 0;
BA_REL_ "GenSigTimeoutTime" BU_SG_REL_ L_ATCU_vMON SG_ 859 L_ATCU_Lib_OptOffSwTyp 5000;
BA_ "Version" SG_ 859 L_ATCU_Lib_OptOffSwTyp "23.11.10";
BA_ "Description" SG_ 859 L_ATCU_Lib_Opt2ndAutoStep "This value only use for ATCU Library data monitoring (Only use before SOP)";
BA_ "GenSigSendType" SG_ 859 L_ATCU_Lib_Opt2ndAutoStep 4;
BA_ "UserSigValidity" SG_ 859 L_ATCU_Lib_Opt2ndAutoStep 0;
BA_REL_ "GenSigTimeoutTime" BU_SG_REL_ L_ATCU_vMON SG_ 859 L_ATCU_Lib_Opt2ndAutoStep 5000;
BA_ "Version" SG_ 859 L_ATCU_Lib_Opt2ndAutoStep "23.11.10";
BA_ "Description" SG_ 859 L_ATCU_Lib_OptNetworkTyp "This value only use for ATCU Library data monitoring (Only use before SOP)";
BA_ "GenSigSendType" SG_ 859 L_ATCU_Lib_OptNetworkTyp 4;
BA_ "UserSigValidity" SG_ 859 L_ATCU_Lib_OptNetworkTyp 0;
BA_REL_ "GenSigTimeoutTime" BU_SG_REL_ L_ATCU_vMON SG_ 859 L_ATCU_Lib_OptNetworkTyp 5000;
BA_ "Version" SG_ 859 L_ATCU_Lib_OptNetworkTyp "23.11.10";
BA_ "Description" SG_ 859 L_ATCU_Lib_OptPTCStep "This value only use for ATCU Library data monitoring (Only use before SOP)";
BA_ "GenSigSendType" SG_ 859 L_ATCU_Lib_OptPTCStep 4;
BA_ "UserSigValidity" SG_ 859 L_ATCU_Lib_OptPTCStep 0;
BA_REL_ "GenSigTimeoutTime" BU_SG_REL_ L_ATCU_vMON SG_ 859 L_ATCU_Lib_OptPTCStep 5000;
BA_ "Version" SG_ 859 L_ATCU_Lib_OptPTCStep "23.11.10";
BA_ "Description" SG_ 859 L_ATCU_Lib_OptPTG "This value only use for ATCU Library data monitoring (Only use before SOP)";
BA_ "GenSigSendType" SG_ 859 L_ATCU_Lib_OptPTG 4;
BA_ "UserSigValidity" SG_ 859 L_ATCU_Lib_OptPTG 0;
BA_REL_ "GenSigTimeoutTime" BU_SG_REL_ L_ATCU_vMON SG_ 859 L_ATCU_Lib_OptPTG 5000;
BA_ "Version" SG_ 859 L_ATCU_Lib_OptPTG "23.11.10";
BA_ "Description" SG_ 859 L_ATCU_Lib_OptROATyp "This value only use for ATCU Library data monitoring (Only use before SOP)";
BA_ "GenSigSendType" SG_ 859 L_ATCU_Lib_OptROATyp 4;
BA_ "UserSigValidity" SG_ 859 L_ATCU_Lib_OptROATyp 0;
BA_REL_ "GenSigTimeoutTime" BU_SG_REL_ L_ATCU_vMON SG_ 859 L_ATCU_Lib_OptROATyp 5000;
BA_ "Version" SG_ 859 L_ATCU_Lib_OptROATyp "23.11.10";
BA_ "Description" SG_ 859 L_ATCU_Lib_OptVRLED "This value only use for ATCU Library data monitoring (Only use before SOP)";
BA_ "GenSigSendType" SG_ 859 L_ATCU_Lib_OptVRLED 4;
BA_ "UserSigValidity" SG_ 859 L_ATCU_Lib_OptVRLED 0;
BA_REL_ "GenSigTimeoutTime" BU_SG_REL_ L_ATCU_vMON SG_ 859 L_ATCU_Lib_OptVRLED 5000;
BA_ "Version" SG_ 859 L_ATCU_Lib_OptVRLED "25.05.03";
BA_ "Description" SG_ 859 L_ATCU_Lib_OptRgn "This value only use for ATCU Library data monitoring (Only use before SOP)";
BA_ "GenSigSendType" SG_ 859 L_ATCU_Lib_OptRgn 4;
BA_ "UserSigValidity" SG_ 859 L_ATCU_Lib_OptRgn 0;
BA_REL_ "GenSigTimeoutTime" BU_SG_REL_ L_ATCU_vMON SG_ 859 L_ATCU_Lib_OptRgn 5000;
BA_ "Version" SG_ 859 L_ATCU_Lib_OptRgn "23.11.10";
BA_ "Description" SG_ 859 L_ATCU_Lib_OptSchdldVent "This value only use for ATCU Library data monitoring (Only use before SOP)";
BA_ "GenSigSendType" SG_ 859 L_ATCU_Lib_OptSchdldVent 4;
BA_ "UserSigValidity" SG_ 859 L_ATCU_Lib_OptSchdldVent 0;
BA_REL_ "GenSigTimeoutTime" BU_SG_REL_ L_ATCU_vMON SG_ 859 L_ATCU_Lib_OptSchdldVent 5000;
BA_ "Version" SG_ 859 L_ATCU_Lib_OptSchdldVent "23.11.10";
BA_ "Description" SG_ 859 L_ATCU_Lib_OptIntakeSwTyp "This value only use for ATCU Library data monitoring (Only use before SOP)";
BA_ "GenSigSendType" SG_ 859 L_ATCU_Lib_OptIntakeSwTyp 4;
BA_ "UserSigValidity" SG_ 859 L_ATCU_Lib_OptIntakeSwTyp 0;
BA_REL_ "GenSigTimeoutTime" BU_SG_REL_ L_ATCU_vMON SG_ 859 L_ATCU_Lib_OptIntakeSwTyp 5000;
BA_ "Version" SG_ 859 L_ATCU_Lib_OptIntakeSwTyp "23.11.10";
BA_ "Description" SG_ 859 L_ATCU_Lib_OptStrHeat "This value only use for ATCU Library data monitoring (Only use before SOP)";
BA_ "GenSigSendType" SG_ 859 L_ATCU_Lib_OptStrHeat 4;
BA_ "UserSigValidity" SG_ 859 L_ATCU_Lib_OptStrHeat 0;
BA_REL_ "GenSigTimeoutTime" BU_SG_REL_ L_ATCU_vMON SG_ 859 L_ATCU_Lib_OptStrHeat 5000;
BA_ "Version" SG_ 859 L_ATCU_Lib_OptStrHeat "23.11.10";
BA_ "Description" SG_ 859 L_ATCU_Lib_OptSync "This value only use for ATCU Library data monitoring (Only use before SOP)";
BA_ "GenSigSendType" SG_ 859 L_ATCU_Lib_OptSync 4;
BA_ "UserSigValidity" SG_ 859 L_ATCU_Lib_OptSync 0;
BA_REL_ "GenSigTimeoutTime" BU_SG_REL_ L_ATCU_vMON SG_ 859 L_ATCU_Lib_OptSync 5000;
BA_ "Version" SG_ 859 L_ATCU_Lib_OptSync "23.11.10";
BA_ "Description" SG_ 859 L_ATCU_Lib_OptTempSwKnob "This value only use for ATCU Library data monitoring (Only use before SOP)";
BA_ "GenSigSendType" SG_ 859 L_ATCU_Lib_OptTempSwKnob 4;
BA_ "UserSigValidity" SG_ 859 L_ATCU_Lib_OptTempSwKnob 0;
BA_REL_ "GenSigTimeoutTime" BU_SG_REL_ L_ATCU_vMON SG_ 859 L_ATCU_Lib_OptTempSwKnob 5000;
BA_ "Version" SG_ 859 L_ATCU_Lib_OptTempSwKnob "23.11.10";
BA_ "Description" SG_ 859 L_ATCU_Lib_OptThermostat "This value only use for ATCU Library data monitoring (Only use before SOP)";
BA_ "GenSigSendType" SG_ 859 L_ATCU_Lib_OptThermostat 4;
BA_ "UserSigValidity" SG_ 859 L_ATCU_Lib_OptThermostat 0;
BA_REL_ "GenSigTimeoutTime" BU_SG_REL_ L_ATCU_vMON SG_ 859 L_ATCU_Lib_OptThermostat 5000;
BA_ "Version" SG_ 859 L_ATCU_Lib_OptThermostat "23.11.10";
BA_ "Description" SG_ 859 L_ATCU_Lib_OptVehTyp "This value only use for ATCU Library data monitoring (Only use before SOP)";
BA_ "GenSigSendType" SG_ 859 L_ATCU_Lib_OptVehTyp 4;
BA_ "UserSigValidity" SG_ 859 L_ATCU_Lib_OptVehTyp 0;
BA_REL_ "GenSigTimeoutTime" BU_SG_REL_ L_ATCU_vMON SG_ 859 L_ATCU_Lib_OptVehTyp 5000;
BA_ "Version" SG_ 859 L_ATCU_Lib_OptVehTyp "23.11.10";
BA_ "Description" SG_ 859 L_ATCU_Lib_Opt2ndAutoSwTyp "This value only use for ATCU Library data monitoring (Only use before SOP)";
BA_ "GenSigSendType" SG_ 859 L_ATCU_Lib_Opt2ndAutoSwTyp 4;
BA_ "UserSigValidity" SG_ 859 L_ATCU_Lib_Opt2ndAutoSwTyp 0;
BA_REL_ "GenSigTimeoutTime" BU_SG_REL_ L_ATCU_vMON SG_ 859 L_ATCU_Lib_Opt2ndAutoSwTyp 5000;
BA_ "Version" SG_ 859 L_ATCU_Lib_Opt2ndAutoSwTyp "23.11.10";
BA_ "Description" SG_ 859 L_ATCU_Lib_OptWheelDrivePos "This value only use for ATCU Library data monitoring (Only use before SOP)";
BA_ "GenSigSendType" SG_ 859 L_ATCU_Lib_OptWheelDrivePos 4;
BA_ "UserSigValidity" SG_ 859 L_ATCU_Lib_OptWheelDrivePos 0;
BA_REL_ "GenSigTimeoutTime" BU_SG_REL_ L_ATCU_vMON SG_ 859 L_ATCU_Lib_OptWheelDrivePos 5000;
BA_ "Version" SG_ 859 L_ATCU_Lib_OptWheelDrivePos "23.11.10";
BA_ "Description" SG_ 859 L_ATCU_Lib_Opt2ndTempSwKnob "This value only use for ATCU Library data monitoring (Only use before SOP)";
BA_ "GenSigSendType" SG_ 859 L_ATCU_Lib_Opt2ndTempSwKnob 4;
BA_ "UserSigValidity" SG_ 859 L_ATCU_Lib_Opt2ndTempSwKnob 0;
BA_REL_ "GenSigTimeoutTime" BU_SG_REL_ L_ATCU_vMON SG_ 859 L_ATCU_Lib_Opt2ndTempSwKnob 5000;
BA_ "Version" SG_ 859 L_ATCU_Lib_Opt2ndTempSwKnob "23.11.10";
BA_ "Description" SG_ 859 L_ATCU_Lib_Opt2ndBlrBtn "This value only use for ATCU Library data monitoring (Only use before SOP)";
BA_ "GenSigSendType" SG_ 859 L_ATCU_Lib_Opt2ndBlrBtn 4;
BA_ "UserSigValidity" SG_ 859 L_ATCU_Lib_Opt2ndBlrBtn 0;
BA_REL_ "GenSigTimeoutTime" BU_SG_REL_ L_ATCU_vMON SG_ 859 L_ATCU_Lib_Opt2ndBlrBtn 5000;
BA_ "Version" SG_ 859 L_ATCU_Lib_Opt2ndBlrBtn "23.11.10";
BA_ "GenMsgSendType" BO_ 861 0;
BA_ "GenMsgCycleTime" BO_ 861 500;
BA_ "Description" SG_ 861 L_ATCU_Lib_MngrModBufOp "This value only use for ATCU Library data monitoring (Only use before SOP)";
BA_ "GenSigSendType" SG_ 861 L_ATCU_Lib_MngrModBufOp 4;
BA_ "UserSigValidity" SG_ 861 L_ATCU_Lib_MngrModBufOp 0;
BA_REL_ "GenSigTimeoutTime" BU_SG_REL_ L_ATCU_vMON SG_ 861 L_ATCU_Lib_MngrModBufOp 5000;
BA_ "Version" SG_ 861 L_ATCU_Lib_MngrModBufOp "23.11.10";
BA_ "Description" SG_ 861 L_ATCU_Lib_MngrDEFBufOp "This value only use for ATCU Library data monitoring (Only use before SOP)";
BA_ "GenSigSendType" SG_ 861 L_ATCU_Lib_MngrDEFBufOp 4;
BA_ "UserSigValidity" SG_ 861 L_ATCU_Lib_MngrDEFBufOp 0;
BA_REL_ "GenSigTimeoutTime" BU_SG_REL_ L_ATCU_vMON SG_ 861 L_ATCU_Lib_MngrDEFBufOp 5000;
BA_ "Version" SG_ 861 L_ATCU_Lib_MngrDEFBufOp "23.11.10";
BA_ "Description" SG_ 861 L_ATCU_Lib_MngrBlwBufOp "This value only use for ATCU Library data monitoring (Only use before SOP)";
BA_ "GenSigSendType" SG_ 861 L_ATCU_Lib_MngrBlwBufOp 4;
BA_ "UserSigValidity" SG_ 861 L_ATCU_Lib_MngrBlwBufOp 0;
BA_REL_ "GenSigTimeoutTime" BU_SG_REL_ L_ATCU_vMON SG_ 861 L_ATCU_Lib_MngrBlwBufOp 5000;
BA_ "Version" SG_ 861 L_ATCU_Lib_MngrBlwBufOp "24.06.02";
BA_ "Description" SG_ 861 L_ATCU_Lib_MngrACBufOp "This value only use for ATCU Library data monitoring (Only use before SOP)";
BA_ "GenSigSendType" SG_ 861 L_ATCU_Lib_MngrACBufOp 4;
BA_ "UserSigValidity" SG_ 861 L_ATCU_Lib_MngrACBufOp 0;
BA_REL_ "GenSigTimeoutTime" BU_SG_REL_ L_ATCU_vMON SG_ 861 L_ATCU_Lib_MngrACBufOp 5000;
BA_ "Version" SG_ 861 L_ATCU_Lib_MngrACBufOp "23.11.10";
BA_ "Description" SG_ 861 L_ATCU_Lib_2LHMngrBlwBufOp "This value only use for ATCU Library data monitoring (Only use before SOP)";
BA_ "GenSigSendType" SG_ 861 L_ATCU_Lib_2LHMngrBlwBufOp 4;
BA_ "UserSigValidity" SG_ 861 L_ATCU_Lib_2LHMngrBlwBufOp 0;
BA_REL_ "GenSigTimeoutTime" BU_SG_REL_ L_ATCU_vMON SG_ 861 L_ATCU_Lib_2LHMngrBlwBufOp 5000;
BA_ "Version" SG_ 861 L_ATCU_Lib_2LHMngrBlwBufOp "23.11.10";
BA_ "Description" SG_ 861 L_ATCU_Lib_2LHMngrModBufOp "This value only use for ATCU Library data monitoring (Only use before SOP)";
BA_ "GenSigSendType" SG_ 861 L_ATCU_Lib_2LHMngrModBufOp 4;
BA_ "UserSigValidity" SG_ 861 L_ATCU_Lib_2LHMngrModBufOp 0;
BA_REL_ "GenSigTimeoutTime" BU_SG_REL_ L_ATCU_vMON SG_ 861 L_ATCU_Lib_2LHMngrModBufOp 5000;
BA_ "Version" SG_ 861 L_ATCU_Lib_2LHMngrModBufOp "23.11.10";
BA_ "Description" SG_ 861 L_ATCU_Lib_2LHMngrTempBufOp "This value only use for ATCU Library data monitoring (Only use before SOP)";
BA_ "GenSigSendType" SG_ 861 L_ATCU_Lib_2LHMngrTempBufOp 4;
BA_ "UserSigValidity" SG_ 861 L_ATCU_Lib_2LHMngrTempBufOp 0;
BA_REL_ "GenSigTimeoutTime" BU_SG_REL_ L_ATCU_vMON SG_ 861 L_ATCU_Lib_2LHMngrTempBufOp 5000;
BA_ "Version" SG_ 861 L_ATCU_Lib_2LHMngrTempBufOp "23.11.10";
BA_ "Description" SG_ 861 L_ATCU_Lib_2RHMngrTempBufOp "This value only use for ATCU Library data monitoring (Only use before SOP)";
BA_ "GenSigSendType" SG_ 861 L_ATCU_Lib_2RHMngrTempBufOp 4;
BA_ "UserSigValidity" SG_ 861 L_ATCU_Lib_2RHMngrTempBufOp 0;
BA_REL_ "GenSigTimeoutTime" BU_SG_REL_ L_ATCU_vMON SG_ 861 L_ATCU_Lib_2RHMngrTempBufOp 5000;
BA_ "Version" SG_ 861 L_ATCU_Lib_2RHMngrTempBufOp "23.11.10";
BA_ "Description" SG_ 861 L_ATCU_Lib_MngrActvIncarMotPwr "This value only use for ATCU Library data monitoring (Only use before SOP)";
BA_ "GenSigSendType" SG_ 861 L_ATCU_Lib_MngrActvIncarMotPwr 4;
BA_ "UserSigValidity" SG_ 861 L_ATCU_Lib_MngrActvIncarMotPwr 0;
BA_REL_ "GenSigTimeoutTime" BU_SG_REL_ L_ATCU_vMON SG_ 861 L_ATCU_Lib_MngrActvIncarMotPwr 5000;
BA_ "Version" SG_ 861 L_ATCU_Lib_MngrActvIncarMotPwr "23.11.10";
BA_ "Description" SG_ 861 L_ATCU_Lib_MngrPDCWakeUpReq "This value only use for ATCU Library data monitoring (Only use before SOP)";
BA_ "GenSigSendType" SG_ 861 L_ATCU_Lib_MngrPDCWakeUpReq 4;
BA_ "UserSigValidity" SG_ 861 L_ATCU_Lib_MngrPDCWakeUpReq 0;
BA_REL_ "GenSigTimeoutTime" BU_SG_REL_ L_ATCU_vMON SG_ 861 L_ATCU_Lib_MngrPDCWakeUpReq 5000;
BA_ "Version" SG_ 861 L_ATCU_Lib_MngrPDCWakeUpReq "23.11.10";
BA_ "Description" SG_ 861 L_ATCU_Lib_MngrLVPTCRly1Sta "This value only use for ATCU Library data monitoring (Only use before SOP)";
BA_ "GenSigSendType" SG_ 861 L_ATCU_Lib_MngrLVPTCRly1Sta 4;
BA_ "UserSigValidity" SG_ 861 L_ATCU_Lib_MngrLVPTCRly1Sta 0;
BA_REL_ "GenSigTimeoutTime" BU_SG_REL_ L_ATCU_vMON SG_ 861 L_ATCU_Lib_MngrLVPTCRly1Sta 5000;
BA_ "Version" SG_ 861 L_ATCU_Lib_MngrLVPTCRly1Sta "23.11.10";
BA_ "Description" SG_ 861 L_ATCU_Lib_MngrLVPTCRly2Sta "This value only use for ATCU Library data monitoring (Only use before SOP)";
BA_ "GenSigSendType" SG_ 861 L_ATCU_Lib_MngrLVPTCRly2Sta 4;
BA_ "UserSigValidity" SG_ 861 L_ATCU_Lib_MngrLVPTCRly2Sta 0;
BA_REL_ "GenSigTimeoutTime" BU_SG_REL_ L_ATCU_vMON SG_ 861 L_ATCU_Lib_MngrLVPTCRly2Sta 5000;
BA_ "Version" SG_ 861 L_ATCU_Lib_MngrLVPTCRly2Sta "23.11.10";
BA_ "Description" SG_ 861 L_ATCU_Lib_MngrLVPTCRly3Sta "This value only use for ATCU Library data monitoring (Only use before SOP)";
BA_ "GenSigSendType" SG_ 861 L_ATCU_Lib_MngrLVPTCRly3Sta 4;
BA_ "UserSigValidity" SG_ 861 L_ATCU_Lib_MngrLVPTCRly3Sta 0;
BA_REL_ "GenSigTimeoutTime" BU_SG_REL_ L_ATCU_vMON SG_ 861 L_ATCU_Lib_MngrLVPTCRly3Sta 5000;
BA_ "Version" SG_ 861 L_ATCU_Lib_MngrLVPTCRly3Sta "23.11.10";
BA_ "Description" SG_ 861 L_ATCU_Lib_MngrTempBufOp "This value only use for ATCU Library data monitoring (Only use before SOP)";
BA_ "GenSigSendType" SG_ 861 L_ATCU_Lib_MngrTempBufOp 4;
BA_ "UserSigValidity" SG_ 861 L_ATCU_Lib_MngrTempBufOp 0;
BA_REL_ "GenSigTimeoutTime" BU_SG_REL_ L_ATCU_vMON SG_ 861 L_ATCU_Lib_MngrTempBufOp 5000;
BA_ "Version" SG_ 861 L_ATCU_Lib_MngrTempBufOp "23.11.10";
BA_ "Description" SG_ 861 L_ATCU_Lib_MngrIntakeBufOp "This value only use for ATCU Library data monitoring (Only use before SOP)";
BA_ "GenSigSendType" SG_ 861 L_ATCU_Lib_MngrIntakeBufOp 4;
BA_ "UserSigValidity" SG_ 861 L_ATCU_Lib_MngrIntakeBufOp 0;
BA_REL_ "GenSigTimeoutTime" BU_SG_REL_ L_ATCU_vMON SG_ 861 L_ATCU_Lib_MngrIntakeBufOp 5000;
BA_ "Version" SG_ 861 L_ATCU_Lib_MngrIntakeBufOp "24.09.00";
BA_ "GenMsgSendType" BO_ 862 0;
BA_ "GenMsgCycleTime" BO_ 862 500;
BA_ "Description" SG_ 862 L_ATCU_Lib_MngrModBuf0 "This value only use for ATCU Library data monitoring (Only use before SOP)";
BA_ "GenSigSendType" SG_ 862 L_ATCU_Lib_MngrModBuf0 4;
BA_ "UserSigValidity" SG_ 862 L_ATCU_Lib_MngrModBuf0 0;
BA_REL_ "GenSigTimeoutTime" BU_SG_REL_ L_ATCU_vMON SG_ 862 L_ATCU_Lib_MngrModBuf0 5000;
BA_ "Version" SG_ 862 L_ATCU_Lib_MngrModBuf0 "25.05.03";
BA_ "Description" SG_ 862 L_ATCU_Lib_MngrModBufLow1 "This value only use for ATCU Library data monitoring (Only use before SOP)";
BA_ "GenSigSendType" SG_ 862 L_ATCU_Lib_MngrModBufLow1 4;
BA_ "UserSigValidity" SG_ 862 L_ATCU_Lib_MngrModBufLow1 0;
BA_REL_ "GenSigTimeoutTime" BU_SG_REL_ L_ATCU_vMON SG_ 862 L_ATCU_Lib_MngrModBufLow1 5000;
BA_ "Version" SG_ 862 L_ATCU_Lib_MngrModBufLow1 "23.11.10";
BA_ "Description" SG_ 862 L_ATCU_Lib_MngrModBuf2 "This value only use for ATCU Library data monitoring (Only use before SOP)";
BA_ "GenSigSendType" SG_ 862 L_ATCU_Lib_MngrModBuf2 4;
BA_ "UserSigValidity" SG_ 862 L_ATCU_Lib_MngrModBuf2 0;
BA_REL_ "GenSigTimeoutTime" BU_SG_REL_ L_ATCU_vMON SG_ 862 L_ATCU_Lib_MngrModBuf2 5000;
BA_ "Version" SG_ 862 L_ATCU_Lib_MngrModBuf2 "25.05.03";
BA_ "Description" SG_ 862 L_ATCU_Lib_MngrModBufHi0 "This value only use for ATCU Library data monitoring (Only use before SOP)";
BA_ "GenSigSendType" SG_ 862 L_ATCU_Lib_MngrModBufHi0 4;
BA_ "UserSigValidity" SG_ 862 L_ATCU_Lib_MngrModBufHi0 0;
BA_REL_ "GenSigTimeoutTime" BU_SG_REL_ L_ATCU_vMON SG_ 862 L_ATCU_Lib_MngrModBufHi0 5000;
BA_ "Version" SG_ 862 L_ATCU_Lib_MngrModBufHi0 "23.11.10";
BA_ "Description" SG_ 862 L_ATCU_Lib_MngrModBuf3 "This value only use for ATCU Library data monitoring (Only use before SOP)";
BA_ "GenSigSendType" SG_ 862 L_ATCU_Lib_MngrModBuf3 4;
BA_ "UserSigValidity" SG_ 862 L_ATCU_Lib_MngrModBuf3 0;
BA_REL_ "GenSigTimeoutTime" BU_SG_REL_ L_ATCU_vMON SG_ 862 L_ATCU_Lib_MngrModBuf3 5000;
BA_ "Version" SG_ 862 L_ATCU_Lib_MngrModBuf3 "25.05.03";
BA_ "Description" SG_ 862 L_ATCU_Lib_MngrModBufHi1 "This value only use for ATCU Library data monitoring (Only use before SOP)";
BA_ "GenSigSendType" SG_ 862 L_ATCU_Lib_MngrModBufHi1 4;
BA_ "UserSigValidity" SG_ 862 L_ATCU_Lib_MngrModBufHi1 0;
BA_REL_ "GenSigTimeoutTime" BU_SG_REL_ L_ATCU_vMON SG_ 862 L_ATCU_Lib_MngrModBufHi1 5000;
BA_ "Version" SG_ 862 L_ATCU_Lib_MngrModBufHi1 "23.11.10";
BA_ "Description" SG_ 862 L_ATCU_Lib_MngrModBuf4 "This value only use for ATCU Library data monitoring (Only use before SOP)";
BA_ "GenSigSendType" SG_ 862 L_ATCU_Lib_MngrModBuf4 4;
BA_ "UserSigValidity" SG_ 862 L_ATCU_Lib_MngrModBuf4 0;
BA_REL_ "GenSigTimeoutTime" BU_SG_REL_ L_ATCU_vMON SG_ 862 L_ATCU_Lib_MngrModBuf4 5000;
BA_ "Version" SG_ 862 L_ATCU_Lib_MngrModBuf4 "25.05.03";
BA_ "Description" SG_ 862 L_ATCU_Lib_MngrModBuf5 "This value only use for ATCU Library data monitoring (Only use before SOP)";
BA_ "GenSigSendType" SG_ 862 L_ATCU_Lib_MngrModBuf5 4;
BA_ "UserSigValidity" SG_ 862 L_ATCU_Lib_MngrModBuf5 0;
BA_REL_ "GenSigTimeoutTime" BU_SG_REL_ L_ATCU_vMON SG_ 862 L_ATCU_Lib_MngrModBuf5 5000;
BA_ "Version" SG_ 862 L_ATCU_Lib_MngrModBuf5 "25.05.03";
BA_ "Description" SG_ 862 L_ATCU_Lib_MngrModBuf6 "This value only use for ATCU Library data monitoring (Only use before SOP)";
BA_ "GenSigSendType" SG_ 862 L_ATCU_Lib_MngrModBuf6 4;
BA_ "UserSigValidity" SG_ 862 L_ATCU_Lib_MngrModBuf6 0;
BA_REL_ "GenSigTimeoutTime" BU_SG_REL_ L_ATCU_vMON SG_ 862 L_ATCU_Lib_MngrModBuf6 5000;
BA_ "Version" SG_ 862 L_ATCU_Lib_MngrModBuf6 "25.05.03";
BA_ "Description" SG_ 862 L_ATCU_Lib_MngrModBufLow0 "This value only use for ATCU Library data monitoring (Only use before SOP)";
BA_ "GenSigSendType" SG_ 862 L_ATCU_Lib_MngrModBufLow0 4;
BA_ "UserSigValidity" SG_ 862 L_ATCU_Lib_MngrModBufLow0 0;
BA_REL_ "GenSigTimeoutTime" BU_SG_REL_ L_ATCU_vMON SG_ 862 L_ATCU_Lib_MngrModBufLow0 5000;
BA_ "Version" SG_ 862 L_ATCU_Lib_MngrModBufLow0 "23.11.10";
BA_ "Description" SG_ 862 L_ATCU_Lib_MngrModBuf7 "This value only use for ATCU Library data monitoring (Only use before SOP)";
BA_ "GenSigSendType" SG_ 862 L_ATCU_Lib_MngrModBuf7 4;
BA_ "UserSigValidity" SG_ 862 L_ATCU_Lib_MngrModBuf7 0;
BA_REL_ "GenSigTimeoutTime" BU_SG_REL_ L_ATCU_vMON SG_ 862 L_ATCU_Lib_MngrModBuf7 5000;
BA_ "Version" SG_ 862 L_ATCU_Lib_MngrModBuf7 "25.05.03";
BA_ "Description" SG_ 862 L_ATCU_Lib_MngrModBuf1 "This value only use for ATCU Library data monitoring (Only use before SOP)";
BA_ "GenSigSendType" SG_ 862 L_ATCU_Lib_MngrModBuf1 4;
BA_ "UserSigValidity" SG_ 862 L_ATCU_Lib_MngrModBuf1 0;
BA_REL_ "GenSigTimeoutTime" BU_SG_REL_ L_ATCU_vMON SG_ 862 L_ATCU_Lib_MngrModBuf1 5000;
BA_ "Version" SG_ 862 L_ATCU_Lib_MngrModBuf1 "25.05.03";
BA_ "GenMsgSendType" BO_ 863 0;
BA_ "GenMsgCycleTime" BO_ 863 500;
BA_ "Description" SG_ 863 L_ATCU_Lib_MngrBlwBuf0 "This value only use for ATCU Library data monitoring (Only use before SOP)";
BA_ "GenSigSendType" SG_ 863 L_ATCU_Lib_MngrBlwBuf0 4;
BA_ "UserSigValidity" SG_ 863 L_ATCU_Lib_MngrBlwBuf0 0;
BA_REL_ "GenSigTimeoutTime" BU_SG_REL_ L_ATCU_vMON SG_ 863 L_ATCU_Lib_MngrBlwBuf0 5000;
BA_ "Version" SG_ 863 L_ATCU_Lib_MngrBlwBuf0 "25.05.03";
BA_ "Description" SG_ 863 L_ATCU_Lib_MngrBlwBuf3 "This value only use for ATCU Library data monitoring (Only use before SOP)";
BA_ "GenSigSendType" SG_ 863 L_ATCU_Lib_MngrBlwBuf3 4;
BA_ "UserSigValidity" SG_ 863 L_ATCU_Lib_MngrBlwBuf3 0;
BA_REL_ "GenSigTimeoutTime" BU_SG_REL_ L_ATCU_vMON SG_ 863 L_ATCU_Lib_MngrBlwBuf3 5000;
BA_ "Version" SG_ 863 L_ATCU_Lib_MngrBlwBuf3 "25.05.03";
BA_ "Description" SG_ 863 L_ATCU_Lib_MngrBlwBuf4 "This value only use for ATCU Library data monitoring (Only use before SOP)";
BA_ "GenSigSendType" SG_ 863 L_ATCU_Lib_MngrBlwBuf4 4;
BA_ "UserSigValidity" SG_ 863 L_ATCU_Lib_MngrBlwBuf4 0;
BA_REL_ "GenSigTimeoutTime" BU_SG_REL_ L_ATCU_vMON SG_ 863 L_ATCU_Lib_MngrBlwBuf4 5000;
BA_ "Version" SG_ 863 L_ATCU_Lib_MngrBlwBuf4 "25.05.03";
BA_ "Description" SG_ 863 L_ATCU_Lib_MngrBlwBuf5 "This value only use for ATCU Library data monitoring (Only use before SOP)";
BA_ "GenSigSendType" SG_ 863 L_ATCU_Lib_MngrBlwBuf5 4;
BA_ "UserSigValidity" SG_ 863 L_ATCU_Lib_MngrBlwBuf5 0;
BA_REL_ "GenSigTimeoutTime" BU_SG_REL_ L_ATCU_vMON SG_ 863 L_ATCU_Lib_MngrBlwBuf5 5000;
BA_ "Version" SG_ 863 L_ATCU_Lib_MngrBlwBuf5 "25.05.03";
BA_ "Description" SG_ 863 L_ATCU_Lib_MngrBlwBuf6 "This value only use for ATCU Library data monitoring (Only use before SOP)";
BA_ "GenSigSendType" SG_ 863 L_ATCU_Lib_MngrBlwBuf6 4;
BA_ "UserSigValidity" SG_ 863 L_ATCU_Lib_MngrBlwBuf6 0;
BA_REL_ "GenSigTimeoutTime" BU_SG_REL_ L_ATCU_vMON SG_ 863 L_ATCU_Lib_MngrBlwBuf6 5000;
BA_ "Version" SG_ 863 L_ATCU_Lib_MngrBlwBuf6 "25.05.03";
BA_ "Description" SG_ 863 L_ATCU_Lib_MngrBlwBuf7 "This value only use for ATCU Library data monitoring (Only use before SOP)";
BA_ "GenSigSendType" SG_ 863 L_ATCU_Lib_MngrBlwBuf7 4;
BA_ "UserSigValidity" SG_ 863 L_ATCU_Lib_MngrBlwBuf7 0;
BA_REL_ "GenSigTimeoutTime" BU_SG_REL_ L_ATCU_vMON SG_ 863 L_ATCU_Lib_MngrBlwBuf7 5000;
BA_ "Version" SG_ 863 L_ATCU_Lib_MngrBlwBuf7 "25.05.03";
BA_ "Description" SG_ 863 L_ATCU_Lib_MngrBlwBufHi0 "This value only use for ATCU Library data monitoring (Only use before SOP)";
BA_ "GenSigSendType" SG_ 863 L_ATCU_Lib_MngrBlwBufHi0 4;
BA_ "UserSigValidity" SG_ 863 L_ATCU_Lib_MngrBlwBufHi0 0;
BA_REL_ "GenSigTimeoutTime" BU_SG_REL_ L_ATCU_vMON SG_ 863 L_ATCU_Lib_MngrBlwBufHi0 5000;
BA_ "Version" SG_ 863 L_ATCU_Lib_MngrBlwBufHi0 "23.11.10";
BA_ "Description" SG_ 863 L_ATCU_Lib_MngrBlwBufLow0 "This value only use for ATCU Library data monitoring (Only use before SOP)";
BA_ "GenSigSendType" SG_ 863 L_ATCU_Lib_MngrBlwBufLow0 4;
BA_ "UserSigValidity" SG_ 863 L_ATCU_Lib_MngrBlwBufLow0 0;
BA_REL_ "GenSigTimeoutTime" BU_SG_REL_ L_ATCU_vMON SG_ 863 L_ATCU_Lib_MngrBlwBufLow0 5000;
BA_ "Version" SG_ 863 L_ATCU_Lib_MngrBlwBufLow0 "23.11.10";
BA_ "Description" SG_ 863 L_ATCU_Lib_MngrBlwBufLow1 "This value only use for ATCU Library data monitoring (Only use before SOP)";
BA_ "GenSigSendType" SG_ 863 L_ATCU_Lib_MngrBlwBufLow1 4;
BA_ "UserSigValidity" SG_ 863 L_ATCU_Lib_MngrBlwBufLow1 0;
BA_REL_ "GenSigTimeoutTime" BU_SG_REL_ L_ATCU_vMON SG_ 863 L_ATCU_Lib_MngrBlwBufLow1 5000;
BA_ "Version" SG_ 863 L_ATCU_Lib_MngrBlwBufLow1 "23.11.10";
BA_ "Description" SG_ 863 L_ATCU_Lib_MngrBlwBuf1 "This value only use for ATCU Library data monitoring (Only use before SOP)";
BA_ "GenSigSendType" SG_ 863 L_ATCU_Lib_MngrBlwBuf1 4;
BA_ "UserSigValidity" SG_ 863 L_ATCU_Lib_MngrBlwBuf1 0;
BA_REL_ "GenSigTimeoutTime" BU_SG_REL_ L_ATCU_vMON SG_ 863 L_ATCU_Lib_MngrBlwBuf1 5000;
BA_ "Version" SG_ 863 L_ATCU_Lib_MngrBlwBuf1 "25.05.03";
BA_ "Description" SG_ 863 L_ATCU_Lib_MngrBlwBufHi1 "This value only use for ATCU Library data monitoring (Only use before SOP)";
BA_ "GenSigSendType" SG_ 863 L_ATCU_Lib_MngrBlwBufHi1 4;
BA_ "UserSigValidity" SG_ 863 L_ATCU_Lib_MngrBlwBufHi1 0;
BA_REL_ "GenSigTimeoutTime" BU_SG_REL_ L_ATCU_vMON SG_ 863 L_ATCU_Lib_MngrBlwBufHi1 5000;
BA_ "Version" SG_ 863 L_ATCU_Lib_MngrBlwBufHi1 "23.11.10";
BA_ "Description" SG_ 863 L_ATCU_Lib_MngrBlwBufLow2 "This value only use for ATCU Library data monitoring (Only use before SOP)";
BA_ "GenSigSendType" SG_ 863 L_ATCU_Lib_MngrBlwBufLow2 4;
BA_ "UserSigValidity" SG_ 863 L_ATCU_Lib_MngrBlwBufLow2 0;
BA_REL_ "GenSigTimeoutTime" BU_SG_REL_ L_ATCU_vMON SG_ 863 L_ATCU_Lib_MngrBlwBufLow2 5000;
BA_ "Version" SG_ 863 L_ATCU_Lib_MngrBlwBufLow2 "23.11.10";
BA_ "Description" SG_ 863 L_ATCU_Lib_MngrBlwBufLow3 "This value only use for ATCU Library data monitoring (Only use before SOP)";
BA_ "GenSigSendType" SG_ 863 L_ATCU_Lib_MngrBlwBufLow3 4;
BA_ "UserSigValidity" SG_ 863 L_ATCU_Lib_MngrBlwBufLow3 0;
BA_REL_ "GenSigTimeoutTime" BU_SG_REL_ L_ATCU_vMON SG_ 863 L_ATCU_Lib_MngrBlwBufLow3 5000;
BA_ "Version" SG_ 863 L_ATCU_Lib_MngrBlwBufLow3 "23.11.10";
BA_ "Description" SG_ 863 L_ATCU_Lib_MngrBlwBufHi2 "This value only use for ATCU Library data monitoring (Only use before SOP)";
BA_ "GenSigSendType" SG_ 863 L_ATCU_Lib_MngrBlwBufHi2 4;
BA_ "UserSigValidity" SG_ 863 L_ATCU_Lib_MngrBlwBufHi2 0;
BA_REL_ "GenSigTimeoutTime" BU_SG_REL_ L_ATCU_vMON SG_ 863 L_ATCU_Lib_MngrBlwBufHi2 5000;
BA_ "Version" SG_ 863 L_ATCU_Lib_MngrBlwBufHi2 "23.11.10";
BA_ "Description" SG_ 863 L_ATCU_Lib_MngrBlwBuf2 "This value only use for ATCU Library data monitoring (Only use before SOP)";
BA_ "GenSigSendType" SG_ 863 L_ATCU_Lib_MngrBlwBuf2 4;
BA_ "UserSigValidity" SG_ 863 L_ATCU_Lib_MngrBlwBuf2 0;
BA_REL_ "GenSigTimeoutTime" BU_SG_REL_ L_ATCU_vMON SG_ 863 L_ATCU_Lib_MngrBlwBuf2 5000;
BA_ "Version" SG_ 863 L_ATCU_Lib_MngrBlwBuf2 "25.05.03";
VAL_ 97 L_2HKBD_SW_Ver1 0 "0x00~0x7E:ASCII value" 126 "0x00~0x7E:ASCII value" 127 "Invalid" ;
VAL_ 97 L_2HKBD_SW_Ver2 0 "0x00~0x7E:ASCII value" 126 "0x00~0x7E:ASCII value" 127 "Invalid" ;
VAL_ 97 L_2HKBD_SW_Ver3 0 "0x00~0x7E:ASCII value" 126 "0x00~0x7E:ASCII value" 127 "Invalid" ;
VAL_ 98 L_2HKBD_Rr_EvapVolVal 0 "0x0~0xFA:0~5V" 250 "0x0~0xFA:0~5V" 255 "Error Indicator" ;
VAL_ 98 L_2HKBD_Rr_TempActrSt 0 "Normal" 1 "Open" 2 "Short" 3 "Stuck" ;
VAL_ 98 L_2HKBD_Rr_TempAsstActrFB 1023 "Error Indicator" ;
VAL_ 98 L_2HKBD_Rr_TempAsstActrSt 0 "Normal" 1 "Open" 2 "Short" 3 "Stuck" ;
VAL_ 98 L_2HKBD_Rr_ModeActrFB 1023 "Error Indicator" ;
VAL_ 98 L_2HKBD_Rr_ModeActrSt 0 "Normal" 1 "Open" 2 "Short" 3 "Stuck" ;
VAL_ 98 L_2HKBD_Rr_BLDCError 0 "No error" 1 "Over Current" 2 "Under Voltage" 3 "Over Voltage" 4 "Stall" 5 "Over Temperature" 6 "Controller Shutdown (Internal Error)" 7 "Current Limit" 8 "Limp mode" 9 "LIN Fail" 10 "RESERVED" 11 "RESERVED" 12 "RESERVED" 13 "RESERVED" 14 "RESERVED" 15 "RESERVED" ;
VAL_ 98 L_2HKBD_Rr_TempActrFB 1023 "Error Indicator" ;
VAL_ 99 L_2HKBD_ResetOpSta 0 "Normal" 1 "Reset Complete" 2 "Reset Fail" 3 "RESERVED" ;
VAL_ 100 L_2HKBD_RrDrModeDnSw 0 "Off" 1 "On" ;
VAL_ 100 L_2HKBD_RrDrModeUpSw 0 "Off" 1 "On" ;
VAL_ 100 L_2HKBD_RrDrAutoSw 0 "Off" 1 "On" ;
VAL_ 100 L_2HKBD_Rr_OffSw 0 "Off" 1 "On" ;
VAL_ 100 L_2HKBD_RrSyncSw 0 "Off" 1 "On" ;
VAL_ 100 L_2HKBD_RrAcSw 0 "Off" 1 "On" ;
VAL_ 100 L_2HKBD_RLStHtrSwReq 0 "Off" 1 "On" ;
VAL_ 100 L_2HKBD_RLStVentSwReq 0 "Off" 1 "On" ;
VAL_ 100 L_2HKBD_RRStHtrSwReq 0 "Off" 1 "On" ;
VAL_ 100 L_2HKBD_RRStVentSwReq 0 "Off" 1 "On" ;
VAL_ 100 L_2HKBD_RrDrMultiAutoSw 0 "RESERVED" 1 "Low" 2 "Medium" 3 "High" 4 "RESERVED" 5 "RESERVED" 6 "RESERVED" 7 "Invalid" ;
VAL_ 100 L_2HKBD_RrDrModeSw 0 "Off" 1 "On" ;
VAL_ 100 L_2HKBD_RrPsModeSw 0 "Off" 1 "On" ;
VAL_ 100 L_2HKBD_RrPsModeDnSw 0 "Off" 1 "On" ;
VAL_ 100 L_2HKBD_RrPsModeUpSw 0 "Off" 1 "On" ;
VAL_ 100 L_2HKBD_RrPsModeVentSw 0 "Off" 1 "On" ;
VAL_ 100 L_2HKBD_RrPsModeFloorSw 0 "Off" 1 "On" ;
VAL_ 100 L_2HKBD_RrPsModeBiLvlSw 0 "Off" 1 "On" ;
VAL_ 100 L_2HKBD_RrPsTempDnSw 0 "Off" 1 "On" ;
VAL_ 100 L_2HKBD_RrPsTempUpSw 0 "Off" 1 "On" ;
VAL_ 100 L_2HKBD_RrPsBlwUpSw 0 "Off" 1 "On" ;
VAL_ 100 L_2HKBD_RrDRModeVentSw 0 "Off" 1 "On" ;
VAL_ 100 L_2HKBD_RrPsBlwDnSw 0 "Off" 1 "On" ;
VAL_ 100 L_2HKBD_RrPsAutoSw 0 "Off" 1 "On" ;
VAL_ 100 L_2HKBD_RrPsMultiAutoSw 0 "RESERVED" 1 "Low" 2 "Medium" 3 "High" 4 "RESERVED" 5 "RESERVED" 6 "RESERVED" 7 "Invalid" ;
VAL_ 100 L_2HKBD_RrDrBlwDnOffSw 0 "Off" 1 "On" ;
VAL_ 100 L_2HKBD_RrPsBlwDnOffSw 0 "Off" 1 "On" ;
VAL_ 100 L_2HKBD_RrOnOffSet 0 "Default" 1 "On" 2 "Off" 3 "Invalid" ;
VAL_ 100 L_2HKBD_RrDrblwUpMaxSw 0 "Off" 1 "On" ;
VAL_ 100 L_2HKBD_RrDrModeFloorSw 0 "Off" 1 "On" ;
VAL_ 100 L_2HKBD_RrPsblwUpMaxSw 0 "Off" 1 "On" ;
VAL_ 100 L_2HKBD_RrDrModeBiLvlSw 0 "Off" 1 "On" ;
VAL_ 100 L_2HKBD_RrDrTempDnSw 0 "Off" 1 "On" ;
VAL_ 100 L_2HKBD_RrDrTempUpSw 0 "Off" 1 "On" ;
VAL_ 100 L_2HKBD_RrDrBlwDnSw 0 "Off" 1 "On" ;
VAL_ 100 L_2HKBD_RrDrBlwUpSw 0 "Off" 1 "On" ;
VAL_ 101 L_2HKBD_RrFlrDuctSnsr 0 "0x0~0xFA:0~5V" 250 "0x0~0xFA:0~5V" 255 "Error Indicator" ;
VAL_ 101 L_2HKBD_RrVntDuctSnsr 0 "0x0~0xFA:0~5V" 250 "0x0~0xFA:0~5V" 255 "Error Indicator" ;
VAL_ 368 L_ATCU_AVNCluUSMReset 0 "Default" 1 "USM Reset" 2 "RESERVED" 3 "Invalid" ;
VAL_ 368 L_ATCU_HVACPnlBckLight_Set 0 "Invalid(Default)" 1 "On" 2 "Off" 3 "RESERVED" ;
VAL_ 368 L_ATCU_MasterProfileResetIndex 0 "Default" 1 "Profile 1~Profile 9" 2 "Profile 1~Profile 9" 3 "Profile 1~Profile 9" 4 "Profile 1~Profile 9" 5 "Profile 1~Profile 9" 6 "Profile 1~Profile 9" 7 "Profile 1~Profile 9" 8 "Profile 1~Profile 9" 9 "Profile 1~Profile 9" 10 "RESERVED" 11 "RESERVED" 12 "RESERVED" 13 "RESERVED" 14 "RESERVED" 15 "Invalid" ;
VAL_ 849 L_ATCU_Lib_SnsrInCarTemp 0 "0x0~0x3EB:-40.0~60.0¡É" 1003 "0x0~0x3EB:-40.0~60.0¡É" 1004 "3EC~0xFFFE:RESERVED" 65534 "3EC~0xFFFE:RESERVED" 65535 "Invalid" ;
VAL_ 849 L_ATCU_Lib_SnsrAMBTemp 0 "0x0~0x3EB:-40.0~60.0¡É" 1003 "0x0~0x3EB:-40.0~60.0¡É" 1004 "3EC~0xFFFE:RESERVED" 65534 "3EC~0xFFFE:RESERVED" 65535 "Invalid" ;
VAL_ 849 L_ATCU_Lib_SnsrDOH 0 "0x0~0x64:0~100%" 100 "0x0~0x64:0~100%" 101 "65~0xFFFE:RESERVED" 65534 "65~0xFFFE:RESERVED" 65535 "Invalid" ;
VAL_ 849 L_ATCU_Lib_SnsrEvapTemp 0 "0x0~0x258:-20.0~40.0¡É" 600 "0x0~0x258:-20.0~40.0¡É" 601 "259~0xFFFE:RESERVED" 65534 "259~0xFFFE:RESERVED" 65535 "Invalid" ;
VAL_ 850 L_ATCU_Lib_SnsrWaterTemp 0 "0x0~0x60E0:-48.00~200.00¡É" 24800 "0x0~0x60E0:-48.00~200.00¡É" 24801 "60E1~0xFFFE:RESERVED" 65534 "60E1~0xFFFE:RESERVED" 65535 "Invalid" ;
VAL_ 850 L_ATCU_Lib_SnsrFineDust 0 "0x0~0xFF:0~255" 255 "0x0~0xFF:0~255" 256 "100~0xFFFE:RESERVED" 65534 "100~0xFFFE:RESERVED" 65535 "Invalid" ;
VAL_ 850 L_ATCU_Lib_SnsrLHPhoto 0 "0x0~0x1388:0~5.000V" 5000 "0x0~0x1388:0~5.000V" 5001 "1389~0xFFFE:RESERVED" 65534 "1389~0xFFFE:RESERVED" 65535 "Invalid" ;
VAL_ 850 L_ATCU_Lib_SnsrRHPhoto 0 "0x0~0x1388:0~5.000V" 5000 "0x0~0x1388:0~5.000V" 5001 "1389~0xFFFE:RESERVED" 65534 "1389~0xFFFE:RESERVED" 65535 "Invalid" ;
VAL_ 852 L_ATCU_Lib_Snsr2LHVentDuct 0 "0x0~0x640:-40.0~160.0¡É" 1600 "0x0~0x640:-40.0~160.0¡É" 1601 "641~0xFFFE:RESERVED" 65534 "641~0xFFFE:RESERVED" 65535 "Invalid" ;
VAL_ 852 L_ATCU_Lib_Snsr2LHFloorDuct 0 "0x0~0x640:-40.0~160.0¡É" 1600 "0x0~0x640:-40.0~160.0¡É" 1601 "641~0xFFFE:RESERVED" 65534 "641~0xFFFE:RESERVED" 65535 "Invalid" ;
VAL_ 852 L_ATCU_Lib_SnsrDEFDuct 0 "0x0~0x640:-40.0~160.0¡É" 1600 "0x0~0x640:-40.0~160.0¡É" 1601 "641~0xFFFE:RESERVED" 65534 "641~0xFFFE:RESERVED" 65535 "Invalid" ;
VAL_ 853 L_ATCU_Lib_OffSw 0 "Off" 1 "On" ;
VAL_ 853 L_ATCU_Lib_AutoSw 0 "Off" 1 "On" ;
VAL_ 853 L_ATCU_Lib_BlrDnOffReq 0 "Off" 1 "On" ;
VAL_ 853 L_ATCU_Lib_IntakeRECSw 0 "Off" 1 "On" ;
VAL_ 853 L_ATCU_Lib_IntakeFRESw 0 "Off" 1 "On" ;
VAL_ 853 L_ATCU_Lib_ACSw 0 "Off" 1 "On" ;
VAL_ 853 L_ATCU_Lib_DEFSw 0 "Off" 1 "On" ;
VAL_ 853 L_ATCU_Lib_DrvTempUpSw 0 "Off" 1 "On" ;
VAL_ 853 L_ATCU_Lib_DrvTempDnSw 0 "Off" 1 "On" ;
VAL_ 853 L_ATCU_Lib_AstTempUpSw 0 "Off" 1 "On" ;
VAL_ 853 L_ATCU_Lib_AstTempDnSw 0 "Off" 1 "On" ;
VAL_ 853 L_ATCU_Lib_SyncSw 0 "Off" 1 "On" ;
VAL_ 853 L_ATCU_Lib_ModSw 0 "Off" 1 "On" ;
VAL_ 853 L_ATCU_Lib_DrvOnlySw 0 "Off" 1 "On" ;
VAL_ 853 L_ATCU_Lib_ClimateSw 0 "Off" 1 "On" ;
VAL_ 853 L_ATCU_Lib_RearDEFSw 0 "Off" 1 "On" ;
VAL_ 853 L_ATCU_Lib_StrWhlSw 0 "Off" 1 "On" ;
VAL_ 853 L_ATCU_Lib_DrvSeatHeatSw 0 "Off" 1 "On" ;
VAL_ 853 L_ATCU_Lib_DrvSeatVentSw 0 "Off" 1 "On" ;
VAL_ 853 L_ATCU_Lib_AstSeatHeatSw 0 "Off" 1 "On" ;
VAL_ 853 L_ATCU_Lib_AstSeatVentSw 0 "Off" 1 "On" ;
VAL_ 853 L_ATCU_Lib_DrvSeatTumblerSw 0 "Off" 1 "Up" 2 "Down" 3 "RESERVED" ;
VAL_ 853 L_ATCU_Lib_ModUpSw 0 "Off" 1 "On" ;
VAL_ 853 L_ATCU_Lib_AstSeatTumblerSw 0 "Off" 1 "Up" 2 "Down" 3 "RESERVED" ;
VAL_ 853 L_ATCU_Lib_2ndSyncSetSw 0 "Off" 1 "Release" 2 "Set" 3 "RESERVED" ;
VAL_ 853 L_ATCU_Lib_2ndOffSw 0 "Off" 1 "On" ;
VAL_ 853 L_ATCU_Lib_2ndLockSetSw 0 "Off" 1 "Release" 2 "Set" 3 "RESERVED" ;
VAL_ 853 L_ATCU_Lib_ModDnSw 0 "Off" 1 "On" ;
VAL_ 853 L_ATCU_Lib_BlrUpSw 0 "Off" 1 "On" ;
VAL_ 853 L_ATCU_Lib_BlrDnSw 0 "Off" 1 "On" ;
VAL_ 854 L_ATCU_Lib_OffSetSw 0 "Off" 1 "Release" 2 "Set" 3 "RESERVED" ;
VAL_ 854 L_ATCU_Lib_BlrSetSw 0 "None" 1 "1Step" 2 "2Step" 3 "3Step" 4 "4Step" 5 "5Step" 6 "6Step" 7 "7Step" 8 "8Step" 9 "DATC_Off" 10 "RESERVED" 11 "RESERVED" 12 "RESERVED" 13 "RESERVED" 14 "RESERVED" 15 "RESERVED" ;
VAL_ 854 L_ATCU_Lib_DEFSetSw 0 "Off" 1 "Release" 2 "Set" 3 "RESERVED" ;
VAL_ 854 L_ATCU_Lib_SyncSetSw 0 "Off" 1 "Release" 2 "Set" 3 "RESERVED" ;
VAL_ 854 L_ATCU_Lib_AutoSetSw 0 "Off" 1 "Release" 2 "Set" 3 "RESERVED" ;
VAL_ 854 L_ATCU_Lib_DrvOnlySetSw 0 "Off" 1 "Release" 2 "Set" 3 "RESERVED" ;
VAL_ 854 L_ATCU_Lib_IntakeSetSw 0 "FRE(0.0%)" 1 "1~0x3E7:Intake(0.1~99.9%)" 999 "1~0x3E7:Intake(0.1~99.9%)" 1000 "REC(100.0%)" 1001 "RESERVED" 1002 "RESERVED" 1003 "RESERVED" 1004 "RESERVED" 1005 "RESERVED" 1006 "RESERVED" 1007 "RESERVED" 1008 "RESERVED" 1009 "RESERVED" 1010 "RESERVED" 1011 "RESERVED" 1012 "RESERVED" 1013 "RESERVED" 1014 "RESERVED" 1015 "RESERVED" 1016 "RESERVED" 1017 "RESERVED" 1018 "RESERVED" 1019 "RESERVED" 1020 "RESERVED" 1021 "RESERVED" 1022 "RESERVED" 1023 "None" ;
VAL_ 854 L_ATCU_Lib_DrvTempSetSw 0 "Off" 1 "LO" 2 "PHY=HEX*0.5 + 14" 3 "PHY=HEX*0.5 + 14" 4 "PHY=HEX*0.5 + 14" 5 "PHY=HEX*0.5 + 14" 6 "PHY=HEX*0.5 + 14" 7 "PHY=HEX*0.5 + 14" 8 "PHY=HEX*0.5 + 14" 9 "PHY=HEX*0.5 + 14" 10 "PHY=HEX*0.5 + 14" 11 "PHY=HEX*0.5 + 14" 12 "PHY=HEX*0.5 + 14" 13 "PHY=HEX*0.5 + 14" 14 "PHY=HEX*0.5 + 14" 15 "PHY=HEX*0.5 + 14" 16 "PHY=HEX*0.5 + 14" 17 "PHY=HEX*0.5 + 14" 18 "PHY=HEX*0.5 + 14" 19 "PHY=HEX*0.5 + 14" 20 "PHY=HEX*0.5 + 14" 21 "PHY=HEX*0.5 + 14" 22 "PHY=HEX*0.5 + 14" 23 "PHY=HEX*0.5 + 14" 24 "PHY=HEX*0.5 + 14" 25 "PHY=HEX*0.5 + 14" 26 "PHY=HEX*0.5 + 14" 27 "PHY=HEX*0.5 + 14" 28 "PHY=HEX*0.5 + 14" 29 "PHY=HEX*0.5 + 14" 30 "PHY=HEX*0.5 + 14" 31 "PHY=HEX*0.5 + 14" 32 "PHY=HEX*0.5 + 14" 33 "PHY=HEX*0.5 + 14" 34 "PHY=HEX*0.5 + 14" 35 "PHY=HEX*0.5 + 14" 36 "PHY=HEX*0.5 + 14" 37 "25~0xFD:Reserved" 253 "25~0xFD:Reserved" 254 "HI" 255 "Invalid" ;
VAL_ 854 L_ATCU_Lib_MultiAutoSetSw 0 "Off" 1 "1Step" 2 "2Step" 3 "3Step" ;
VAL_ 854 L_ATCU_Lib_AstTempSetSw 0 "Off" 1 "LO" 2 "PHY=HEX*0.5 + 14" 3 "PHY=HEX*0.5 + 14" 4 "PHY=HEX*0.5 + 14" 5 "PHY=HEX*0.5 + 14" 6 "PHY=HEX*0.5 + 14" 7 "PHY=HEX*0.5 + 14" 8 "PHY=HEX*0.5 + 14" 9 "PHY=HEX*0.5 + 14" 10 "PHY=HEX*0.5 + 14" 11 "PHY=HEX*0.5 + 14" 12 "PHY=HEX*0.5 + 14" 13 "PHY=HEX*0.5 + 14" 14 "PHY=HEX*0.5 + 14" 15 "PHY=HEX*0.5 + 14" 16 "PHY=HEX*0.5 + 14" 17 "PHY=HEX*0.5 + 14" 18 "PHY=HEX*0.5 + 14" 19 "PHY=HEX*0.5 + 14" 20 "PHY=HEX*0.5 + 14" 21 "PHY=HEX*0.5 + 14" 22 "PHY=HEX*0.5 + 14" 23 "PHY=HEX*0.5 + 14" 24 "PHY=HEX*0.5 + 14" 25 "PHY=HEX*0.5 + 14" 26 "PHY=HEX*0.5 + 14" 27 "PHY=HEX*0.5 + 14" 28 "PHY=HEX*0.5 + 14" 29 "PHY=HEX*0.5 + 14" 30 "PHY=HEX*0.5 + 14" 31 "PHY=HEX*0.5 + 14" 32 "PHY=HEX*0.5 + 14" 33 "PHY=HEX*0.5 + 14" 34 "PHY=HEX*0.5 + 14" 35 "PHY=HEX*0.5 + 14" 36 "PHY=HEX*0.5 + 14" 37 "25~0xFD:Reserved" 253 "25~0xFD:Reserved" 254 "HI" 255 "Invalid" ;
VAL_ 854 L_ATCU_Lib_DrvTempClickCnt 0 "RESERVED" 1 "1~0x7F:clockwise" 127 "1~0x7F:clockwise" 128 "80~0xFE:Counterclockwise" 254 "80~0xFE:Counterclockwise" 255 "Invalid" ;
VAL_ 854 L_ATCU_Lib_AstTempClickCnt 0 "RESERVED" 1 "1~0x7F:clockwise" 127 "1~0x7F:clockwise" 128 "80~0xFE:Counterclockwise" 254 "80~0xFE:Counterclockwise" 255 "Invalid" ;
VAL_ 854 L_ATCU_Lib_ACSetSw 0 "Off" 1 "Release" 2 "Set" 3 "RESERVED" ;
VAL_ 854 L_ATCU_Lib_ModSetSw 0 "Off" 1 "Floor" 2 "Vent" 3 "BL" 4 "Def_EU" 5 "Mix" 6 "Def_Vent" 7 "All" 8 "Vent_Bleed" 9 "Floor_100" 10 "Warm_Floor" 11 "Cool_Mix" 12 "Def" 13 "RESERVED" 14 "RESERVED" 15 "None" ;
VAL_ 855 L_ATCU_Lib_2ndAutoSw 0 "Off" 1 "On" ;
VAL_ 855 L_ATCU_Lib_2ndAutoUpSw 0 "Off" 1 "On" ;
VAL_ 855 L_ATCU_Lib_2LHTempUpSw 0 "Off" 1 "On" ;
VAL_ 855 L_ATCU_Lib_2LHTempDnSw 0 "Off" 1 "On" ;
VAL_ 855 L_ATCU_Lib_2RHTempUpSw 0 "Off" 1 "On" ;
VAL_ 855 L_ATCU_Lib_2RHTempDnSw 0 "Off" 1 "On" ;
VAL_ 855 L_ATCU_Lib_2ndSyncSw 0 "Off" 1 "On" ;
VAL_ 855 L_ATCU_Lib_2ndLockSw 0 "Off" 1 "On" ;
VAL_ 855 L_ATCU_Lib_2LHSeatHeatSw 0 "Off" 1 "On" ;
VAL_ 855 L_ATCU_Lib_2LHSeatVentSw 0 "Off" 1 "On" ;
VAL_ 855 L_ATCU_Lib_2RHSeatHeatSw 0 "Off" 1 "On" ;
VAL_ 855 L_ATCU_Lib_2RHSeatVentSw 0 "Off" 1 "On" ;
VAL_ 855 L_ATCU_Lib_2ndAutoDnSw 0 "Off" 1 "On" ;
VAL_ 855 L_ATCU_Lib_2LHSeatTumblerSw 0 "Off" 1 "Up" 2 "Down" 3 "RESERVED" ;
VAL_ 855 L_ATCU_Lib_2RHSeatTumblerSw 0 "Off" 1 "Up" 2 "Down" 3 "RESERVED" ;
VAL_ 855 L_ATCU_Lib_2ndOffSetSw 0 "Off" 1 "Release" 2 "Set" 3 "RESERVED" ;
VAL_ 855 L_ATCU_Lib_2ndAutoSetSw 0 "Off" 1 "Release" 2 "Set" 3 "RESERVED" ;
VAL_ 855 L_ATCU_Lib_2ndMultiAutoSetSw 0 "Off" 1 "1Step" 2 "2Step" 3 "3Step" ;
VAL_ 855 L_ATCU_Lib_2LHModSw 0 "Off" 1 "On" ;
VAL_ 855 L_ATCU_Lib_2ndACSetSw 0 "Off" 1 "Release" 2 "Set" 3 "RESERVED" ;
VAL_ 855 L_ATCU_Lib_2LHModSetSw 0 "Off" 1 "Floor" 2 "Vent" 3 "BL" 4 "Def_EU" 5 "Mix" 6 "Def_Vent" 7 "All" 8 "Vent_Bleed" 9 "Floor_100" 10 "Warm_Floor" 11 "Cool_Mix" 12 "Def" 13 "RESERVED" 14 "RESERVED" 15 "None" ;
VAL_ 855 L_ATCU_Lib_2LHBlrSetSw 0 "None" 1 "1Step" 2 "2Step" 3 "3Step" 4 "4Step" 5 "5Step" 6 "6Step" 7 "7Step" 8 "8Step" 9 "DATC_Off" 10 "RESERVED" 11 "RESERVED" 12 "RESERVED" 13 "RESERVED" 14 "RESERVED" 15 "RESERVED" ;
VAL_ 855 L_ATCU_Lib_2LHModUpSw 0 "Off" 1 "On" ;
VAL_ 855 L_ATCU_Lib_2LHTempSetSw 0 "Off" 1 "LO" 2 "PHY=HEX*0.5 + 14" 3 "PHY=HEX*0.5 + 14" 4 "PHY=HEX*0.5 + 14" 5 "PHY=HEX*0.5 + 14" 6 "PHY=HEX*0.5 + 14" 7 "PHY=HEX*0.5 + 14" 8 "PHY=HEX*0.5 + 14" 9 "PHY=HEX*0.5 + 14" 10 "PHY=HEX*0.5 + 14" 11 "PHY=HEX*0.5 + 14" 12 "PHY=HEX*0.5 + 14" 13 "PHY=HEX*0.5 + 14" 14 "PHY=HEX*0.5 + 14" 15 "PHY=HEX*0.5 + 14" 16 "PHY=HEX*0.5 + 14" 17 "PHY=HEX*0.5 + 14" 18 "PHY=HEX*0.5 + 14" 19 "PHY=HEX*0.5 + 14" 20 "PHY=HEX*0.5 + 14" 21 "PHY=HEX*0.5 + 14" 22 "PHY=HEX*0.5 + 14" 23 "PHY=HEX*0.5 + 14" 24 "PHY=HEX*0.5 + 14" 25 "PHY=HEX*0.5 + 14" 26 "PHY=HEX*0.5 + 14" 27 "PHY=HEX*0.5 + 14" 28 "PHY=HEX*0.5 + 14" 29 "PHY=HEX*0.5 + 14" 30 "PHY=HEX*0.5 + 14" 31 "PHY=HEX*0.5 + 14" 32 "PHY=HEX*0.5 + 14" 33 "PHY=HEX*0.5 + 14" 34 "PHY=HEX*0.5 + 14" 35 "PHY=HEX*0.5 + 14" 36 "PHY=HEX*0.5 + 14" 37 "25~0xFD:Reserved" 253 "25~0xFD:Reserved" 254 "HI" 255 "Invalid" ;
VAL_ 855 L_ATCU_Lib_2RHTempSetSw 0 "Off" 1 "LO" 2 "PHY=HEX*0.5 + 14" 3 "PHY=HEX*0.5 + 14" 4 "PHY=HEX*0.5 + 14" 5 "PHY=HEX*0.5 + 14" 6 "PHY=HEX*0.5 + 14" 7 "PHY=HEX*0.5 + 14" 8 "PHY=HEX*0.5 + 14" 9 "PHY=HEX*0.5 + 14" 10 "PHY=HEX*0.5 + 14" 11 "PHY=HEX*0.5 + 14" 12 "PHY=HEX*0.5 + 14" 13 "PHY=HEX*0.5 + 14" 14 "PHY=HEX*0.5 + 14" 15 "PHY=HEX*0.5 + 14" 16 "PHY=HEX*0.5 + 14" 17 "PHY=HEX*0.5 + 14" 18 "PHY=HEX*0.5 + 14" 19 "PHY=HEX*0.5 + 14" 20 "PHY=HEX*0.5 + 14" 21 "PHY=HEX*0.5 + 14" 22 "PHY=HEX*0.5 + 14" 23 "PHY=HEX*0.5 + 14" 24 "PHY=HEX*0.5 + 14" 25 "PHY=HEX*0.5 + 14" 26 "PHY=HEX*0.5 + 14" 27 "PHY=HEX*0.5 + 14" 28 "PHY=HEX*0.5 + 14" 29 "PHY=HEX*0.5 + 14" 30 "PHY=HEX*0.5 + 14" 31 "PHY=HEX*0.5 + 14" 32 "PHY=HEX*0.5 + 14" 33 "PHY=HEX*0.5 + 14" 34 "PHY=HEX*0.5 + 14" 35 "PHY=HEX*0.5 + 14" 36 "PHY=HEX*0.5 + 14" 37 "25~0xFD:Reserved" 253 "25~0xFD:Reserved" 254 "HI" 255 "Invalid" ;
VAL_ 855 L_ATCU_Lib_2LHModDnSw 0 "Off" 1 "On" ;
VAL_ 855 L_ATCU_Lib_DrvBlrClickCnt 0 "RESERVED" 1 "1~0x7F:clockwise" 127 "1~0x7F:clockwise" 128 "80~0xFE:Counterclockwise" 254 "80~0xFE:Counterclockwise" 255 "Invalid" ;
VAL_ 855 L_ATCU_Lib_2LHBlrUpSw 0 "Off" 1 "On" ;
VAL_ 855 L_ATCU_Lib_2LHBlrDnSw 0 "Off" 1 "On" ;
VAL_ 855 L_ATCU_Lib_2LHBlrDnOffReq 0 "Off" 1 "On" ;
VAL_ 855 L_ATCU_Lib_2ndACSw 0 "Off" 1 "On" ;
VAL_ 856 L_ATCU_Lib_AutoStepInd 0 "Off" 1 "1Step" 2 "2Step" 3 "3Step" ;
VAL_ 856 L_ATCU_Lib_BlrSym 0 "Off" 1 "On" ;
VAL_ 856 L_ATCU_Lib_BlrStepSym 0 "Off" 1 "1Step" 2 "2Step" 3 "3Step" 4 "4Step" 5 "5Step" 6 "6Step" 7 "7Step" 8 "8Step" 9 "RESERVED" 10 "RESERVED" 11 "RESERVED" 12 "RESERVED" 13 "RESERVED" 14 "RESERVED" 15 "RESERVED" ;
VAL_ 856 L_ATCU_Lib_IntakeRECInd 0 "Off" 1 "On" ;
VAL_ 856 L_ATCU_Lib_IntakeFREInd 0 "Off" 1 "On" ;
VAL_ 856 L_ATCU_Lib_ACInd 0 "Off" 1 "On" ;
VAL_ 856 L_ATCU_Lib_DEFInd 0 "Off" 1 "On" ;
VAL_ 856 L_ATCU_Lib_SyncInd 0 "Off" 1 "On" ;
VAL_ 856 L_ATCU_Lib_AutoBlrStepSym 0 "Off" 1 "Low" 2 "Mid" 3 "High" ;
VAL_ 856 L_ATCU_Lib_DrvOnly 0 "Off" 1 "On" ;
VAL_ 856 L_ATCU_Lib_ADSSym 0 "Off" 1 "On" ;
VAL_ 856 L_ATCU_Lib_ModVentInd 0 "Off" 1 "On" ;
VAL_ 856 L_ATCU_Lib_DrvTempSym 0 "Off" 1 "01~0xA4:RESERVED" 164 "01~0xA4:RESERVED" 165 "A5~0x10E:16.5~27.0¡É" 270 "A5~0x10E:16.5~27.0¡É" 271 "10F~0x261:RESERVED" 609 "10F~0x261:RESERVED" 610 "262~0x334:61~82£Æ" 820 "262~0x334:61~82£Æ" 821 "335~0xFFFF:RESERVED" 65535 "335~0xFFFF:RESERVED" ;
VAL_ 856 L_ATCU_Lib_ModSym 0 "Off" 1 "Floor" 2 "Vent" 3 "BL" 4 "Def_EU" 5 "Mix" 6 "Def_Vent" 7 "All" 8 "RESERVED" 9 "RESERVED" 10 "RESERVED" 11 "RESERVED" 12 "Def" 13 "RESERVED" 14 "RESERVED" 15 "None" ;
VAL_ 856 L_ATCU_Lib_AstTempSym 0 "Off" 1 "01~0xA4:RESERVED" 164 "01~0xA4:RESERVED" 165 "A5~0x10E:16.5~27.0¡É" 270 "A5~0x10E:16.5~27.0¡É" 271 "10F~0x261:RESERVED" 609 "10F~0x261:RESERVED" 610 "262~0x334:61~82£Æ" 820 "262~0x334:61~82£Æ" 821 "335~0xFFFF:RESERVED" 65535 "335~0xFFFF:RESERVED" ;
VAL_ 856 L_ATCU_Lib_DrvTempUnitSym 0 "Off" 1 "Celsius" 2 "Fahrenheit" 3 "RESERVED" ;
VAL_ 856 L_ATCU_Lib_ModFloorInd 0 "Off" 1 "On" ;
VAL_ 856 L_ATCU_Lib_ModDEFInd 0 "Off" 1 "On" ;
VAL_ 857 L_ATCU_Lib_2LHAutoStepInd 0 "Off" 1 "1Step" 2 "2Step" 3 "3Step" ;
VAL_ 857 L_ATCU_Lib_2ndACInd 0 "Off" 1 "On" ;
VAL_ 857 L_ATCU_Lib_2ndSyncInd 0 "Off" 1 "On" ;
VAL_ 857 L_ATCU_Lib_2ndLockInd 0 "Off" 1 "On" ;
VAL_ 857 L_ATCU_Lib_2LHBlrSym 0 "Off" 1 "On" ;
VAL_ 857 L_ATCU_Lib_2LHTempSym 0 "Off" 1 "01~0xA4:RESERVED" 164 "01~0xA4:RESERVED" 165 "A5~0x10E:16.5~27.0¡É" 270 "A5~0x10E:16.5~27.0¡É" 271 "10F~0x261:RESERVED" 609 "10F~0x261:RESERVED" 610 "262~0x334:61~82£Æ" 820 "262~0x334:61~82£Æ" 821 "335~0xFFFF:RESERVED" 65535 "335~0xFFFF:RESERVED" ;
VAL_ 857 L_ATCU_Lib_2LHAutoBlrStepSym 0 "Off" 1 "Low" 2 "Mid" 3 "High" ;
VAL_ 857 L_ATCU_Lib_2LHTempUnit 0 "Off" 1 "Celsius" 2 "Fahrenheit" ;
VAL_ 857 L_ATCU_Lib_2LHModSym 0 "Off" 1 "Floor" 2 "Vent" 3 "BL" 4 "Def_EU" 5 "Mix" 6 "Def_Vent" 7 "All" 8 "RESERVED" 9 "RESERVED" 10 "RESERVED" 11 "RESERVED" 12 "Def" 13 "RESERVED" 14 "RESERVED" 15 "None" ;
VAL_ 857 L_ATCU_Lib_FineDustTreeSym 0 "Off" 1 "Wood" ;
VAL_ 857 L_ATCU_Lib_FineDustTreeColor 0 "Off" 1 "Mono" 2 "Blue" 3 "Green" 4 "Orange" 5 "Red" 6 "Yellow" 7 "White" 8 "RESERVED" 9 "RESERVED" 10 "RESERVED" 11 "RESERVED" 12 "RESERVED" 13 "RESERVED" 14 "Gray" 15 "RESERVED" ;
VAL_ 857 L_ATCU_Lib_FineDustBarStepSym 0 "Off" 1 "Blank" 2 "Good" 3 "Normal" 4 "Poor" 5 "VeryPoor" 6 "RESERVED" 7 "RESERVED" ;
VAL_ 857 L_ATCU_Lib_2RHTempSym 0 "Off" 1 "01~0xA4:RESERVED" 164 "01~0xA4:RESERVED" 165 "A5~0x10E:16.5~27.0¡É" 270 "A5~0x10E:16.5~27.0¡É" 271 "10F~0x261:RESERVED" 609 "10F~0x261:RESERVED" 610 "262~0x334:61~82£Æ" 820 "262~0x334:61~82£Æ" 821 "335~0xFFFF:RESERVED" 65535 "335~0xFFFF:RESERVED" ;
VAL_ 857 L_ATCU_Lib_2LHBlrStepSym 0 "Off" 1 "1Step" 2 "2Step" 3 "3Step" 4 "4Step" 5 "5Step" 6 "6Step" 7 "7Step" 8 "8Step" 9 "RESERVED" 10 "RESERVED" 11 "RESERVED" 12 "RESERVED" 13 "RESERVED" 14 "RESERVED" 15 "RESERVED" ;
VAL_ 858 L_ATCU_Lib_USMDEFState 0 "NotApply" 1 "Off" 2 "On" 3 "Invalid" ;
VAL_ 858 L_ATCU_Lib_USMSmrtVentState 0 "NotApply" 1 "Off" 2 "On" 3 "Invalid" ;
VAL_ 858 L_ATCU_Lib_USMCoolHeatSeat 0 "NotApply" 1 "Off" 2 "On" 3 "Invalid" ;
VAL_ 858 L_ATCU_Lib_USMStrWhlHeater 0 "NotApply" 1 "Off" 2 "On" 3 "Invalid" ;
VAL_ 858 L_ATCU_Lib_USMUsrPrfleState 0 "Default" 1 "Guest" 2 "Profile1" 3 "Profile2" 4 "RESERVED" 5 "RESERVED" 6 "RESERVED" 7 "RESERVED" 8 "RESERVED" 9 "RESERVED" 10 "RESERVED" 11 "RESERVED" 12 "RESERVED" 13 "RESERVED" 14 "RESERVED" 15 "Invalid" ;
VAL_ 858 L_ATCU_Lib_USMAutoFreshState 0 "NotApply" 1 "Off" 2 "On" 3 "Invalid" ;
VAL_ 858 L_ATCU_Lib_USM2ndAutoOffState 0 "NotApply" 1 "Off" 2 "On" 3 "Invalid" ;
VAL_ 858 L_ATCU_Lib_USMRearLock 0 "NotApply" 1 "Off" 2 "On" 3 "Invalid" ;
VAL_ 858 L_ATCU_Lib_USMWshState 0 "NotApply" 1 "Off" 2 "On" 3 "Invalid" ;
VAL_ 858 L_ATCU_Lib_USMADSState 0 "NotApply" 1 "Off" 2 "On" 3 "Invalid" ;
VAL_ 858 L_ATCU_Lib_USMTempUnitState 0 "Off" 1 "Celsius" 2 "Fahrenheit" 3 "Invalid" ;
VAL_ 858 L_ATCU_Lib_USMAfterBlowState 0 "NotApply" 1 "Off" 2 "On" 3 "Invalid" ;
VAL_ 858 L_ATCU_Lib_USMSchdldVent 0 "NotApply" 1 "Off" 2 "On" 3 "Invalid" ;
VAL_ 859 L_ATCU_Lib_Opt2LHModSwTyp 0 "Mode1Btn" 1 "Mode2Btn" 2 "Mode3Btn" 3 "RESERVED" ;
VAL_ 859 L_ATCU_Lib_Opt2ndModBtn 0 "Single" 1 "Dual" 2 "Off" 3 "RESERVED" ;
VAL_ 859 L_ATCU_Lib_Opt2ndOffSwTyp 0 "OffSw" 1 "OnOffSw" 2 "BlrDnOff" 3 "RESERVED" ;
VAL_ 859 L_ATCU_Lib_Opt2ndTmpBtn 0 "Single" 1 "Dual" 2 "Off" 3 "RESERVED" ;
VAL_ 859 L_ATCU_Lib_OptADS 0 "NotApply" 1 "Apply" ;
VAL_ 859 L_ATCU_Lib_OptAfterBlow 0 "NotApply" 1 "Apply" ;
VAL_ 859 L_ATCU_Lib_OptAutoStep 0 "NotApply" 1 "1Step" 2 "2Step" 3 "3Step" ;
VAL_ 859 L_ATCU_Lib_Opt2ndAutoBtn 0 "Single" 1 "Dual" 2 "Off" 3 "RESERVED" ;
VAL_ 859 L_ATCU_Lib_OptAutoSwTyp 0 "Auto1Btn" 1 "Auto2Btn" ;
VAL_ 859 L_ATCU_Lib_OptBATCoolingTyp 0 "AirCooling" 1 "WaterCooling" 2 "NotApply" 3 "RESERVED" ;
VAL_ 859 L_ATCU_Lib_OptBlrSwKnob 0 "ButtonType" 1 "KnobType" ;
VAL_ 859 L_ATCU_Lib_OptComp 0 "Internal_Comp" 1 "External_Comp_withClutch" 2 "External_Comp_withoutClutch" 3 "Fixed_Comp" 4 "Electric_Comp" 5 "RESERVED" 6 "RESERVED" 7 "RESERVED" ;
VAL_ 859 L_ATCU_Lib_OptDrvHndSide 0 "LHD" 1 "RHD" ;
VAL_ 859 L_ATCU_Lib_OptDrvOnly 0 "NotApply" 1 "Apply" ;
VAL_ 859 L_ATCU_Lib_OptFineDust 0 "NotApply" 1 "Apply" ;
VAL_ 859 L_ATCU_Lib_OptCoolHeatSeat 0 "NotApply" 1 "1Step" 2 "2Step" 3 "3Step" ;
VAL_ 859 L_ATCU_Lib_OptPTCTyp 0 "High_Vtg" 1 "Low_Vtg" 2 "NotApply" 3 "RESERVED" ;
VAL_ 859 L_ATCU_Lib_OptLCDDisp 0 "NotApply" 1 "MonoSeg" 2 "ColorSeg" 3 "TFT" ;
VAL_ 859 L_ATCU_Lib_OptModSwTyp 0 "Mode1Btn" 1 "Mode2Btn" 2 "Mode3Btn" 3 "RESERVED" ;
VAL_ 859 L_ATCU_Lib_OptOffSwTyp 0 "OffSw" 1 "OnOffSw" 2 "BlrDnOff" 3 "RESERVED" ;
VAL_ 859 L_ATCU_Lib_Opt2ndAutoStep 0 "NotApply" 1 "1Step" 2 "2Step" 3 "3Step" ;
VAL_ 859 L_ATCU_Lib_OptNetworkTyp 0 "CAN_Master" 1 "3Gen" 2 "2Gen" 3 "RESERVED" 4 "RESERVED" 5 "RESERVED" 6 "RESERVED" 7 "RESERVED" ;
VAL_ 859 L_ATCU_Lib_OptPTCStep 0 "PTC1Step" 1 "PTC2Step" 2 "RESERVED" 3 "RESERVED" ;
VAL_ 859 L_ATCU_Lib_OptPTG 0 "NotApply" 1 "Apply" ;
VAL_ 859 L_ATCU_Lib_OptROATyp 0 "NotApply" 1 "Apply" ;
VAL_ 859 L_ATCU_Lib_OptVRLED 0 "NotApply" 1 "Apply" ;
VAL_ 859 L_ATCU_Lib_OptRgn 0 "DOM" 1 "GEN" 2 "MID" 3 "EU" 4 "AUS" 5 "CAN" 6 "NA" 7 "CHN" 8 "RUS" 9 "IND" 10 "BZL" 11 "MEX" 12 "RESERVED" 13 "RESERVED" 14 "RESERVED" 15 "RESERVED" ;
VAL_ 859 L_ATCU_Lib_OptSchdldVent 0 "NotApply" 1 "Apply" ;
VAL_ 859 L_ATCU_Lib_OptIntakeSwTyp 0 "Intake1Btn" 1 "Intake2Btn" ;
VAL_ 859 L_ATCU_Lib_OptStrHeat 0 "NotApply" 1 "1Step" 2 "2Step" 3 "RESERVED" ;
VAL_ 859 L_ATCU_Lib_OptSync 0 "NotApply" 1 "Apply" ;
VAL_ 859 L_ATCU_Lib_OptTempSwKnob 0 "ButtonType" 1 "KnobType" ;
VAL_ 859 L_ATCU_Lib_OptThermostat 0 "NotApply" 1 "Apply" ;
VAL_ 859 L_ATCU_Lib_OptVehTyp 0 "Gasoline" 1 "Diesel" 2 "LPI" 3 "HEV" 4 "PHEV" 5 "EV" 6 "FCEV" 7 "RESERVED" ;
VAL_ 859 L_ATCU_Lib_Opt2ndAutoSwTyp 0 "Auto1Btn" 1 "Auto2Btn" ;
VAL_ 859 L_ATCU_Lib_OptWheelDrivePos 0 "Front" 1 "Rear" 2 "4WD" 3 "RESERVED" ;
VAL_ 859 L_ATCU_Lib_Opt2ndTempSwKnob 0 "ButtonType" 1 "KnobType" ;
VAL_ 859 L_ATCU_Lib_Opt2ndBlrBtn 0 "Single" 1 "Dual" 2 "Off" 3 "RESERVED" ;
VAL_ 861 L_ATCU_Lib_MngrModBufOp 0 "KeyOff" 1 "FloorPurge" 2 "RemoteFATC" 3 "RemoteFATC_DEF" 4 "SMKRemoteFATC" 5 "ManualSw_DEF" 6 "ManualSw" 7 "MaxCool" 8 "HotStart" 9 "ADS" 10 "FootZone" 11 "MaxHot" 12 "SchdldVent" 13 "AfterBlow" 14 "Auto" 15 "Num" 16 "RESERVED" 17 "RESERVED" 18 "RESERVED" 19 "RESERVED" 20 "RESERVED" 21 "RESERVED" 22 "RESERVED" 23 "RESERVED" 24 "RESERVED" 25 "RESERVED" 26 "RESERVED" 27 "RESERVED" 28 "RESERVED" 29 "RESERVED" 30 "RESERVED" 31 "RESERVED" ;
VAL_ 861 L_ATCU_Lib_MngrDEFBufOp 0 "KeyOff" 1 "FloorPuge" 2 "Mode" 3 "Num" 4 "RESERVED" 5 "RESERVED" 6 "RESERVED" 7 "RESERVED" ;
VAL_ 861 L_ATCU_Lib_MngrBlwBufOp 0 "StartBlower" 1 "SmartVentForcedOn" 2 "SmartVent" 3 "MaxCool" 4 "HotStart" 5 "MaxHot" 6 "ManualSw" 7 "SchdldVent" 8 "AfterBlow" 9 "Auto" 10 "Num" 11 "RESERVED" 12 "RESERVED" 13 "RESERVED" 14 "RESERVED" 15 "RESERVED" ;
VAL_ 861 L_ATCU_Lib_MngrACBufOp 0 "DEF" 1 "RemoteFATC_DEF" 2 "SMKRemoteFATC" 3 "Washer" 4 "MIX" 5 "AirPurify" 6 "ADS" 7 "ManualSw" 8 "MAXCool" 9 "Auto" 10 "Num" 11 "RESERVED" 12 "RESERVED" 13 "RESERVED" 14 "RESERVED" 15 "RESERVED" ;
VAL_ 861 L_ATCU_Lib_2LHMngrBlwBufOp 0 "StartBlower" 1 "MaxCool" 2 "HotStart" 3 "MaxHot" 4 "ManualSw" 5 "Auto" 6 "Num" 7 "RESERVED" 8 "RESERVED" 9 "RESERVED" 10 "RESERVED" 11 "RESERVED" 12 "RESERVED" 13 "RESERVED" 14 "RESERVED" 15 "RESERVED" ;
VAL_ 861 L_ATCU_Lib_2LHMngrModBufOp 0 "KeyOff" 1 "FloorPurge" 2 "ManualSw" 3 "MaxCool" 4 "HotStart" 5 "FootZone" 6 "MaxHot" 7 "Auto" 8 "Num" 9 "RESERVED" 10 "RESERVED" 11 "RESERVED" 12 "RESERVED" 13 "RESERVED" 14 "RESERVED" 15 "RESERVED" ;
VAL_ 861 L_ATCU_Lib_2LHMngrTempBufOp 0 "MaxCool" 1 "MaxHot" 2 "Auto" 3 "Num" 4 "RESERVED" 5 "RESERVED" 6 "RESERVED" 7 "RESERVED" ;
VAL_ 861 L_ATCU_Lib_2RHMngrTempBufOp 0 "MaxCool" 1 "MaxHot" 2 "Auto" 3 "Num" 4 "RESERVED" 5 "RESERVED" 6 "RESERVED" 7 "RESERVED" ;
VAL_ 861 L_ATCU_Lib_MngrActvIncarMotPwr 0 "Off" 1 "On" ;
VAL_ 861 L_ATCU_Lib_MngrPDCWakeUpReq 0 "Off" 1 "On" ;
VAL_ 861 L_ATCU_Lib_MngrLVPTCRly1Sta 0 "Off" 1 "On" ;
VAL_ 861 L_ATCU_Lib_MngrLVPTCRly2Sta 0 "Off" 1 "On" ;
VAL_ 861 L_ATCU_Lib_MngrLVPTCRly3Sta 0 "Off" 1 "On" ;
VAL_ 861 L_ATCU_Lib_MngrTempBufOp 0 "MaxCool" 1 "MaxHot" 2 "Last" 3 "AfterBlow" 4 "Auto" 5 "Num" 6 "RESERVED" 7 "RESERVED" ;
VAL_ 861 L_ATCU_Lib_MngrIntakeBufOp 0 "KeyOff" 1 "SmartVencForcedOn" 2 "RemoteFATC" 3 "RemoteFATC_DEF" 4 "AutoWash" 5 "Washer" 6 "ADS" 7 "Sunroof" 8 "Tunnel" 9 "AirPurify" 10 "DEF" 11 "MIX" 12 "FloorPurge" 13 "AQS_REC" 14 "AQS_FRE" 15 "FREbyTime" 16 "protectEvapRust" 17 "ManualSw_FRE" 18 "ManualSw_REC" 19 "SmrtVent" 20 "SysOff" 21 "MaxHot" 22 "MaxCool" 23 "StayMod" 24 "SchdldVent" 25 "AfterBlow" 26 "Auto_REC" 27 "Auto_FRE" 28 "Num" 29 "RESERVED" 30 "RESERVED" 31 "RESERVED" ;
VAL_ 862 L_ATCU_Lib_MngrModBuf0 0 "KeyOff" 1 "RemoteFATC" 2 "RemoteFATC_DEF" 3 "SMKRemoteFATC" 4 "ManualSw_DEF" 5 "ManualSw" 6 "MaxCool" 7 "HotStart" 8 "ADS" 9 "FootZone" 10 "MaxHot" 11 "SchdldVent" 12 "AfterBlow" 13 "Auto" 14 "Num" 16 "RESERVED" 17 "RESERVED" 18 "RESERVED" 19 "RESERVED" 20 "RESERVED" 21 "RESERVED" 22 "RESERVED" 23 "RESERVED" 24 "RESERVED" 25 "RESERVED" 26 "RESERVED" 27 "RESERVED" 28 "RESERVED" 29 "RESERVED" 30 "RESERVED" 31 "RESERVED" ;
VAL_ 862 L_ATCU_Lib_MngrModBufLow1 0 "PECbyFLR" 1 "QuickFog" 2 "Num" 3 "RESERVED" ;
VAL_ 862 L_ATCU_Lib_MngrModBuf2 0 "KeyOff" 1 "RemoteFATC" 2 "RemoteFATC_DEF" 3 "SMKRemoteFATC" 4 "ManualSw_DEF" 5 "ManualSw" 6 "MaxCool" 7 "HotStart" 8 "ADS" 9 "FootZone" 10 "MaxHot" 11 "SchdldVent" 12 "AfterBlow" 13 "Auto" 14 "Num" 16 "RESERVED" 17 "RESERVED" 18 "RESERVED" 19 "RESERVED" 20 "RESERVED" 21 "RESERVED" 22 "RESERVED" 23 "RESERVED" 24 "RESERVED" 25 "RESERVED" 26 "RESERVED" 27 "RESERVED" 28 "RESERVED" 29 "RESERVED" 30 "RESERVED" 31 "RESERVED" ;
VAL_ 862 L_ATCU_Lib_MngrModBufHi0 0 "PECbyFLR" 1 "QuickFog" 2 "Num" 3 "RESERVED" ;
VAL_ 862 L_ATCU_Lib_MngrModBuf3 0 "KeyOff" 1 "RemoteFATC" 2 "RemoteFATC_DEF" 3 "SMKRemoteFATC" 4 "ManualSw_DEF" 5 "ManualSw" 6 "MaxCool" 7 "HotStart" 8 "ADS" 9 "FootZone" 10 "MaxHot" 11 "SchdldVent" 12 "AfterBlow" 13 "Auto" 14 "Num" 16 "RESERVED" 17 "RESERVED" 18 "RESERVED" 19 "RESERVED" 20 "RESERVED" 21 "RESERVED" 22 "RESERVED" 23 "RESERVED" 24 "RESERVED" 25 "RESERVED" 26 "RESERVED" 27 "RESERVED" 28 "RESERVED" 29 "RESERVED" 30 "RESERVED" 31 "RESERVED" ;
VAL_ 862 L_ATCU_Lib_MngrModBufHi1 0 "PECbyFLR" 1 "QuickFog" 2 "Num" 3 "RESERVED" ;
VAL_ 862 L_ATCU_Lib_MngrModBuf4 0 "KeyOff" 1 "RemoteFATC" 2 "RemoteFATC_DEF" 3 "SMKRemoteFATC" 4 "ManualSw_DEF" 5 "ManualSw" 6 "MaxCool" 7 "HotStart" 8 "ADS" 9 "FootZone" 10 "MaxHot" 11 "SchdldVent" 12 "AfterBlow" 13 "Auto" 14 "Num" 16 "RESERVED" 17 "RESERVED" 18 "RESERVED" 19 "RESERVED" 20 "RESERVED" 21 "RESERVED" 22 "RESERVED" 23 "RESERVED" 24 "RESERVED" 25 "RESERVED" 26 "RESERVED" 27 "RESERVED" 28 "RESERVED" 29 "RESERVED" 30 "RESERVED" 31 "RESERVED" ;
VAL_ 862 L_ATCU_Lib_MngrModBuf5 0 "KeyOff" 1 "RemoteFATC" 2 "RemoteFATC_DEF" 3 "SMKRemoteFATC" 4 "ManualSw_DEF" 5 "ManualSw" 6 "MaxCool" 7 "HotStart" 8 "ADS" 9 "FootZone" 10 "MaxHot" 11 "SchdldVent" 12 "AfterBlow" 13 "Auto" 14 "Num" 16 "RESERVED" 17 "RESERVED" 18 "RESERVED" 19 "RESERVED" 20 "RESERVED" 21 "RESERVED" 22 "RESERVED" 23 "RESERVED" 24 "RESERVED" 25 "RESERVED" 26 "RESERVED" 27 "RESERVED" 28 "RESERVED" 29 "RESERVED" 30 "RESERVED" 31 "RESERVED" ;
VAL_ 862 L_ATCU_Lib_MngrModBuf6 0 "KeyOff" 1 "RemoteFATC" 2 "RemoteFATC_DEF" 3 "SMKRemoteFATC" 4 "ManualSw_DEF" 5 "ManualSw" 6 "MaxCool" 7 "HotStart" 8 "ADS" 9 "FootZone" 10 "MaxHot" 11 "SchdldVent" 12 "AfterBlow" 13 "Auto" 14 "Num" 16 "RESERVED" 17 "RESERVED" 18 "RESERVED" 19 "RESERVED" 20 "RESERVED" 21 "RESERVED" 22 "RESERVED" 23 "RESERVED" 24 "RESERVED" 25 "RESERVED" 26 "RESERVED" 27 "RESERVED" 28 "RESERVED" 29 "RESERVED" 30 "RESERVED" 31 "RESERVED" ;
VAL_ 862 L_ATCU_Lib_MngrModBufLow0 0 "PECbyFLR" 1 "QuickFog" 2 "Num" 3 "RESERVED" ;
VAL_ 862 L_ATCU_Lib_MngrModBuf7 0 "KeyOff" 1 "RemoteFATC" 2 "RemoteFATC_DEF" 3 "SMKRemoteFATC" 4 "ManualSw_DEF" 5 "ManualSw" 6 "MaxCool" 7 "HotStart" 8 "ADS" 9 "FootZone" 10 "MaxHot" 11 "SchdldVent" 12 "AfterBlow" 13 "Auto" 14 "Num" 16 "RESERVED" 17 "RESERVED" 18 "RESERVED" 19 "RESERVED" 20 "RESERVED" 21 "RESERVED" 22 "RESERVED" 23 "RESERVED" 24 "RESERVED" 25 "RESERVED" 26 "RESERVED" 27 "RESERVED" 28 "RESERVED" 29 "RESERVED" 30 "RESERVED" 31 "RESERVED" ;
VAL_ 862 L_ATCU_Lib_MngrModBuf1 0 "KeyOff" 1 "RemoteFATC" 2 "RemoteFATC_DEF" 3 "SMKRemoteFATC" 4 "ManualSw_DEF" 5 "ManualSw" 6 "MaxCool" 7 "HotStart" 8 "ADS" 9 "FootZone" 10 "MaxHot" 11 "SchdldVent" 12 "AfterBlow" 13 "Auto" 14 "Num" 16 "RESERVED" 17 "RESERVED" 18 "RESERVED" 19 "RESERVED" 20 "RESERVED" 21 "RESERVED" 22 "RESERVED" 23 "RESERVED" 24 "RESERVED" 25 "RESERVED" 26 "RESERVED" 27 "RESERVED" 28 "RESERVED" 29 "RESERVED" 30 "RESERVED" 31 "RESERVED" ;
VAL_ 863 L_ATCU_Lib_MngrBlwBuf0 0 "SmartVentForcedOn" 1 "SmartVent" 2 "MaxCool" 3 "HotStart" 4 "MaxHot" 5 "ManualSw" 6 "SchdldVent" 7 "AfterBlow" 8 "Auto" 9 "Num" 11 "RESERVED" 12 "RESERVED" 13 "RESERVED" 14 "RESERVED" 15 "RESERVED" ;
VAL_ 863 L_ATCU_Lib_MngrBlwBuf3 0 "SmartVentForcedOn" 1 "SmartVent" 2 "MaxCool" 3 "HotStart" 4 "MaxHot" 5 "ManualSw" 6 "SchdldVent" 7 "AfterBlow" 8 "Auto" 9 "Num" 11 "RESERVED" 12 "RESERVED" 13 "RESERVED" 14 "RESERVED" 15 "RESERVED" ;
VAL_ 863 L_ATCU_Lib_MngrBlwBuf4 0 "SmartVentForcedOn" 1 "SmartVent" 2 "MaxCool" 3 "HotStart" 4 "MaxHot" 5 "ManualSw" 6 "SchdldVent" 7 "AfterBlow" 8 "Auto" 9 "Num" 11 "RESERVED" 12 "RESERVED" 13 "RESERVED" 14 "RESERVED" 15 "RESERVED" ;
VAL_ 863 L_ATCU_Lib_MngrBlwBuf5 0 "SmartVentForcedOn" 1 "SmartVent" 2 "MaxCool" 3 "HotStart" 4 "MaxHot" 5 "ManualSw" 6 "SchdldVent" 7 "AfterBlow" 8 "Auto" 9 "Num" 11 "RESERVED" 12 "RESERVED" 13 "RESERVED" 14 "RESERVED" 15 "RESERVED" ;
VAL_ 863 L_ATCU_Lib_MngrBlwBuf6 0 "SmartVentForcedOn" 1 "SmartVent" 2 "MaxCool" 3 "HotStart" 4 "MaxHot" 5 "ManualSw" 6 "SchdldVent" 7 "AfterBlow" 8 "Auto" 9 "Num" 11 "RESERVED" 12 "RESERVED" 13 "RESERVED" 14 "RESERVED" 15 "RESERVED" ;
VAL_ 863 L_ATCU_Lib_MngrBlwBuf7 0 "SmartVentForcedOn" 1 "SmartVent" 2 "MaxCool" 3 "HotStart" 4 "MaxHot" 5 "ManualSw" 6 "SchdldVent" 7 "AfterBlow" 8 "Auto" 9 "Num" 11 "RESERVED" 12 "RESERVED" 13 "RESERVED" 14 "RESERVED" 15 "RESERVED" ;
VAL_ 863 L_ATCU_Lib_MngrBlwBufHi0 0 "AirFlowLinkage" 1 "ISG" 2 "SSC" 3 "Num" ;
VAL_ 863 L_ATCU_Lib_MngrBlwBufLow0 0 "RemoteFATC" 1 "DEF" 2 "AirPurify" 3 "ADS" 4 "Num" 5 "RESERVED" 6 "RESERVED" 7 "RESERVED" ;
VAL_ 863 L_ATCU_Lib_MngrBlwBufLow1 0 "RemoteFATC" 1 "DEF" 2 "AirPurify" 3 "ADS" 4 "Num" 5 "RESERVED" 6 "RESERVED" 7 "RESERVED" ;
VAL_ 863 L_ATCU_Lib_MngrBlwBuf1 0 "SmartVentForcedOn" 1 "SmartVent" 2 "MaxCool" 3 "HotStart" 4 "MaxHot" 5 "ManualSw" 6 "SchdldVent" 7 "AfterBlow" 8 "Auto" 9 "Num" 11 "RESERVED" 12 "RESERVED" 13 "RESERVED" 14 "RESERVED" 15 "RESERVED" ;
VAL_ 863 L_ATCU_Lib_MngrBlwBufHi1 0 "AirFlowLinkage" 1 "ISG" 2 "SSC" 3 "Num" ;
VAL_ 863 L_ATCU_Lib_MngrBlwBufLow2 0 "RemoteFATC" 1 "DEF" 2 "AirPurify" 3 "ADS" 4 "Num" 5 "RESERVED" 6 "RESERVED" 7 "RESERVED" ;
VAL_ 863 L_ATCU_Lib_MngrBlwBufLow3 0 "RemoteFATC" 1 "DEF" 2 "AirPurify" 3 "ADS" 4 "Num" 5 "RESERVED" 6 "RESERVED" 7 "RESERVED" ;
VAL_ 863 L_ATCU_Lib_MngrBlwBufHi2 0 "AirFlowLinkage" 1 "ISG" 2 "SSC" 3 "Num" ;
VAL_ 863 L_ATCU_Lib_MngrBlwBuf2 0 "SmartVentForcedOn" 1 "SmartVent" 2 "MaxCool" 3 "HotStart" 4 "MaxHot" 5 "ManualSw" 6 "SchdldVent" 7 "AfterBlow" 8 "Auto" 9 "Num" 11 "RESERVED" 12 "RESERVED" 13 "RESERVED" 14 "RESERVED" 15 "RESERVED" ;
